VERSION "June 2, 2025"

NS_ :

BS_:

BU_: VEH CH Receiver Receiver ChassisBus VehicleBus PartyBus

BO_ 12 UI_status: 8 VehicleBus
 SG_ UI_audioActive : 1|1@1+ (1,0) [0|1] ""  Receiver
 SG_ UI_autopilotTrial : 12|2@1+ (1,0) [0|3] ""  Receiver
 SG_ UI_bluetoothActive : 2|1@1+ (1,0) [0|1] ""  Receiver
 SG_ UI_cameraActive : 41|1@1+ (1,0) [0|1] ""  Receiver
 SG_ UI_cellActive : 3|1@1+ (1,0) [0|1] ""  Receiver
 SG_ UI_cellConnected : 10|1@1+ (1,0) [0|1] ""  Receiver
 SG_ UI_cellNetworkTechnology : 19|4@1+ (1,0) [0|15] ""  Receiver
 SG_ UI_cellReceiverPower : 24|8@1+ (1,-128) [-128|127] "dB"  Receiver
 SG_ UI_cellSignalBars : 42|3@1+ (1,0) [0|7] ""  Receiver
 SG_ UI_cpuTemperature : 56|8@1- (1,40) [-20|100] "C"  Receiver
 SG_ UI_developmentCar : 40|1@1+ (1,0) [0|1] ""  Receiver
 SG_ UI_displayOn : 5|1@1+ (1,0) [0|1] ""  Receiver
 SG_ UI_displayReady : 4|1@1+ (1,0) [0|1] ""  Receiver
 SG_ UI_factoryReset : 14|2@1+ (1,0) [0|3] ""  Receiver
 SG_ UI_falseTouchCounter : 32|8@1+ (1,0) [0|255] "1"  Receiver
 SG_ UI_gpsActive : 16|1@1+ (1,0) [0|1] ""  Receiver
 SG_ UI_pcbTemperature : 48|8@1- (1,40) [-20|100] "C"  Receiver
 SG_ UI_radioActive : 18|1@1+ (1,0) [0|1] ""  Receiver
 SG_ UI_readyForDrive : 9|1@1+ (1,0) [0|1] ""  Receiver
 SG_ UI_screenshotActive : 17|1@1+ (1,0) [0|1] ""  Receiver
 SG_ UI_systemActive : 8|1@1+ (1,0) [0|1] ""  Receiver
 SG_ UI_touchActive : 0|1@1+ (1,0) [0|1] ""  Receiver
 SG_ UI_vpnActive : 11|1@1+ (1,0) [0|1] ""  Receiver
 SG_ UI_wifiActive : 6|1@1+ (1,0) [0|1] ""  Receiver
 SG_ UI_wifiConnected : 7|1@1+ (1,0) [0|1] ""  Receiver

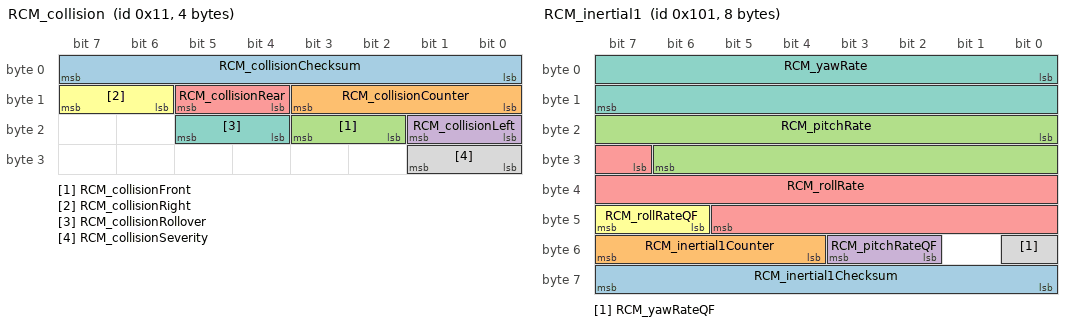
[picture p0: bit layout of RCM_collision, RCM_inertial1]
BO_ 17 RCM_collision: 4 VEH
 SG_ RCM_collisionChecksum : 0|8@1+ (1,0) [0|0] "" Vector__XXX
 SG_ RCM_collisionCounter : 8|4@1+ (1,0) [0|0] "" Vector__XXX
 SG_ RCM_collisionFront : 18|2@1+ (1,0) [0|0] "" Vector__XXX
 SG_ RCM_collisionLeft : 16|2@1+ (1,0) [0|0] "" Vector__XXX
 SG_ RCM_collisionRear : 12|2@1+ (1,0) [0|0] "" Vector__XXX
 SG_ RCM_collisionRight : 14|2@1+ (1,0) [0|0] "" Vector__XXX
 SG_ RCM_collisionRollover : 20|2@1+ (1,0) [0|0] "" Vector__XXX
 SG_ RCM_collisionSeverity : 24|2@1+ (1,0) [0|0] "" Vector__XXX

BO_ 22 DI_bmsRequest: 1 VEH
 SG_ DI_bmsOpenContactorsRequest : 4|1@1+ (1,0) [0|1] ""  Receiver
 SG_ DI_bmsRequestInterfaceVersion : 0|4@1+ (1,0) [0|15] ""  Receiver

BO_ 60 GTW_info: 8 VEH
 SG_ GTW_infoIndex M : 0|8@1+ (1,0) [0|0] "" Vector__XXX
 SG_ GTW_applicationGitHash m17 : 10|54@1+ (4,0) [0|0] "" Vector__XXX
 SG_ GTW_buildType m10 : 8|3@1+ (1,0) [0|0] "" Vector__XXX
 SG_ GTW_hardwareId m10 : 32|16@1+ (1,0) [0|0] "" Vector__XXX
 SG_ GTW_bootGitHash m18 : 10|54@1+ (4,0) [0|0] "" Vector__XXX
 SG_ GTW_bootCrc m20 : 32|32@1+ (1,0) [0|0] "" Vector__XXX
 SG_ GTW_platformType m13 : 8|8@1+ (1,0) [0|0] "" Vector__XXX
 SG_ GTW_appCrc m13 : 32|32@1+ (1,0) [0|0] "" Vector__XXX

BO_ 62 GTW_alertMatrix: 8 VEH
 SG_ GTW_matrixIndex M : 0|4@1+ (1,0) [0|0] "" Vector__XXX
 SG_ GTW_w000_GTW_ALERT_DO_NOT_USE m0 : 4|1@1+ (1,0) [0|0] "" Vector__XXX
 SG_ GTW_w001_canVEHTxQueue m0 : 5|1@1+ (1,0) [0|0] "" Vector__XXX
 SG_ GTW_w002_taskError m0 : 6|1@1+ (1,0) [0|0] "" Vector__XXX
 SG_ GTW_w003_logWriteRecord m0 : 7|1@1+ (1,0) [0|0] "" Vector__XXX
 SG_ GTW_w004_mallocHook m0 : 8|1@1+ (1,0) [0|0] "" Vector__XXX
 SG_ GTW_w005_stackOverflowHook m0 : 9|1@1+ (1,0) [0|0] "" Vector__XXX
 SG_ GTW_w006_ifTxOutputFull m0 : 10|1@1+ (1,0) [0|0] "" Vector__XXX
 SG_ GTW_w007_ifRxBufError m0 : 11|1@1+ (1,0) [0|0] "" Vector__XXX
 SG_ GTW_w008_ifPbufAllocError m0 : 12|1@1+ (1,0) [0|0] "" Vector__XXX
 SG_ GTW_w009_lateTask m0 : 13|1@1+ (1,0) [0|0] "" Vector__XXX
 SG_ GTW_w010_wdTaskCount m0 : 14|1@1+ (1,0) [0|0] "" Vector__XXX
 SG_ GTW_w011_cancoreWatchdog m0 : 15|1@1+ (1,0) [0|0] "" Vector__XXX
 SG_ GTW_w012_maincoreWatchdog m0 : 16|1@1+ (1,0) [0|0] "" Vector__XXX
 SG_ GTW_w014_APSversionMismatch m0 : 17|1@1+ (1,0) [0|0] "" Vector__XXX
 SG_ GTW_w015_DISversionMismatch m0 : 18|1@1+ (1,0) [0|0] "" Vector__XXX
 SG_ GTW_w016_BLEEPversionMismatch m0 : 19|1@1+ (1,0) [0|0] "" Vector__XXX
 SG_ GTW_w017_BMSversionMismatch m0 : 20|1@1+ (1,0) [0|0] "" Vector__XXX
 SG_ GTW_w018_CMPversionMismatch m0 : 21|1@1+ (1,0) [0|0] "" Vector__XXX
 SG_ GTW_w019_CPversionMismatch m0 : 22|1@1+ (1,0) [0|0] "" Vector__XXX
 SG_ GTW_w020_DIversionMismatch m0 : 23|1@1+ (1,0) [0|0] "" Vector__XXX
 SG_ GTW_w021_EPAS3PversionMismatch m0 : 24|1@1+ (1,0) [0|0] "" Vector__XXX
 SG_ GTW_w022_EPBLversionMismatch m0 : 25|1@1+ (1,0) [0|0] "" Vector__XXX
 SG_ GTW_w023_EPBRversionMismatch m0 : 26|1@1+ (1,0) [0|0] "" Vector__XXX
 SG_ GTW_w024_ESPversionMismatch m0 : 27|1@1+ (1,0) [0|0] "" Vector__XXX
 SG_ GTW_w025_ESPCALversionMismatch m0 : 28|1@1+ (1,0) [0|0] "" Vector__XXX
 SG_ GTW_w026_GTWversionMismatch m0 : 29|1@1+ (1,0) [0|0] "" Vector__XXX
 SG_ GTW_w027_HVPversionMismatch m0 : 30|1@1+ (1,0) [0|0] "" Vector__XXX
 SG_ GTW_w028_IBSTversionMismatch m0 : 31|1@1+ (1,0) [0|0] "" Vector__XXX
 SG_ GTW_w029_IBSTCALversionMismatch m0 : 32|1@1+ (1,0) [0|0] "" Vector__XXX
 SG_ GTW_w030_OCS1PversionMismatch m0 : 33|1@1+ (1,0) [0|0] "" Vector__XXX
 SG_ GTW_w031_PARKversionMismatch m0 : 34|1@1+ (1,0) [0|0] "" Vector__XXX
 SG_ GTW_w032_PCSversionMismatch m0 : 35|1@1+ (1,0) [0|0] "" Vector__XXX
 SG_ GTW_w033_PCSCPU2versionMismatch m0 : 36|1@1+ (1,0) [0|0] "" Vector__XXX
 SG_ GTW_w034_PMversionMismatch m0 : 37|1@1+ (1,0) [0|0] "" Vector__XXX
 SG_ GTW_w035_PMSversionMismatch m0 : 38|1@1+ (1,0) [0|0] "" Vector__XXX
 SG_ GTW_w036_PTCversionMismatch m0 : 39|1@1+ (1,0) [0|0] "" Vector__XXX
 SG_ GTW_w037_RADCversionMismatch m0 : 40|1@1+ (1,0) [0|0] "" Vector__XXX
 SG_ GTW_w038_RCMversionMismatch m0 : 41|1@1+ (1,0) [0|0] "" Vector__XXX
 SG_ GTW_w039_RCMCALversionMismatch m0 : 42|1@1+ (1,0) [0|0] "" Vector__XXX
 SG_ GTW_w040_SCCMversionMismatch m0 : 43|1@1+ (1,0) [0|0] "" Vector__XXX
 SG_ GTW_w041_VCSECversionMismatch m0 : 44|1@1+ (1,0) [0|0] "" Vector__XXX
 SG_ GTW_w042_TASversionMismatch m0 : 45|1@1+ (1,0) [0|0] "" Vector__XXX
 SG_ GTW_w043_THSversionMismatch m0 : 46|1@1+ (1,0) [0|0] "" Vector__XXX
 SG_ GTW_w044_TPMSversionMismatch m0 : 47|1@1+ (1,0) [0|0] "" Vector__XXX
 SG_ GTW_w045_VCFRONTversionMismatch m0 : 48|1@1+ (1,0) [0|0] "" Vector__XXX
 SG_ GTW_w046_VCLEFTversionMismatch m0 : 49|1@1+ (1,0) [0|0] "" Vector__XXX
 SG_ GTW_w047_VCRIGHTversionMismatch m0 : 50|1@1+ (1,0) [0|0] "" Vector__XXX
 SG_ GTW_w048_EPAS3SversionMismatch m0 : 51|1@1+ (1,0) [0|0] "" Vector__XXX
 SG_ GTW_w049_corruptedManifest m0 : 52|1@1+ (1,0) [0|0] "" Vector__XXX
 SG_ GTW_w050_sdCardInitFailure m0 : 53|1@1+ (1,0) [0|0] "" Vector__XXX
 SG_ GTW_w051_sdCardFileSystemFailure m0 : 54|1@1+ (1,0) [0|0] "" Vector__XXX
 SG_ GTW_w052_ifTxSpans m0 : 55|1@1+ (1,0) [0|0] "" Vector__XXX
 SG_ GTW_w053_busSleepFailure m0 : 56|1@1+ (1,0) [0|0] "" Vector__XXX
 SG_ GTW_w054_OPCversionMismatch m0 : 57|1@1+ (1,0) [0|0] "" Vector__XXX
 SG_ GTW_w055_OPCSversionMismatch m0 : 58|1@1+ (1,0) [0|0] "" Vector__XXX
 SG_ GTW_w057_i2cFailure m0 : 59|1@1+ (1,0) [0|0] "" Vector__XXX
 SG_ GTW_w058_rtcAlarmFailure m0 : 60|1@1+ (1,0) [0|0] "" Vector__XXX
 SG_ GTW_w059_inFactoryMode m0 : 61|1@1+ (1,0) [0|0] "" Vector__XXX
 SG_ GTW_w060_unFused m0 : 62|1@1+ (1,0) [0|0] "" Vector__XXX
 SG_ GTW_w061_bmpSleepFailure m0 : 63|1@1+ (1,0) [0|0] "" Vector__XXX
 SG_ GTW_w062_bmpWatchdog m1 : 4|1@1+ (1,0) [0|0] "" Vector__XXX
 SG_ GTW_w063_VEH_canFault m1 : 5|1@1+ (1,0) [0|0] "" Vector__XXX
 SG_ GTW_w064_CH_canFault m1 : 6|1@1+ (1,0) [0|0] "" Vector__XXX
 SG_ GTW_w065_PARTY_canFault m1 : 7|1@1+ (1,0) [0|0] "" Vector__XXX
 SG_ GTW_w066_exception m1 : 8|1@1+ (1,0) [0|0] "" Vector__XXX
 SG_ GTW_w067_tcpDebug m1 : 9|1@1+ (1,0) [0|0] "" Vector__XXX
 SG_ GTW_w068_prodKeyMissing m1 : 10|1@1+ (1,0) [0|0] "" Vector__XXX
 SG_ GTW_w069_diskioErr m1 : 11|1@1+ (1,0) [0|0] "" Vector__XXX
 SG_ GTW_w070_hrlDump m1 : 12|1@1+ (1,0) [0|0] "" Vector__XXX
 SG_ GTW_w071_hrlTrigger m1 : 13|1@1+ (1,0) [0|0] "" Vector__XXX
 SG_ GTW_w072_updateFailure m1 : 14|1@1+ (1,0) [0|0] "" Vector__XXX
 SG_ GTW_w073_steeringWheelReset m1 : 15|1@1+ (1,0) [0|0] "" Vector__XXX
 SG_ GTW_w074_epas3pMIA m1 : 16|1@1+ (1,0) [0|0] "" Vector__XXX
 SG_ GTW_w075_epas3sMIA m1 : 17|1@1+ (1,0) [0|0] "" Vector__XXX
 SG_ GTW_w076_VEHInterfaceReset m1 : 18|1@1+ (1,0) [0|0] "" Vector__XXX
 SG_ GTW_w077_bmpPmicError m1 : 19|1@1+ (1,0) [0|0] "" Vector__XXX
 SG_ GTW_w078_VEHbusOverloaded m1 : 20|1@1+ (1,0) [0|0] "" Vector__XXX
 SG_ GTW_w079_PARTYbusOverloaded m1 : 21|1@1+ (1,0) [0|0] "" Vector__XXX
 SG_ GTW_w080_CHbusOverloaded m1 : 22|1@1+ (1,0) [0|0] "" Vector__XXX
 SG_ GTW_w081_udsMessageRejected m1 : 23|1@1+ (1,0) [0|0] "" Vector__XXX
 SG_ GTW_w082_sdCardBSCorrupted m1 : 24|1@1+ (1,0) [0|0] "" Vector__XXX
 SG_ GTW_w083_udsMsgDroppedByTcpStack m1 : 25|1@1+ (1,0) [0|0] "" Vector__XXX
 SG_ GTW_w084_canFrameDropped m1 : 26|1@1+ (1,0) [0|0] "" Vector__XXX
 SG_ GTW_w085_iBoosterStuck m1 : 27|1@1+ (1,0) [0|0] "" Vector__XXX
 SG_ GTW_w086_ocu m1 : 28|1@1+ (1,0) [0|0] "" Vector__XXX
 SG_ GTW_w087_ocuInProgress m1 : 29|1@1+ (1,0) [0|0] "" Vector__XXX
 SG_ GTW_w088_sdCardInvReqParallel m1 : 30|1@1+ (1,0) [0|0] "" Vector__XXX
 SG_ GTW_w089_sdCardWatchdog m1 : 31|1@1+ (1,0) [0|0] "" Vector__XXX
 SG_ GTW_w090_ocuFailed m1 : 32|1@1+ (1,0) [0|0] "" Vector__XXX
 SG_ GTW_w091_lowStack m1 : 33|1@1+ (1,0) [0|0] "" Vector__XXX
 SG_ GTW_w092_sdCardInvReqZero m1 : 34|1@1+ (1,0) [0|0] "" Vector__XXX
 SG_ GTW_w093_sdCardInvReqOverflowBase m1 : 35|1@1+ (1,0) [0|0] "" Vector__XXX
 SG_ GTW_w094_sdCardInvReqOverflowCount m1 : 36|1@1+ (1,0) [0|0] "" Vector__XXX
 SG_ GTW_w095_sdCardFull m1 : 37|1@1+ (1,0) [0|0] "" Vector__XXX
 SG_ GTW_w096_sdCardFatCorrupted m1 : 38|1@1+ (1,0) [0|0] "" Vector__XXX
 SG_ GTW_w097_HCMLversionMismatch m1 : 39|1@1+ (1,0) [0|0] "" Vector__XXX
 SG_ GTW_w098_HCMRversionMismatch m1 : 40|1@1+ (1,0) [0|0] "" Vector__XXX
 SG_ GTW_w099_SWCversionMismatch m1 : 41|1@1+ (1,0) [0|0] "" Vector__XXX
 SG_ GTW_w100_CBCversionMismatch m1 : 42|1@1+ (1,0) [0|0] "" Vector__XXX
 SG_ GTW_w101_switchWatchdog m1 : 43|1@1+ (1,0) [0|0] "" Vector__XXX
 SG_ GTW_w103_sdCardFormatted m1 : 44|1@1+ (1,0) [0|0] "" Vector__XXX
 SG_ GTW_w104_sdCardDriverArgCorrupted m1 : 45|1@1+ (1,0) [0|0] "" Vector__XXX
 SG_ GTW_w105_eBuckConfigured m1 : 46|1@1+ (1,0) [0|0] "" Vector__XXX
 SG_ GTW_w106_failedToStartUpdater m1 : 47|1@1+ (1,0) [0|0] "" Vector__XXX

BO_ 79 UI_locationStatus: 8 CH
 SG_ UI_gpsAccuracy : 57|7@1+ (0.2,0) [0|0] "m" Vector__XXX
 SG_ UI_gpslatitude : 0|28@1- (1e-06,0) [0|0] "deg" Vector__XXX
 SG_ UI_gpslongitude : 28|29@1- (1e-06,0) [0|0] "deg" Vector__XXX

BO_ 130 UI_tripPlanning: 8 VEH
 SG_ UI_energyAtDestination : 48|16@1- (0.01,0) [-327.67|327.67] "kWh" Vector__XXX
 SG_ UI_hindsightEnergy : 32|16@1- (0.01,0) [-327.67|327.67] "kWh" Vector__XXX
 SG_ UI_navToSupercharger : 1|1@1+ (1,0) [0|1] "" Vector__XXX
 SG_ UI_predictedEnergy : 16|16@1- (0.01,0) [-327.67|327.67] "kWh" Vector__XXX
 SG_ UI_requestActiveBatteryHeating : 2|1@1+ (1,0) [0|1] "" Vector__XXX
 SG_ UI_tripPlanningActive : 0|1@1+ (1,0) [0|1] "" Vector__XXX

BO_ 139 UI_tripPlanning2: 6 VEH
 SG_ UI_maxSpeedToReachDestination : 0|16@1+ (0.01,0) [0|655.34] "m/s" Vector__XXX
 SG_ UI_remainingWeightedRMSSpeed : 16|16@1+ (0.01,0) [0|655.34] "m/s" Vector__XXX
 SG_ UI_timeToDestination : 32|16@1+ (1,0) [0|65534] "s" Vector__XXX

BO_ 257 RCM_inertial1: 8 CH
 SG_ RCM_inertial1Checksum : 56|8@1+ (1,0) [0|0] "" Vector__XXX
 SG_ RCM_inertial1Counter : 52|4@1+ (1,0) [0|0] "" Vector__XXX
 SG_ RCM_pitchRate : 16|15@1- (0.00025,0) [0|0] "rad/s" Vector__XXX
 SG_ RCM_pitchRateQF : 50|2@1+ (1,0) [0|0] "" Vector__XXX
 SG_ RCM_rollRate : 31|15@1- (0.00025,0) [0|0] "rad/s" Vector__XXX
 SG_ RCM_rollRateQF : 46|2@1+ (1,0) [0|0] "" Vector__XXX
 SG_ RCM_yawRate : 0|16@1- (0.0001,0) [0|0] "rad/s" Vector__XXX
 SG_ RCM_yawRateQF : 48|1@1+ (1,0) [0|0] "" Vector__XXX

BO_ 258 VCLEFT_doorStatus: 8 VEH
 SG_ VCLEFT_frontHandlePWM : 16|7@1+ (1,0) [0|0] "%" Vector__XXX
 SG_ VCLEFT_frontHandlePulled : 10|1@1+ (1,0) [0|0] "" Vector__XXX
 SG_ VCLEFT_frontHandlePulledPersist : 62|1@1+ (1,0) [0|0] "" Vector__XXX
 SG_ VCLEFT_frontIntSwitchPressed : 31|1@1+ (1,0) [0|0] "" Vector__XXX
 SG_ VCLEFT_frontLatchStatus : 0|4@1+ (1,0) [0|0] "" Vector__XXX
 SG_ VCLEFT_frontLatchSwitch : 8|1@1+ (1,0) [0|0] "" Vector__XXX
 SG_ VCLEFT_frontRelActuatorSwitch : 12|1@1+ (1,0) [0|0] "" Vector__XXX
 SG_ VCLEFT_mirrorDipped : 61|1@1+ (1,0) [0|0] "" Vector__XXX
 SG_ VCLEFT_mirrorFoldState : 52|3@1+ (1,0) [0|0] "" Vector__XXX
 SG_ VCLEFT_mirrorHeatState : 58|3@1+ (1,0) [0|0] "" Vector__XXX
 SG_ VCLEFT_mirrorRecallState : 55|3@1+ (1,0) [0|0] "" Vector__XXX
 SG_ VCLEFT_mirrorState : 49|3@1+ (1,0) [0|0] "" Vector__XXX
 SG_ VCLEFT_mirrorTiltXPosition : 33|8@1+ (0.02,0) [0|0] "V" Vector__XXX
 SG_ VCLEFT_mirrorTiltYPosition : 41|8@1+ (0.02,0) [0|0] "V" Vector__XXX
 SG_ VCLEFT_rearHandlePWM : 24|7@1+ (1,0) [0|0] "%" Vector__XXX
 SG_ VCLEFT_rearHandlePulled : 11|1@1+ (1,0) [0|0] "" Vector__XXX
 SG_ VCLEFT_rearIntSwitchPressed : 32|1@1+ (1,0) [0|0] "" Vector__XXX
 SG_ VCLEFT_rearLatchStatus : 4|4@1+ (1,0) [0|0] "" Vector__XXX
 SG_ VCLEFT_rearLatchSwitch : 9|1@1+ (1,0) [0|0] "" Vector__XXX
 SG_ VCLEFT_rearRelActuatorSwitch : 13|1@1+ (1,0) [0|0] "" Vector__XXX

BO_ 259 VCRIGHT_doorStatus: 8 VEH
 SG_ VCRIGHT_frontHandlePWM : 14|7@1+ (1,0) [0|0] "%" Vector__XXX
 SG_ VCRIGHT_frontHandlePulled : 10|1@1+ (1,0) [0|0] "" Vector__XXX
 SG_ VCRIGHT_frontHandlePulledPersist : 30|1@1+ (1,0) [0|0] "" Vector__XXX
 SG_ VCRIGHT_frontIntSwitchPressed : 31|1@1+ (1,0) [0|0] "" Vector__XXX
 SG_ VCRIGHT_frontLatchStatus : 0|4@1+ (1,0) [0|0] "" Vector__XXX
 SG_ VCRIGHT_frontLatchSwitch : 8|1@1+ (1,0) [0|0] "" Vector__XXX
 SG_ VCRIGHT_frontRelActuatorSwitch : 12|1@1+ (1,0) [0|0] "" Vector__XXX
 SG_ VCRIGHT_mirrorDipped : 63|1@1+ (1,0) [0|0] "" Vector__XXX
 SG_ VCRIGHT_mirrorFoldState : 52|3@1+ (1,0) [0|0] "" Vector__XXX
 SG_ VCRIGHT_mirrorRecallState : 60|3@1+ (1,0) [0|0] "" Vector__XXX
 SG_ VCRIGHT_mirrorState : 49|3@1+ (1,0) [0|0] "" Vector__XXX
 SG_ VCRIGHT_mirrorTiltXPosition : 33|8@1+ (0.02,0) [0|0] "V" Vector__XXX
 SG_ VCRIGHT_mirrorTiltYPosition : 41|8@1+ (0.02,0) [0|0] "V" Vector__XXX
 SG_ VCRIGHT_rearHandlePWM : 21|7@1+ (1,0) [0|0] "%" Vector__XXX
 SG_ VCRIGHT_rearHandlePulled : 11|1@1+ (1,0) [0|0] "" Vector__XXX
 SG_ VCRIGHT_rearIntSwitchPressed : 32|1@1+ (1,0) [0|0] "" Vector__XXX
 SG_ VCRIGHT_rearLatchStatus : 4|4@1+ (1,0) [0|0] "" Vector__XXX
 SG_ VCRIGHT_rearLatchSwitch : 9|1@1+ (1,0) [0|0] "" Vector__XXX
 SG_ VCRIGHT_rearRelActuatorSwitch : 13|1@1+ (1,0) [0|0] "" Vector__XXX
 SG_ VCRIGHT_reservedForBackCompat : 28|2@1+ (1,0) [0|0] "" Vector__XXX
 SG_ VCRIGHT_trunkLatchStatus : 56|4@1+ (1,0) [0|0] "" Vector__XXX

BO_ 264 DI_torque: 8 VEH
 SG_ DI_axleSpeed : 40|16@1- (0.1,0) [0|0] "RPM" Vector__XXX
 SG_ DI_torqueActual : 27|13@1- (2,0) [0|0] "Nm" Vector__XXX
 SG_ DI_torqueChecksum : 0|8@1+ (1,0) [0|0] "" Vector__XXX
 SG_ DI_torqueCommand : 12|13@1- (2,0) [0|0] "Nm" Vector__XXX
 SG_ DI_torqueCounter : 8|4@1+ (1,0) [0|0] "" Vector__XXX
 SG_ DI_slavePedalPos : 56|8@1+ (0.4,0) [0|100] "%" Vector__XXX

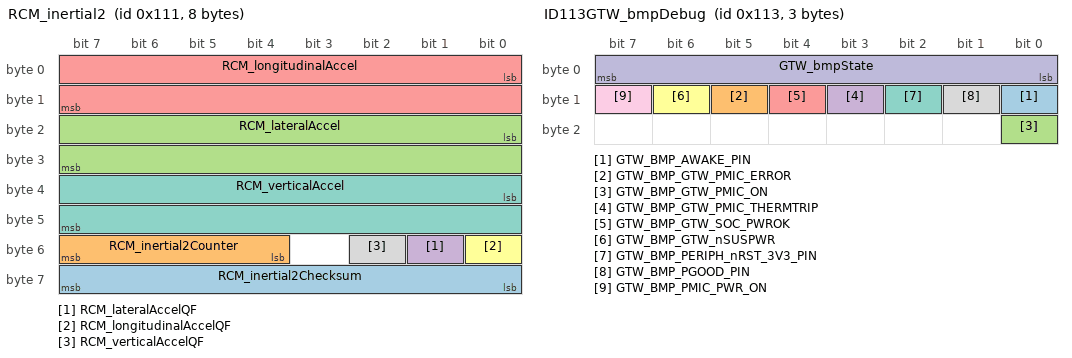
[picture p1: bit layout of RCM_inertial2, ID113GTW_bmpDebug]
BO_ 273 RCM_inertial2: 8 CH
 SG_ RCM_inertial2Checksum : 56|8@1+ (1,0) [0|255] "" Vector__XXX
 SG_ RCM_inertial2Counter : 52|4@1+ (1,0) [0|15] "" Vector__XXX
 SG_ RCM_lateralAccel : 16|16@1- (0.00125,0) [-40.9575|40.9575] "m/s^2" Vector__XXX
 SG_ RCM_lateralAccelQF : 49|1@1+ (1,0) [0|1] "" Vector__XXX
 SG_ RCM_longitudinalAccel : 0|16@1- (0.00125,0) [-40.9575|40.9575] "m/s^2" Vector__XXX
 SG_ RCM_longitudinalAccelQF : 48|1@1+ (1,0) [0|1] "" Vector__XXX
 SG_ RCM_verticalAccel : 32|16@1- (0.00125,0) [-40.9575|40.9575] "m/s^2" Vector__XXX
 SG_ RCM_verticalAccelQF : 50|1@1+ (1,0) [0|1] "" Vector__XXX

BO_ 274 GTW_adc1: 8 VEH
 SG_ GTW_1V1_VEH : 24|12@0+ (1,0) [0|0] "mV" Vector__XXX
 SG_ GTW_1V5_VEH : 32|12@0+ (1,0) [0|0] "mV" Vector__XXX
 SG_ GTW_3V3_VEH : 0|12@0+ (1.03,0) [0|0] "mV" Vector__XXX
 SG_ GTW_3V3_SW : 8|12@0+ (1.5,0) [0|0] "mV" Vector__XXX
 SG_ GTW_5V0_SW : 48|12@0+ (2,0) [0|0] "mV" Vector__XXX

BO_ 275 ID113GTW_bmpDebug: 3 VehicleBus
 SG_ GTW_BMP_AWAKE_PIN : 8|1@1+ (1,0) [0|1] ""  Receiver
 SG_ GTW_BMP_GTW_PMIC_ERROR : 13|1@1+ (1,0) [0|1] ""  Receiver
 SG_ GTW_BMP_GTW_PMIC_ON : 16|1@1+ (1,0) [0|1] ""  Receiver
 SG_ GTW_BMP_GTW_PMIC_THERMTRIP : 11|1@1+ (1,0) [0|1] ""  Receiver
 SG_ GTW_BMP_GTW_SOC_PWROK : 12|1@1+ (1,0) [0|1] ""  Receiver
 SG_ GTW_BMP_GTW_nSUSPWR : 14|1@1+ (1,0) [0|1] ""  Receiver
 SG_ GTW_BMP_PERIPH_nRST_3V3_PIN : 10|1@1+ (1,0) [0|1] ""  Receiver
 SG_ GTW_BMP_PGOOD_PIN : 9|1@1+ (1,0) [0|1] ""  Receiver
 SG_ GTW_BMP_PMIC_PWR_ON : 15|1@1+ (1,0) [0|1] ""  Receiver
 SG_ GTW_bmpState : 7|8@0+ (1,0) [0|255] ""  Receiver

BO_ 276 GTW_adc3: 8 VEH
 SG_ GTW_1V2_CSI : 24|12@0+ (1,0) [0|0] "mV" Vector__XXX
 SG_ GTW_1V8_VID : 8|12@0+ (1,0) [0|0] "mV" Vector__XXX
 SG_ GTW_1V8_VIO : 0|12@0+ (2,0) [0|0] "mV" Vector__XXX
 SG_ GTW_3V3_BMP : 32|12@0+ (2,0) [0|0] "mV" Vector__XXX
 SG_ GTW_GSM_BRD_REV : 48|12@0+ (1,0) [0|0] "mV" Vector__XXX

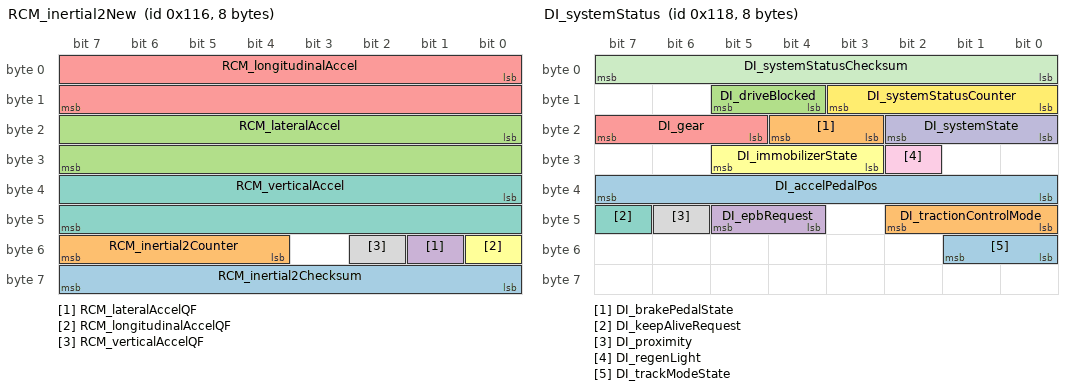
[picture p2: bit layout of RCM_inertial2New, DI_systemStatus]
BO_ 278 RCM_inertial2New: 8 CH
 SG_ RCM_inertial2Checksum : 56|8@1+ (1,0) [0|255] ""  Receiver
 SG_ RCM_inertial2Counter : 52|4@1+ (1,0) [0|15] ""  Receiver
 SG_ RCM_lateralAccel : 16|16@1- (0.00125,0) [-40.9575|40.9575] "m/s^2"  Receiver
 SG_ RCM_lateralAccelQF : 49|1@1+ (1,0) [0|1] ""  Receiver
 SG_ RCM_longitudinalAccel : 0|16@1- (0.00125,0) [-40.9575|40.9575] "m/s^2"  Receiver
 SG_ RCM_longitudinalAccelQF : 48|1@1+ (1,0) [0|1] ""  Receiver
 SG_ RCM_verticalAccel : 32|16@1- (0.00125,0) [-40.9575|40.9575] "m/s^2"  Receiver
 SG_ RCM_verticalAccelQF : 50|1@1+ (1,0) [0|1] ""  Receiver

BO_ 280 DI_systemStatus: 8 VEH
 SG_ DI_accelPedalPos : 32|8@1+ (0.4,0) [0|0] "%" Vector__XXX
 SG_ DI_brakePedalState : 19|2@1+ (1,0) [0|0] "" Vector__XXX
 SG_ DI_driveBlocked : 12|2@1+ (1,0) [0|2] "" Vector__XXX
 SG_ DI_epbRequest : 44|2@1+ (1,0) [0|0] "" Vector__XXX
 SG_ DI_gear : 21|3@1+ (1,0) [0|0] "" Vector__XXX
 SG_ DI_immobilizerState : 27|3@1+ (1,0) [0|0] "" Vector__XXX
 SG_ DI_keepAliveRequest : 47|1@1+ (1,0) [0|0] "" Vector__XXX
 SG_ DI_proximity : 46|1@1+ (1,0) [0|0] "" Vector__XXX
 SG_ DI_regenLight : 26|1@1+ (1,0) [0|0] "" Vector__XXX
 SG_ DI_systemState : 16|3@1+ (1,0) [0|0] "" Vector__XXX
 SG_ DI_systemStatusChecksum : 0|8@1+ (1,0) [0|0] "" Vector__XXX
 SG_ DI_systemStatusCounter : 8|4@1+ (1,0) [0|0] "" Vector__XXX
 SG_ DI_trackModeState : 48|2@1+ (1,0) [0|0] "" Vector__XXX
 SG_ DI_tractionControlMode : 40|3@1+ (1,0) [0|0] "" Vector__XXX

BO_ 281 GTW_busLoadInfo: 3 VEH
 SG_ GTW_CHbusLoadPercent : 16|7@1+ (1,0) [0|0] "percent" Vector__XXX
 SG_ GTW_PARTYbusLoadPercent : 8|7@1+ (1,0) [0|0] "percent" Vector__XXX
 SG_ GTW_VEHbusLoadPercent : 0|7@1+ (1,0) [0|0] "percent" Vector__XXX

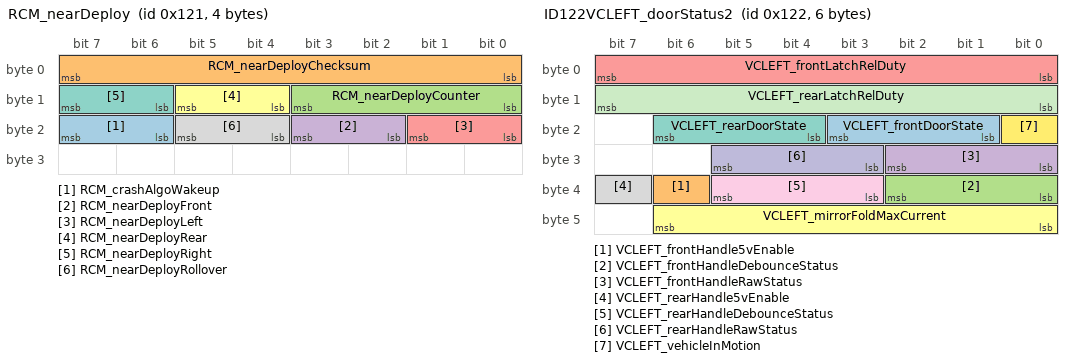
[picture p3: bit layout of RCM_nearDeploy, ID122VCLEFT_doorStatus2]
BO_ 289 RCM_nearDeploy: 4 VEH
 SG_ RCM_crashAlgoWakeup : 22|2@1+ (1,0) [0|0] "" Vector__XXX
 SG_ RCM_nearDeployChecksum : 0|8@1+ (1,0) [0|0] "" Vector__XXX
 SG_ RCM_nearDeployCounter : 8|4@1+ (1,0) [0|0] "" Vector__XXX
 SG_ RCM_nearDeployFront : 18|2@1+ (1,0) [0|0] "" Vector__XXX
 SG_ RCM_nearDeployLeft : 16|2@1+ (1,0) [0|0] "" Vector__XXX
 SG_ RCM_nearDeployRear : 12|2@1+ (1,0) [0|0] "" Vector__XXX
 SG_ RCM_nearDeployRight : 14|2@1+ (1,0) [0|0] "" Vector__XXX
 SG_ RCM_nearDeployRollover : 20|2@1+ (1,0) [0|0] "" Vector__XXX

BO_ 290 ID122VCLEFT_doorStatus2: 6 VehicleBus
 SG_ VCLEFT_frontDoorState : 17|3@1+ (1,0) [0|4] ""  Receiver
 SG_ VCLEFT_frontHandle5vEnable : 38|1@1+ (1,0) [0|1] ""  Receiver
 SG_ VCLEFT_frontHandleDebounceStatus : 32|3@1+ (1,0) [0|5] ""  Receiver
 SG_ VCLEFT_frontHandleRawStatus : 24|3@1+ (1,0) [0|5] ""  Receiver
 SG_ VCLEFT_frontLatchRelDuty : 0|8@1+ (1,0) [0|255] "%"  Receiver
 SG_ VCLEFT_mirrorFoldMaxCurrent : 40|7@1- (0.046,0) [-2.944|2.898] "A"  Receiver
 SG_ VCLEFT_rearDoorState : 20|3@1+ (1,0) [0|4] ""  Receiver
 SG_ VCLEFT_rearHandle5vEnable : 39|1@1+ (1,0) [0|1] ""  Receiver
 SG_ VCLEFT_rearHandleDebounceStatus : 35|3@1+ (1,0) [0|5] ""  Receiver
 SG_ VCLEFT_rearHandleRawStatus : 27|3@1+ (1,0) [0|5] ""  Receiver
 SG_ VCLEFT_rearLatchRelDuty : 8|8@1+ (1,0) [0|255] "%"  Receiver
 SG_ VCLEFT_vehicleInMotion : 16|1@1+ (1,0) [0|1] ""  Receiver

BO_ 291 UI_alertMatrix1: 8 VEH
 SG_ UI_a001_DriverDoorOpen : 0|1@1+ (1,0) [0|0] "" Vector__XXX
 SG_ UI_a002_DoorOpen : 1|1@1+ (1,0) [0|0] "" Vector__XXX
 SG_ UI_a003_TrunkOpen : 2|1@1+ (1,0) [0|0] "" Vector__XXX
 SG_ UI_a004_FrunkOpen : 3|1@1+ (1,0) [0|0] "" Vector__XXX
 SG_ UI_a005_HeadlightsOnDoorOpen : 4|1@1+ (1,0) [0|0] "" Vector__XXX
 SG_ UI_a006_RemoteServiceAlert : 5|1@1+ (1,0) [0|0] "" Vector__XXX
 SG_ UI_a007_SoftPackConfigMismatch : 6|1@1+ (1,0) [0|0] "" Vector__XXX
 SG_ UI_a008_TouchScreenError : 7|1@1+ (1,0) [0|0] "" Vector__XXX
 SG_ UI_a009_SquashfsError : 8|1@1+ (1,0) [0|0] "" Vector__XXX
 SG_ UI_a010_MapsMissing : 9|1@1+ (1,0) [0|0] "" Vector__XXX
 SG_ UI_a011_IncorrectMap : 10|1@1+ (1,0) [0|0] "" Vector__XXX
 SG_ UI_a012_NotOnPrivateProperty : 11|1@1+ (1,0) [0|0] "" Vector__XXX
 SG_ UI_a013_TPMSHardWarning : 12|1@1+ (1,0) [0|0] "" Vector__XXX
 SG_ UI_a014_TPMSSoftWarning : 13|1@1+ (1,0) [0|0] "" Vector__XXX
 SG_ UI_a015_TPMSOverPressureWarning : 14|1@1+ (1,0) [0|0] "" Vector__XXX
 SG_ UI_a016_TPMSTemperatureWarning : 15|1@1+ (1,0) [0|0] "" Vector__XXX
 SG_ UI_a017_TPMSSystemFault : 16|1@1+ (1,0) [0|0] "" Vector__XXX
 SG_ UI_a018_SlipStartOn : 17|1@1+ (1,0) [0|0] "" Vector__XXX
 SG_ UI_a019_ParkBrakeFault : 18|1@1+ (1,0) [0|0] "" Vector__XXX
 SG_ UI_a020_SteeringReduced : 19|1@1+ (1,0) [0|0] "" Vector__XXX
 SG_ UI_a021_RearSeatbeltUnbuckled : 20|1@1+ (1,0) [0|0] "" Vector__XXX
 SG_ UI_a022_ApeFusesEtc : 21|1@1+ (1,0) [0|0] "" Vector__XXX
 SG_ UI_a023_CellInternetCheckFailed : 22|1@1+ (1,0) [0|0] "" Vector__XXX
 SG_ UI_a024_WifiInternetCheckFailed : 23|1@1+ (1,0) [0|0] "" Vector__XXX
 SG_ UI_a025_WifiOnlineCheckFailed : 24|1@1+ (1,0) [0|0] "" Vector__XXX
 SG_ UI_a026_ModemResetLoopDetected : 25|1@1+ (1,0) [0|0] "" Vector__XXX
 SG_ UI_a027_AutoSteerMIA : 26|1@1+ (1,0) [0|0] "" Vector__XXX
 SG_ UI_a028_FrontTrunkPopupClosed : 27|1@1+ (1,0) [0|0] "" Vector__XXX
 SG_ UI_a029_ModemMIA : 28|1@1+ (1,0) [0|0] "" Vector__XXX
 SG_ UI_a030_ModemVMCrash : 29|1@1+ (1,0) [0|0] "" Vector__XXX
 SG_ UI_a031_BrakeFluidLow : 30|1@1+ (1,0) [0|0] "" Vector__XXX
 SG_ UI_a032_CellModemRecoveryResets : 31|1@1+ (1,0) [0|0] "" Vector__XXX
 SG_ UI_a033_ApTrialExpired : 32|1@1+ (1,0) [0|0] "" Vector__XXX
 SG_ UI_a034_WakeupProblem : 33|1@1+ (1,0) [0|0] "" Vector__XXX
 SG_ UI_a035_AudioWatchdogKernelError : 34|1@1+ (1,0) [0|0] "" Vector__XXX
 SG_ UI_a036_AudioWatchdogHfpError : 35|1@1+ (1,0) [0|0] "" Vector__XXX
 SG_ UI_a037_AudioWatchdogXrunStormError : 36|1@1+ (1,0) [0|0] "" Vector__XXX
 SG_ UI_a038_AudioWatchdogA2bI2cLockupError : 37|1@1+ (1,0) [0|0] "" Vector__XXX
 SG_ UI_a039_AudioA2bNeedRediscovery : 38|1@1+ (1,0) [0|0] "" Vector__XXX
 SG_ UI_a040_HomelinkTransmit : 39|1@1+ (1,0) [0|0] "" Vector__XXX
 SG_ UI_a041_AudioDmesgXrun : 40|1@1+ (1,0) [0|0] "" Vector__XXX
 SG_ UI_a042_AudioDmesgRtThrottling : 41|1@1+ (1,0) [0|0] "" Vector__XXX
 SG_ UI_a043_InvalidMapDataOverride : 42|1@1+ (1,0) [0|0] "" Vector__XXX
 SG_ UI_a044_AudioDmesgDspException : 43|1@1+ (1,0) [0|0] "" Vector__XXX
 SG_ UI_a045_ECallNeedsService : 44|1@1+ (1,0) [0|1] ""  Receiver
 SG_ UI_a046_BackupCameraStreamError : 45|1@1+ (1,0) [0|1] ""  Receiver
 SG_ UI_a047_CellRoamingDisallowed : 46|1@1+ (1,0) [0|1] ""  Receiver
 SG_ UI_a048_AudioPremiumAmpCheckFail : 47|1@1+ (1,0) [0|1] ""  Receiver
 SG_ UI_a049_BrakeShiftRequired : 48|1@1+ (1,0) [0|1] ""  Receiver
 SG_ UI_a050_BackupCameraIPUTimeout : 49|1@1+ (1,0) [0|1] ""  Receiver
 SG_ UI_a051_BackupCameraFrameTimeout : 50|1@1+ (1,0) [0|1] ""  Receiver
 SG_ UI_a052_KernelPanicReported : 51|1@1+ (1,0) [0|1] ""  Receiver
 SG_ UI_a053_QtCarExitError : 52|1@1+ (1,0) [0|1] ""  Receiver
 SG_ UI_a054_AudioBoostPowerBad : 53|1@1+ (1,0) [0|1] ""  Receiver
 SG_ UI_a055_ManualECallDisabled : 54|1@1+ (1,0) [0|1] ""  Receiver
 SG_ UI_a056_ManualECallButtonDisconn : 55|1@1+ (1,0) [0|1] ""  Receiver
 SG_ UI_a057_CellAntennaDisconnected : 56|1@1+ (1,0) [0|1] ""  Receiver
 SG_ UI_a058_GPSAntennaDisconnected : 57|1@1+ (1,0) [0|1] ""  Receiver
 SG_ UI_a059_ECallSpeakerDisconnected : 58|1@1+ (1,0) [0|1] ""  Receiver
 SG_ UI_a060_ECallMicDisconnected : 59|1@1+ (1,0) [0|1] ""  Receiver
 SG_ UI_a061_SIMTestFailed : 60|1@1+ (1,0) [0|1] ""  Receiver
 SG_ UI_a062_ENSTestFailed : 61|1@1+ (1,0) [0|1] ""  Receiver
 SG_ UI_a063_CellularTestFailed : 62|1@1+ (1,0) [0|1] ""  Receiver
 SG_ UI_a064_ModemFirmwareTestFailed : 63|1@1+ (1,0) [0|1] ""  Receiver

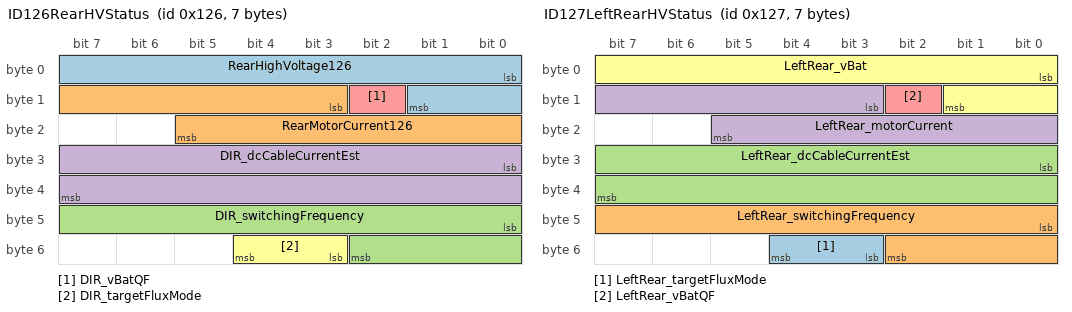
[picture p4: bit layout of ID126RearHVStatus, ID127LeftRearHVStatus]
BO_ 294 ID126RearHVStatus: 7 VehicleBus
 SG_ RearHighVoltage126 : 0|10@1+ (0.5,0) [0|500] "V"  Receiver
 SG_ RearMotorCurrent126 : 11|11@1+ (1,0) [0|2047] "A"  Receiver
 SG_ DIR_switchingFrequency : 40|11@1+ (0.01,0) [0|20] "kHz"  Receiver
 SG_ DIR_dcCableCurrentEst : 24|16@1- (0.1,0) [-3276.8|3276.7] "A"  Receiver
 SG_ DIR_vBatQF : 10|1@1+ (1,0) [0|1] ""  Receiver
 SG_ DIR_targetFluxMode : 51|2@1+ (1,0) [0|0] ""  Receiver

BO_ 295 ID127LeftRearHVStatus: 7 VehicleBus
 SG_ LeftRear_targetFluxMode : 51|2@1+ (1,0) [0|0] ""  Receiver
 SG_ LeftRear_switchingFrequency : 40|11@1+ (0.01,0) [0|0] "kHz"  Receiver
 SG_ LeftRear_dcCableCurrentEst : 24|16@1- (0.1,0) [0|0] "A"  Receiver
 SG_ LeftRear_motorCurrent : 11|11@1+ (1,0) [0|0] "A"  Receiver
 SG_ LeftRear_vBatQF : 10|1@1+ (1,0) [0|0] ""  Receiver
 SG_ LeftRear_vBat : 0|10@1+ (0.5,0) [0|0] "V"  Receiver

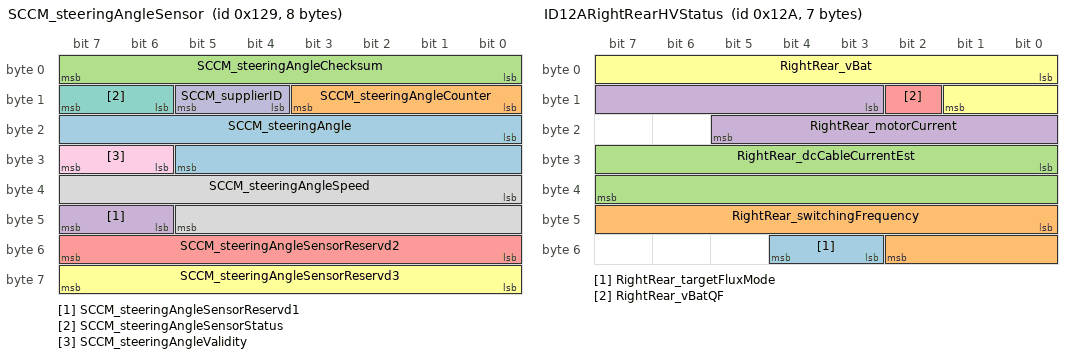
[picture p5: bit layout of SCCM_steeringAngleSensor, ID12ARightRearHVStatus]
BO_ 297 SCCM_steeringAngleSensor: 8 VEH
 SG_ SCCM_steeringAngle : 16|14@1+ (0.1,-819.2) [0|0] "deg" Vector__XXX
 SG_ SCCM_steeringAngleCounter : 8|4@1+ (1,0) [0|0] "" Vector__XXX
 SG_ SCCM_steeringAngleChecksum : 0|8@1+ (1,0) [0|0] "" Vector__XXX
 SG_ SCCM_steeringAngleSensorReservd1 : 46|2@1+ (1,0) [0|0] "" Vector__XXX
 SG_ SCCM_steeringAngleSensorReservd2 : 48|8@1+ (1,0) [0|0] "" Vector__XXX
 SG_ SCCM_steeringAngleSensorReservd3 : 56|8@1+ (1,0) [0|0] "" Vector__XXX
 SG_ SCCM_steeringAngleSensorStatus : 14|2@1+ (1,0) [0|0] "" Vector__XXX
 SG_ SCCM_steeringAngleSpeed : 32|14@1+ (0.5,-4096) [0|0] "deg/s" Vector__XXX
 SG_ SCCM_steeringAngleValidity : 30|2@1+ (1,0) [0|0] "" Vector__XXX
 SG_ SCCM_supplierID : 12|2@1+ (1,0) [0|0] "" Vector__XXX

BO_ 298 ID12ARightRearHVStatus: 7 VehicleBus
 SG_ RightRear_targetFluxMode : 51|2@1+ (1,0) [0|0] ""  Receiver
 SG_ RightRear_switchingFrequency : 40|11@1+ (0.01,0) [0|0] "kHz"  Receiver
 SG_ RightRear_dcCableCurrentEst : 24|16@1- (0.1,0) [0|0] "A"  Receiver
 SG_ RightRear_motorCurrent : 11|11@1+ (1,0) [0|0] "A"  Receiver
 SG_ RightRear_vBatQF : 10|1@1+ (1,0) [0|0] ""  Receiver
 SG_ RightRear_vBat : 0|10@1+ (0.5,0) [0|0] "V"  Receiver

BO_ 306 BMS_hvBusStatus: 8 VEH
 SG_ BMS_chgTimeToFull : 48|12@1+ (0.0166667,0) [0|68.25] "Hours" Vector__XXX
 SG_ BMS_currentUnfiltered : 32|16@1- (0.05,-500) [-2138.3|1138.3] "A" Vector__XXX
 SG_ BMS_packCurrent : 16|16@1- (0.1,0) [-3276.7|3276.7] "A" Vector__XXX
 SG_ BMS_packVoltage : 0|16@1+ (0.01,0) [0|0] "V" Vector__XXX

BO_ 307 UI_presentPhoneKeysOSInfo: 1 VEH
 SG_ UI_presentPhoneKey1RunsiOS : 0|1@1+ (1,0) [0|0] "" Vector__XXX
 SG_ UI_presentPhoneKey2RunsiOS : 1|1@1+ (1,0) [0|0] "" Vector__XXX
 SG_ UI_presentPhoneKey3RunsiOS : 2|1@1+ (1,0) [0|0] "" Vector__XXX

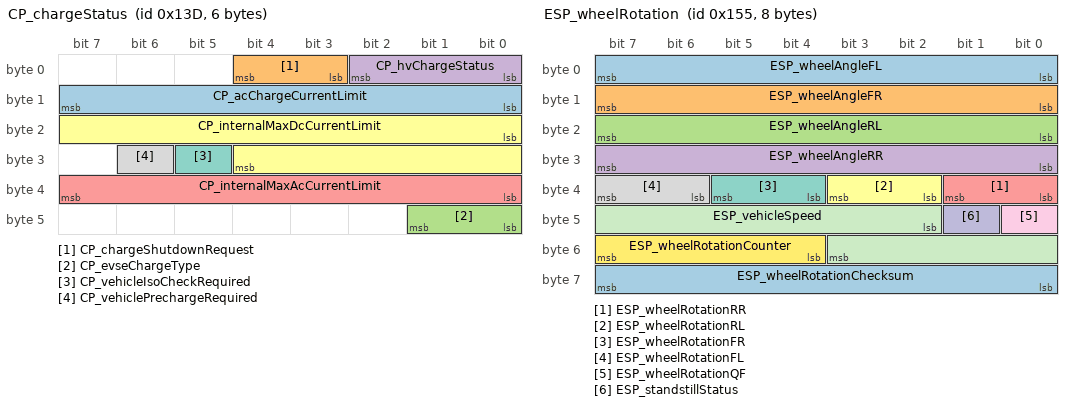
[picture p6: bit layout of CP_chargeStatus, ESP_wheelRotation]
BO_ 317 CP_chargeStatus: 6 VEH
 SG_ CP_acChargeCurrentLimit : 8|8@1+ (0.5,0) [0|127.5] "A"  Receiver
 SG_ CP_chargeShutdownRequest : 3|2@1+ (1,0) [0|2] ""  Receiver
 SG_ CP_evseChargeType : 40|2@1+ (1,0) [0|2] ""  Receiver
 SG_ CP_hvChargeStatus : 0|3@1+ (1,0) [0|6] ""  Receiver
 SG_ CP_internalMaxAcCurrentLimit : 32|8@1+ (0.5,0) [0|127.5] "A"  Receiver
 SG_ CP_internalMaxDcCurrentLimit : 16|13@1+ (0.146502,0) [0|1200] "A"  Receiver
 SG_ CP_vehicleIsoCheckRequired : 29|1@1+ (1,0) [0|1] ""  Receiver
 SG_ CP_vehiclePrechargeRequired : 30|1@1+ (1,0) [0|1] ""  Receiver

BO_ 322 VCLEFT_liftgateStatus: 8 VEH
 SG_ VCLEFT_liftgateStatusIndex M : 0|2@1+ (1,0) [0|2] "" Vector__XXX
 SG_ VCLEFT_liftgateLatchRequest m0 : 61|3@1+ (1,0) [0|4] "" Vector__XXX
 SG_ VCLEFT_liftgateMvmntNotAllowedCo m0 : 14|3@1+ (1,0) [0|5] "" Vector__XXX
 SG_ VCLEFT_liftgatePhysicalChimeRequ m0 : 21|3@1+ (1,0) [0|4] "" Vector__XXX
 SG_ VCLEFT_liftgatePosition m1 : 21|7@1- (1,46) [-5|95] "deg" Vector__XXX
 SG_ VCLEFT_liftgatePositionCalibrate m0 : 17|1@1+ (1,0) [0|1] "" Vector__XXX
 SG_ VCLEFT_liftgateRequestSource m0 : 7|3@1+ (1,0) [0|7] "" Vector__XXX
 SG_ VCLEFT_liftgateSpeed m1 : 28|10@1- (0.1,0) [-30|30] "deg/s" Vector__XXX
 SG_ VCLEFT_liftgateState m0 : 3|4@1+ (1,0) [0|12] "" Vector__XXX
 SG_ VCLEFT_liftgateStoppingCondition m0 : 10|4@1+ (1,0) [0|11] "" Vector__XXX
 SG_ VCLEFT_liftgateStrutCurrent m1 : 11|10@1- (0.1,0) [-30|30] "A" Vector__XXX
 SG_ VCLEFT_liftgateStrutDutyCycle m1 : 3|8@1- (1,0) [-100|100] "%" Vector__XXX
 SG_ VCLEFT_liftgateUIChimeRequest m0 : 18|3@1+ (1,0) [0|4] "" Vector__XXX

BO_ 325 ESP_status: 8 CH
 SG_ ESP_absBrakeEvent2 : 22|2@1+ (1,0) [0|0] "" Vector__XXX
 SG_ ESP_absFaultLamp : 17|1@1+ (1,0) [0|0] "" Vector__XXX
 SG_ ESP_brakeApply : 31|1@1+ (1,0) [0|0] "" Vector__XXX
 SG_ ESP_brakeDiscWipingActive : 28|1@1+ (1,0) [0|0] "" Vector__XXX
 SG_ ESP_brakeLamp : 21|1@1+ (1,0) [0|0] "" Vector__XXX
 SG_ ESP_brakeTorqueTarget : 51|13@1+ (2,0) [0|0] "Nm" Vector__XXX
 SG_ ESP_btcTargetState : 38|2@1+ (1,0) [0|0] "" Vector__XXX
 SG_ ESP_cdpStatus : 34|2@1+ (1,0) [0|0] "" Vector__XXX
 SG_ ESP_driverBrakeApply : 29|2@1+ (1,0) [0|0] "" Vector__XXX
 SG_ ESP_ebdFaultLamp : 16|1@1+ (1,0) [0|0] "" Vector__XXX
 SG_ ESP_ebrStandstillSkid : 48|1@1+ (1,0) [0|0] "" Vector__XXX
 SG_ ESP_ebrStatus : 49|2@1+ (1,0) [0|0] "" Vector__XXX
 SG_ ESP_espFaultLamp : 18|1@1+ (1,0) [0|0] "" Vector__XXX
 SG_ ESP_espLampFlash : 20|1@1+ (1,0) [0|0] "" Vector__XXX
 SG_ ESP_espModeActive : 12|2@1+ (1,0) [0|0] "" Vector__XXX
 SG_ ESP_hydraulicBoostEnabled : 19|1@1+ (1,0) [0|0] "" Vector__XXX
 SG_ ESP_lateralAccelQF : 25|1@1+ (1,0) [0|0] "" Vector__XXX
 SG_ ESP_longitudinalAccelQF : 24|1@1+ (1,0) [0|0] "" Vector__XXX
 SG_ ESP_ptcTargetState : 36|2@1+ (1,0) [0|0] "" Vector__XXX
 SG_ ESP_stabilityControlSts2 : 14|2@1+ (1,0) [0|0] "" Vector__XXX
 SG_ ESP_statusChecksum : 0|8@1+ (1,0) [0|0] "" Vector__XXX
 SG_ ESP_statusCounter : 8|4@1+ (1,0) [0|0] "" Vector__XXX
 SG_ ESP_steeringAngleQF : 27|1@1+ (1,0) [0|0] "" Vector__XXX
 SG_ ESP_yawRateQF : 26|1@1+ (1,0) [0|0] "" Vector__XXX

BO_ 340 ID154RearTorqueOld: 8 VehicleBus
 SG_ RAWTorqueRear154 : 40|12@1- (0.25,0) [-512|511.75] "NM"   X

BO_ 341 ESP_wheelRotation: 8 CH
 SG_ ESP_wheelAngleFL : 0|8@1+ (1.40625,0) [0|358.594] "deg" Vector__XXX
 SG_ ESP_wheelAngleFR : 8|8@1+ (1.40625,0) [0|358.594] "deg" Vector__XXX
 SG_ ESP_wheelAngleRL : 16|8@1+ (1.40625,0) [0|358.594] "deg" Vector__XXX
 SG_ ESP_wheelAngleRR : 24|8@1+ (1.40625,0) [0|358.594] "deg" Vector__XXX
 SG_ ESP_wheelRotationRR : 32|2@1+ (1,0) [0|3] ""  Receiver
 SG_ ESP_wheelRotationRL : 34|2@1+ (1,0) [0|3] ""  Receiver
 SG_ ESP_wheelRotationFR : 36|2@1+ (1,0) [0|3] ""  Receiver
 SG_ ESP_wheelRotationFL : 38|2@1+ (1,0) [0|3] ""  Receiver
 SG_ ESP_wheelRotationQF : 40|1@1+ (1,0) [0|1] ""  Receiver
 SG_ ESP_standstillStatus : 41|1@1+ (1,0) [0|1] ""  Receiver
 SG_ ESP_vehicleSpeed : 42|10@1+ (0.5,0) [0|511] "kph"  Receiver
 SG_ ESP_wheelRotationCounter : 52|4@1+ (1,0) [0|15] ""  Receiver
 SG_ ESP_wheelRotationChecksum : 56|8@1+ (1,0) [0|255] ""  Receiver

BO_ 371 UI_presentPhoneKey3Info: 8 VEH
 SG_ UI_presentPhoneKey3SHA1 : 10|54@1+ (1024,0) [0|0] "" Vector__XXX

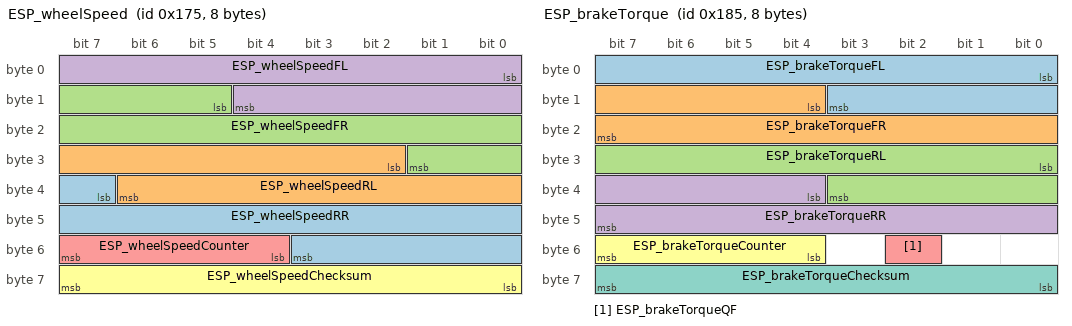
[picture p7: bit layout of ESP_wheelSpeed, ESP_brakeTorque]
BO_ 373 ESP_wheelSpeed: 8 CH
 SG_ ESP_wheelSpeedRR : 39|13@1+ (0.04,0) [0|327.64] "RPM" Vector__XXX
 SG_ ESP_wheelSpeedRL : 26|13@1+ (0.04,0) [0|327.64] "RPM" Vector__XXX
 SG_ ESP_wheelSpeedFR : 13|13@1+ (0.04,0) [0|327.64] "RPM" Vector__XXX
 SG_ ESP_wheelSpeedFL : 0|13@1+ (0.04,0) [0|327.64] "RPM" Vector__XXX
 SG_ ESP_wheelSpeedCounter : 52|4@1+ (1,0) [0|15] ""  Receiver
 SG_ ESP_wheelSpeedChecksum : 56|8@1+ (1,0) [0|255] ""  Receiver

BO_ 389 ESP_brakeTorque: 8 CH
 SG_ ESP_brakeTorqueFL : 0|12@1+ (2,0) [0|8190] "Nm"  Receiver
 SG_ ESP_brakeTorqueFR : 12|12@1+ (2,0) [0|8190] "Nm"  Receiver
 SG_ ESP_brakeTorqueRL : 24|12@1+ (2,0) [0|8190] "Nm"  Receiver
 SG_ ESP_brakeTorqueRR : 36|12@1+ (2,0) [0|8190] "Nm"  Receiver
 SG_ ESP_brakeTorqueQF : 50|1@1+ (1,0) [0|1] ""  Receiver
 SG_ ESP_brakeTorqueCounter : 52|4@1+ (1,0) [0|15] ""  Receiver
 SG_ ESP_brakeTorqueChecksum : 56|8@1+ (1,0) [0|255] ""  Receiver

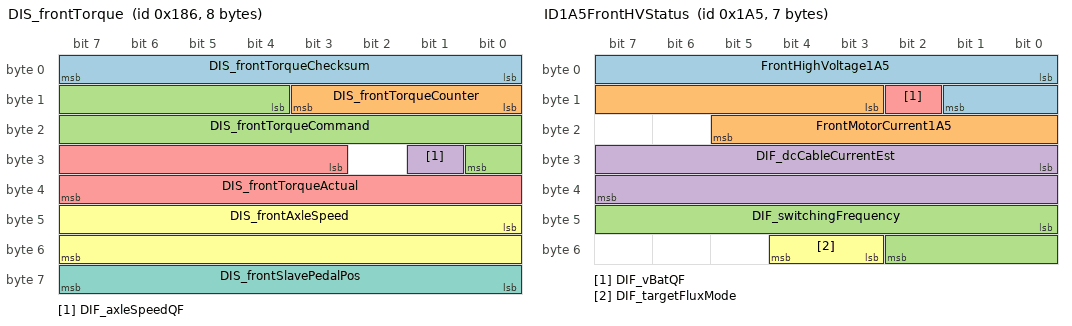
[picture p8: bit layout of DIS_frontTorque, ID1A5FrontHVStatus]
BO_ 390 DIS_frontTorque: 8 VEH
 SG_ DIS_frontTorqueChecksum : 0|8@1+ (1,0) [0|0] "" Vector__XXX
 SG_ DIS_frontTorqueCounter : 8|4@1+ (1,0) [0|0] "" Vector__XXX
 SG_ DIS_frontTorqueCommand : 12|13@1- (2,0) [0|0] "Nm" Vector__XXX
 SG_ DIF_axleSpeedQF : 25|1@1+ (1,0) [0|1] ""  Receiver
 SG_ DIS_frontTorqueActual : 27|13@1- (2,0) [0|0] "Nm" Vector__XXX
 SG_ DIS_frontAxleSpeed : 40|16@1- (0.1,0) [0|0] "RPM" Vector__XXX
 SG_ DIS_frontSlavePedalPos : 56|8@1+ (0.4,0) [0|100] "%" Vector__XXX

BO_ 392 DIS_capability2: 2 VEH
 SG_ DIS_heatPowerMax : 8|8@1+ (0.08,0) [0|0] "kW" Vector__XXX
 SG_ DIS_heatPowerOptimal : 0|8@1+ (0.08,0) [0|0] "kW" Vector__XXX

BO_ 421 ID1A5FrontHVStatus: 7 VehicleBus
 SG_ FrontHighVoltage1A5 : 0|10@1+ (0.5,0) [0|500] "V"  Receiver
 SG_ FrontMotorCurrent1A5 : 11|11@1+ (1,0) [0|2047] "A"  Receiver
 SG_ DIF_switchingFrequency : 40|11@1+ (0.01,0) [0|20] "kHz"  Receiver
 SG_ DIF_dcCableCurrentEst : 24|16@1- (0.1,0) [-3276.8|3276.7] "A"  Receiver
 SG_ DIF_vBatQF : 10|1@1+ (1,0) [0|0] ""  Receiver
 SG_ DIF_targetFluxMode : 51|2@1+ (1,0) [0|0] ""  Receiver

BO_ 435 UI_presentPhoneKey2Info: 8 VEH
 SG_ UI_presentPhoneKey2SHA1 : 10|54@1+ (1024,0) [0|0] "" Vector__XXX

BO_ 469 ID1D5FrontTorque: 8 VehicleBus
 SG_ FrontTorqueRequest1D5 : 8|13@1- (0.222,0) [-909.312|909.09] "NM"  Receiver
 SG_ FrontTorque1D5 : 21|13@1- (0.222,0) [-909.312|909.09] "NM"  Receiver

BO_ 470 DI_limits: 5 VEH
 SG_ DI_limitBaseSpeed : 15|1@1+ (1,0) [0|1] ""  Receiver
 SG_ DI_limitClutch : 28|1@1+ (1,0) [0|1] ""  Receiver
 SG_ DI_limitDcCapTemp : 17|1@1+ (1,0) [0|1] ""  Receiver
 SG_ DI_limitDeltaFluidTemp : 5|1@1+ (1,0) [0|1] ""  Receiver
 SG_ DI_limitDiff : 22|1@1+ (1,0) [0|1] ""  Receiver
 SG_ DI_limitDischargePower : 6|1@1+ (1,0) [0|1] ""  Receiver
 SG_ DI_limitDriveTorque : 10|1@1+ (1,0) [0|1] ""  Receiver
 SG_ DI_limitGracefulPowerOff : 23|1@1+ (1,0) [0|1] ""  Receiver
 SG_ DI_limitIBat : 16|1@1+ (1,0) [0|1] ""  Receiver
 SG_ DI_limitIGBTJunctTemp : 24|1@1+ (1,0) [0|1] ""  Receiver
 SG_ DI_limitInverterTemp : 1|1@1+ (1,0) [0|1] ""  Receiver
 SG_ DI_limitLimpMode : 4|1@1+ (1,0) [0|1] ""  Receiver
 SG_ DI_limitMotorCurrent : 8|1@1+ (1,0) [0|1] ""  Receiver
 SG_ DI_limitMotorSpeed : 20|1@1+ (1,0) [0|1] ""  Receiver
 SG_ DI_limitMotorVoltage : 9|1@1+ (1,0) [0|1] ""  Receiver
 SG_ DI_limitObstacleDetection : 29|1@1+ (1,0) [0|1] ""  Receiver
 SG_ DI_limitOilPumpFluidTemp : 26|1@1+ (1,0) [0|1] ""  Receiver
 SG_ DI_limitPCBTemp : 0|1@1+ (1,0) [0|1] ""  Receiver
 SG_ DI_limitPoleTemp : 3|1@1+ (1,0) [0|1] ""  Receiver
 SG_ DI_limitRegenPower : 7|1@1+ (1,0) [0|1] ""  Receiver
 SG_ DI_limitRegenTorque : 11|1@1+ (1,0) [0|1] ""  Receiver
 SG_ DI_limitRotorTemp : 36|1@1+ (1,0) [0|1] ""  Receiver
 SG_ DI_limitShift : 14|1@1+ (1,0) [0|1] ""  Receiver
 SG_ DI_limitShockTorque : 25|1@1+ (1,0) [0|1] ""  Receiver
 SG_ DI_limitStatorFrequency : 27|1@1+ (1,0) [0|1] ""  Receiver
 SG_ DI_limitStatorTemp : 2|1@1+ (1,0) [0|1] ""  Receiver
 SG_ DI_limitTCDrive : 12|1@1+ (1,0) [0|1] ""  Receiver
 SG_ DI_limitTCRegen : 13|1@1+ (1,0) [0|1] ""  Receiver
 SG_ DI_limitVBatHigh : 19|1@1+ (1,0) [0|1] ""  Receiver
 SG_ DI_limitVBatLow : 18|1@1+ (1,0) [0|1] ""  Receiver
 SG_ DI_limitVehicleSpeed : 21|1@1+ (1,0) [0|1] ""  Receiver
 SG_ DI_limitdcLinkCapTemp : 33|1@1+ (1,0) [0|1] ""  Receiver
 SG_ DI_limithvDcCableTemp : 37|1@1+ (1,0) [0|1] ""  Receiver
 SG_ DI_limitnegDcBusbarTemp : 34|1@1+ (1,0) [0|1] ""  Receiver
 SG_ DI_limitphaseOutBusBarWeldTemp : 31|1@1+ (1,0) [0|1] ""  Receiver
 SG_ DI_limitphaseOutBusbarTemp : 30|1@1+ (1,0) [0|1] ""  Receiver
 SG_ DI_limitphaseOutLugTemp : 32|1@1+ (1,0) [0|1] ""  Receiver
 SG_ DI_limitposDcBusbarTemp : 35|1@1+ (1,0) [0|1] ""  Receiver

BO_ 472 DIS_torque: 8 VEH
 SG_ DIS_torqueFlags : 0|8@1+ (1,0) [0|0] "" Vector__XXX
 SG_ DIS_torqueCommand : 8|15@1- (0.1,0) [0|0] "Nm" Vector__XXX
 SG_ DIS_torqueActual : 24|13@1- (2,0) [0|0] "Nm" Vector__XXX
 SG_ DIS_axleSpeed : 40|16@1- (0.1,0) [0|0] "RPM" Vector__XXX
 SG_ DIS_torqueChecksum : 56|8@1+ (1,0) [0|0] "" Vector__XXX
 SG_ DIS_torqueCounter : 53|3@1+ (1,0) [0|0] "" Vector__XXX

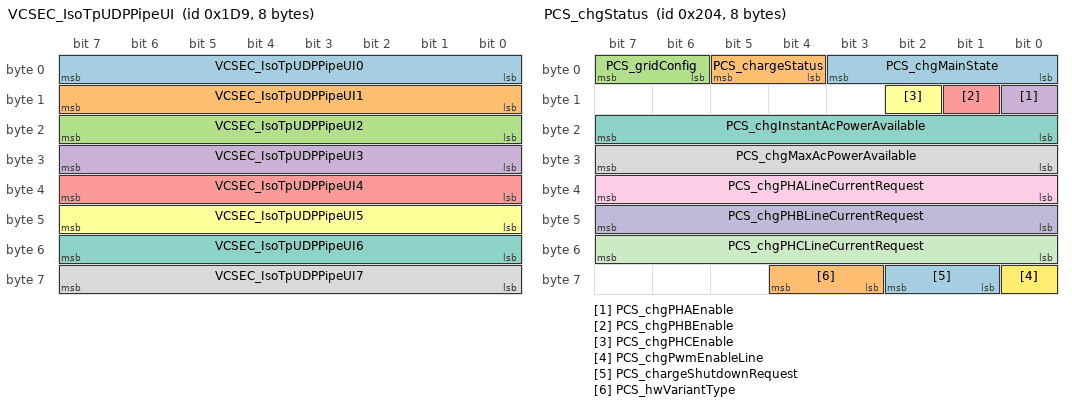
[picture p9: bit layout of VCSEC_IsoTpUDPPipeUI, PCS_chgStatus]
BO_ 473 VCSEC_IsoTpUDPPipeUI: 8 VEH
 SG_ VCSEC_IsoTpUDPPipeUI0 : 0|8@1+ (1,0) [0|0] "" Vector__XXX
 SG_ VCSEC_IsoTpUDPPipeUI1 : 8|8@1+ (1,0) [0|0] "" Vector__XXX
 SG_ VCSEC_IsoTpUDPPipeUI2 : 16|8@1+ (1,0) [0|0] "" Vector__XXX
 SG_ VCSEC_IsoTpUDPPipeUI3 : 24|8@1+ (1,0) [0|0] "" Vector__XXX
 SG_ VCSEC_IsoTpUDPPipeUI4 : 32|8@1+ (1,0) [0|0] "" Vector__XXX
 SG_ VCSEC_IsoTpUDPPipeUI5 : 40|8@1+ (1,0) [0|0] "" Vector__XXX
 SG_ VCSEC_IsoTpUDPPipeUI6 : 48|8@1+ (1,0) [0|0] "" Vector__XXX
 SG_ VCSEC_IsoTpUDPPipeUI7 : 56|8@1+ (1,0) [0|0] "" Vector__XXX

BO_ 499 UI_presentPhoneKey1Info: 8 VEH
 SG_ UI_presentPhoneKey1SHA1 : 10|54@1+ (1024,0) [0|0] "" Vector__XXX

BO_ 505 VCSEC_requests: 1 VEH
 SG_ VCSEC_chargePortRequest : 0|2@1+ (1,0) [0|0] "" Vector__XXX
 SG_ VCSEC_driveAttemptedWithoutAuth : 2|1@1+ (1,0) [0|0] "" Vector__XXX

BO_ 513 VCFRONT_logging10Hz2: 8 VEH
 SG_ VCFRONT_logging10Hz2 M : 0|3@1+ (1,0) [0|7] "" Vector__XXX
 SG_ VCFRONT_activeLouverOpenPos m1 : 16|7@1+ (1,0) [0|100] "%" Vector__XXX
 SG_ VCFRONT_activeLouverOpenPosTarg m1 : 8|7@1+ (1,0) [0|100] "%" Vector__XXX
 SG_ VCFRONT_cclExvFlow m3 : 44|10@1+ (0.1,0) [0|100] "%" Vector__XXX
 SG_ VCFRONT_cclExvFlowTarget m5 : 44|10@1+ (0.1,0) [0|100] "%" Vector__XXX
 SG_ VCFRONT_cclExvState m6 : 20|3@1+ (1,0) [0|7] "" Vector__XXX
 SG_ VCFRONT_ccrExvFlow m3 : 54|10@1+ (0.1,0) [0|100] "%" Vector__XXX
 SG_ VCFRONT_ccrExvFlowTarget m5 : 54|10@1+ (0.1,0) [0|100] "%" Vector__XXX
 SG_ VCFRONT_ccrExvState m6 : 24|4@1+ (1,0) [0|7] "" Vector__XXX
 SG_ VCFRONT_chillerExvFlow m3 : 3|10@1+ (0.1,0) [0|100] "%" Vector__XXX
 SG_ VCFRONT_chillerExvFlowTarget m5 : 3|10@1+ (0.1,0) [0|100] "%" Vector__XXX
 SG_ VCFRONT_chillerExvState m6 : 3|4@1+ (1,0) [0|7] "" Vector__XXX
 SG_ VCFRONT_compDemandChiller m2 : 39|7@1+ (1,0) [0|100] "%" Vector__XXX
 SG_ VCFRONT_compDemandEvap m2 : 26|7@1+ (1,0) [0|100] "%" Vector__XXX
 SG_ VCFRONT_compressorState m2 : 24|2@1+ (1,0) [0|3] "" Vector__XXX
 SG_ VCFRONT_coolantValveMode m2 : 61|2@1+ (1,0) [0|3] "" Vector__XXX
 SG_ VCFRONT_evapExvFlow m3 : 13|10@1+ (0.1,0) [0|100] "%" Vector__XXX
 SG_ VCFRONT_evapExvFlowTarget m5 : 13|10@1+ (0.1,0) [0|100] "%" Vector__XXX
 SG_ VCFRONT_evapExvState m6 : 8|4@1+ (1,0) [0|7] "" Vector__XXX
 SG_ VCFRONT_exvFlowTarget m0 : 54|10@1+ (0.1,0) [0|100] "%" Vector__XXX
 SG_ VCFRONT_exvState m2 : 33|4@1+ (1,0) [0|7] "" Vector__XXX
 SG_ VCFRONT_fanDemand m2 : 16|7@1+ (1,0) [0|100] "%" Vector__XXX
 SG_ VCFRONT_hpBatteryLoadType m4 : 16|2@1+ (1,0) [0|2] "" Vector__XXX
 SG_ VCFRONT_hpBlendType m4 : 11|2@1+ (1,0) [0|2] "" Vector__XXX
 SG_ VCFRONT_hpCabinLoadType m4 : 14|2@1+ (1,0) [0|3] "" Vector__XXX
 SG_ VCFRONT_hpDominantLoad m4 : 8|3@1+ (1,0) [0|6] "" Vector__XXX
 SG_ VCFRONT_hpHighSideHX m4 : 3|2@1+ (1,0) [0|3] "" Vector__XXX
 SG_ VCFRONT_hpLowSideHX m4 : 5|2@1+ (1,0) [0|3] "" Vector__XXX
 SG_ VCFRONT_hpQuietModeEnabled m4 : 13|1@1+ (1,0) [0|1] "" Vector__XXX
 SG_ VCFRONT_hpReqCoolantMode m4 : 18|3@1+ (1,0) [0|4] "" Vector__XXX
 SG_ VCFRONT_lccExvFlow m3 : 34|10@1+ (0.1,0) [0|100] "%" Vector__XXX
 SG_ VCFRONT_lccExvFlowTarget m5 : 34|10@1+ (0.1,0) [0|100] "%" Vector__XXX
 SG_ VCFRONT_lccExvState m6 : 16|4@1+ (1,0) [0|8] "" Vector__XXX
 SG_ VCFRONT_pressureRefrigDischargeV m2 : 53|8@1+ (0.125,0) [0|31.75] "bar" Vector__XXX
 SG_ VCFRONT_pressureRefrigLiquid m1 : 40|8@1+ (0.125,0) [0|31.75] "bar" Vector__XXX
 SG_ VCFRONT_pressureRefrigSuctionVit m2 : 46|7@1+ (0.125,0) [0|11.5] "bar" Vector__XXX
 SG_ VCFRONT_pumpBatteryRPMActual m0 : 3|10@1+ (10,0) [0|10000] "rpm" Vector__XXX
 SG_ VCFRONT_pumpPowertrainRPMActual m0 : 13|10@1+ (10,0) [0|10000] "rpm" Vector__XXX
 SG_ VCFRONT_radiatorFanRPMActual m0 : 24|10@1+ (10,0) [0|10000] "rpm" Vector__XXX
 SG_ VCFRONT_recircExvFlow m3 : 24|10@1+ (0.1,0) [0|100] "%" Vector__XXX
 SG_ VCFRONT_recircExvFlowTarget m5 : 24|10@1+ (0.1,0) [0|100] "%" Vector__XXX
 SG_ VCFRONT_solenoidEvapState m2 : 37|2@1+ (1,0) [0|3] "" Vector__XXX
 SG_ VCFRONT_tempRefrigDischarge m2 : 3|11@1+ (0.125,-40) [-40|150] "C" Vector__XXX
 SG_ VCFRONT_tempRefrigLiquid m1 : 24|11@1+ (0.125,-40) [-40|150] "C" Vector__XXX
 SG_ VCFRONT_tempSuperheatActFiltered m1 : 48|8@1- (0.25,26.5) [-5|58] "C" Vector__XXX
 SG_ VCFRONT_tempSuperheatActual m0 : 34|10@1+ (0.1,-20) [-20|80] "C" Vector__XXX
 SG_ VCFRONT_tempSuperheatTarget m0 : 44|10@1+ (0.1,0) [0|60] "C" Vector__XXX

BO_ 516 PCS_chgStatus: 8 VEH
 SG_ PCS_chgMainState : 0|4@1+ (1,0) [0|0] "" Vector__XXX
 SG_ PCS_chargeStatus : 4|2@1+ (1,0) [0|0] "" Vector__XXX
 SG_ PCS_gridConfig : 6|2@1+ (1,0) [0|0] "" Vector__XXX
 SG_ PCS_chgPHAEnable : 8|1@1+ (1,0) [0|0] "" Vector__XXX
 SG_ PCS_chgPHBEnable : 9|1@1+ (1,0) [0|0] "" Vector__XXX
 SG_ PCS_chgPHCEnable : 10|1@1+ (1,0) [0|0] "" Vector__XXX
 SG_ PCS_chgInstantAcPowerAvailable : 16|8@1+ (0.1,0) [0|0] "kW" Vector__XXX
 SG_ PCS_chgMaxAcPowerAvailable : 24|8@1+ (0.1,0) [0|0] "kW" Vector__XXX
 SG_ PCS_chgPHALineCurrentRequest : 32|8@1+ (0.1,0) [0|0] "A" Vector__XXX
 SG_ PCS_chgPHBLineCurrentRequest : 40|8@1+ (0.1,0) [0|0] "A" Vector__XXX
 SG_ PCS_chgPHCLineCurrentRequest : 48|8@1+ (0.1,0) [0|0] "A" Vector__XXX
 SG_ PCS_chgPwmEnableLine : 56|1@1+ (1,0) [0|0] "" Vector__XXX
 SG_ PCS_chargeShutdownRequest : 57|2@1+ (1,0) [0|2] ""   X
 SG_ PCS_hwVariantType : 59|2@1+ (1,0) [0|3] ""   X

BO_ 522 HVP_contactorState: 6 VEH
 SG_ HVP_dcLinkAllowedToEnergize : 38|1@1+ (1,0) [0|0] "" Vector__XXX
 SG_ HVP_fcContNegativeState : 12|3@1+ (1,0) [0|0] "" Vector__XXX
 SG_ HVP_fcContPositiveState : 16|3@1+ (1,0) [0|0] "" Vector__XXX
 SG_ HVP_fcContactorSetState : 19|4@1+ (1,0) [0|0] "" Vector__XXX
 SG_ HVP_fcCtrsClosingAllowed : 29|1@1+ (1,0) [0|0] "" Vector__XXX
 SG_ HVP_fcCtrsOpenNowRequested : 27|1@1+ (1,0) [0|0] "" Vector__XXX
 SG_ HVP_fcCtrsOpenRequested : 28|1@1+ (1,0) [0|0] "" Vector__XXX
 SG_ HVP_fcCtrsRequestStatus : 24|2@1+ (1,0) [0|0] "" Vector__XXX
 SG_ HVP_fcCtrsResetRequestRequired : 26|1@1+ (1,0) [0|0] "" Vector__XXX
 SG_ HVP_fcLinkAllowedToEnergizeAc : 30|1@1+ (1,0) [0|0] "" Vector__XXX
 SG_ HVP_fcLinkAllowedToEnergizeDc : 31|1@1+ (1,0) [0|0] "" Vector__XXX
 SG_ HVP_hvilStatus : 40|4@1+ (1,0) [0|0] "" Vector__XXX
 SG_ HVP_packContNegativeState : 0|3@1+ (1,0) [0|0] "" Vector__XXX
 SG_ HVP_packContPositiveState : 3|3@1+ (1,0) [0|0] "" Vector__XXX
 SG_ HVP_packContactorSetState : 8|4@1+ (1,0) [0|0] "" Vector__XXX
 SG_ HVP_packCtrsClosingAllowed : 37|1@1+ (1,0) [0|0] "" Vector__XXX
 SG_ HVP_packCtrsOpenNowRequested : 35|1@1+ (1,0) [0|0] "" Vector__XXX
 SG_ HVP_packCtrsOpenRequested : 36|1@1+ (1,0) [0|0] "" Vector__XXX
 SG_ HVP_packCtrsRequestStatus : 32|2@1+ (1,0) [0|0] "" Vector__XXX
 SG_ HVP_packCtrsResetRequestRequired : 34|1@1+ (1,0) [0|0] "" Vector__XXX
 SG_ HVP_pyroTestInProgress : 39|1@1+ (1,0) [0|0] "" Vector__XXX

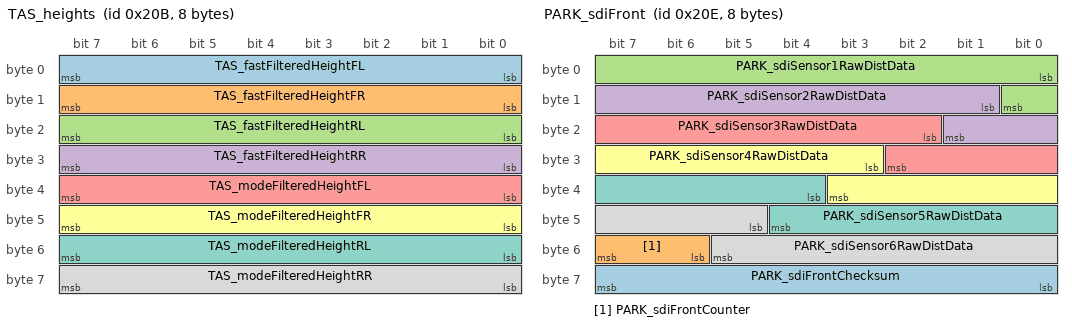
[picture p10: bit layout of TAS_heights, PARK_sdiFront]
BO_ 523 TAS_heights: 8 VEH
 SG_ TAS_fastFilteredHeightFL : 0|8@1+ (1,-128) [0|0] "mm" Vector__XXX
 SG_ TAS_fastFilteredHeightFR : 8|8@1+ (1,-128) [0|0] "mm" Vector__XXX
 SG_ TAS_fastFilteredHeightRL : 16|8@1+ (1,-128) [0|0] "mm" Vector__XXX
 SG_ TAS_fastFilteredHeightRR : 24|8@1+ (1,-128) [0|0] "mm" Vector__XXX
 SG_ TAS_modeFilteredHeightFL : 32|8@1+ (1,-128) [0|0] "mm" Vector__XXX
 SG_ TAS_modeFilteredHeightFR : 40|8@1+ (1,-128) [0|0] "mm" Vector__XXX
 SG_ TAS_modeFilteredHeightRL : 48|8@1+ (1,-128) [0|0] "mm" Vector__XXX
 SG_ TAS_modeFilteredHeightRR : 56|8@1+ (1,-128) [0|0] "mm" Vector__XXX

BO_ 524 VCRIGHT_hvacRequest: 7 VEH
 SG_ VCRIGHT_conditioningRequest : 12|1@1+ (1,0) [0|1] "" Vector__XXX
 SG_ VCRIGHT_evapPerformanceLow : 43|1@1+ (1,0) [0|1] "" Vector__XXX
 SG_ VCRIGHT_hvacBlowerSpeedRPMReq : 32|10@1+ (5,0) [0|5115] "RPM" Vector__XXX
 SG_ VCRIGHT_hvacEvapEnabled : 11|1@1+ (1,0) [0|1] "" Vector__XXX
 SG_ VCRIGHT_hvacHeatingEnabledLeft : 52|1@1+ (1,0) [0|1] "" Vector__XXX
 SG_ VCRIGHT_hvacHeatingEnabledRight : 53|1@1+ (1,0) [0|1] "" Vector__XXX
 SG_ VCRIGHT_hvacPerfTestRunning : 42|1@1+ (1,0) [0|1] "" Vector__XXX
 SG_ VCRIGHT_hvacPerfTestState : 54|2@1+ (1,0) [0|2] "" Vector__XXX
 SG_ VCRIGHT_hvacUnavailable : 56|1@1+ (1,0) [0|1] ""  Receiver
 SG_ VCRIGHT_tempAmbientRaw : 44|8@1+ (0.5,-40) [-40|80] "C" Vector__XXX
 SG_ VCRIGHT_tempEvaporator : 13|11@1+ (0.1,-40) [-40|105] "C" Vector__XXX
 SG_ VCRIGHT_tempEvaporatorTarget : 24|8@1+ (0.2,0) [0|50] "C" Vector__XXX
 SG_ VCRIGHT_wattsDemandEvap : 0|11@1+ (5,0) [0|10000] "W" Vector__XXX

BO_ 525 TAS_states: 8 VEH
 SG_ TAS_compressorRun : 30|1@1+ (1,0) [0|0] "" Vector__XXX
 SG_ TAS_currentLevel : 42|3@1+ (1,0) [0|0] "" Vector__XXX
 SG_ TAS_filterMode : 27|3@1+ (1,0) [0|0] "" Vector__XXX
 SG_ TAS_highAllowed : 36|1@1+ (1,0) [0|0] "" Vector__XXX
 SG_ TAS_jackMode : 38|1@1+ (1,0) [0|0] "" Vector__XXX
 SG_ TAS_leanDetected : 32|1@1+ (1,0) [0|0] "" Vector__XXX
 SG_ TAS_levelingState : 0|4@1+ (1,0) [0|0] "" Vector__XXX
 SG_ TAS_levelingType : 4|4@1+ (1,0) [0|0] "" Vector__XXX
 SG_ TAS_limpHomeMode : 48|3@1+ (1,0) [0|0] "" Vector__XXX
 SG_ TAS_lowAllowed : 34|1@1+ (1,0) [0|0] "" Vector__XXX
 SG_ TAS_pressureGallery : 8|8@1+ (0.1,0) [0|0] "bar" Vector__XXX
 SG_ TAS_pressureReservoir : 16|8@1+ (0.1,0) [0|0] "bar" Vector__XXX
 SG_ TAS_redWarningLamp : 40|1@1+ (1,0) [0|0] "" Vector__XXX
 SG_ TAS_runMode : 24|3@1+ (1,0) [0|0] "" Vector__XXX
 SG_ TAS_spinnerUI : 41|1@1+ (1,0) [0|0] "" Vector__XXX
 SG_ TAS_standardAllowed : 35|1@1+ (1,0) [0|0] "" Vector__XXX
 SG_ TAS_statesChecksum : 56|8@1+ (1,0) [0|0] "" Vector__XXX
 SG_ TAS_statesCounter : 52|4@1+ (1,0) [0|0] "" Vector__XXX
 SG_ TAS_targetLevel : 45|3@1+ (1,0) [0|0] "" Vector__XXX
 SG_ TAS_twistDetected : 31|1@1+ (1,0) [0|0] "" Vector__XXX
 SG_ TAS_veryHighAllowed : 37|1@1+ (1,0) [0|0] "" Vector__XXX
 SG_ TAS_veryLowAllowed : 33|1@1+ (1,0) [0|0] "" Vector__XXX
 SG_ TAS_yellowWarningLamp : 39|1@1+ (1,0) [0|0] "" Vector__XXX

BO_ 526 PARK_sdiFront: 8 CH
 SG_ PARK_sdiFrontChecksum : 56|8@1+ (1,0) [0|0] "" Vector__XXX
 SG_ PARK_sdiFrontCounter : 54|2@1+ (1,0) [0|0] "" Vector__XXX
 SG_ PARK_sdiSensor1RawDistData : 0|9@1+ (1,0) [0|0] "cm" Vector__XXX
 SG_ PARK_sdiSensor2RawDistData : 9|9@1+ (1,0) [0|0] "cm" Vector__XXX
 SG_ PARK_sdiSensor3RawDistData : 18|9@1+ (1,0) [0|0] "cm" Vector__XXX
 SG_ PARK_sdiSensor4RawDistData : 27|9@1+ (1,0) [0|0] "cm" Vector__XXX
 SG_ PARK_sdiSensor5RawDistData : 36|9@1+ (1,0) [0|0] "cm" Vector__XXX
 SG_ PARK_sdiSensor6RawDistData : 45|9@1+ (1,0) [0|0] "cm" Vector__XXX

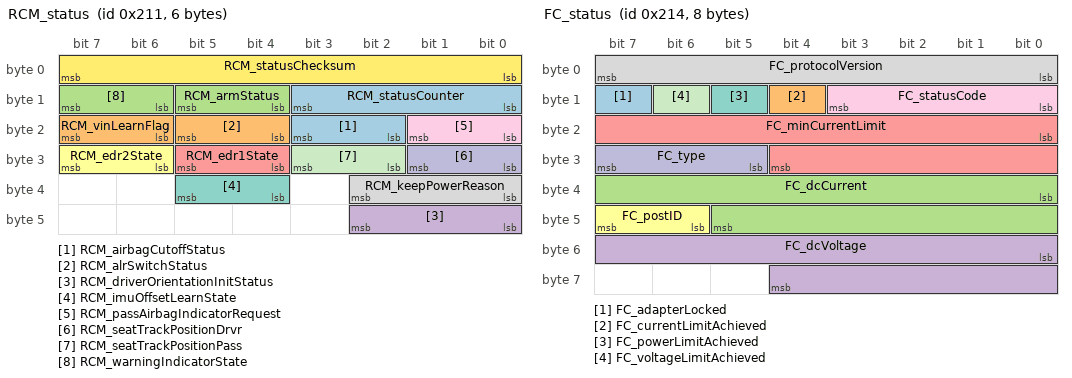
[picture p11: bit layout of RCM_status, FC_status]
BO_ 529 RCM_status: 6 VEH
 SG_ RCM_airbagCutoffStatus : 18|2@1+ (1,0) [0|0] "" Vector__XXX
 SG_ RCM_alrSwitchStatus : 20|2@1+ (1,0) [0|0] "" Vector__XXX
 SG_ RCM_armStatus : 12|2@1+ (1,0) [0|0] "" Vector__XXX
 SG_ RCM_driverOrientationInitStatus : 40|3@1+ (1,0) [0|0] "" Vector__XXX
 SG_ RCM_edr1State : 28|2@1+ (1,0) [0|0] "" Vector__XXX
 SG_ RCM_edr2State : 30|2@1+ (1,0) [0|0] "" Vector__XXX
 SG_ RCM_imuOffsetLearnState : 36|2@1+ (1,0) [0|0] "" Vector__XXX
 SG_ RCM_keepPowerReason : 32|3@1+ (1,0) [0|0] "" Vector__XXX
 SG_ RCM_passAirbagIndicatorRequest : 16|2@1+ (1,0) [0|0] "" Vector__XXX
 SG_ RCM_seatTrackPositionDrvr : 24|2@1+ (1,0) [0|0] "" Vector__XXX
 SG_ RCM_seatTrackPositionPass : 26|2@1+ (1,0) [0|0] "" Vector__XXX
 SG_ RCM_statusChecksum : 0|8@1+ (1,0) [0|0] "" Vector__XXX
 SG_ RCM_statusCounter : 8|4@1+ (1,0) [0|0] "" Vector__XXX
 SG_ RCM_vinLearnFlag : 22|2@1+ (1,0) [0|0] "" Vector__XXX
 SG_ RCM_warningIndicatorState : 14|2@1+ (1,0) [0|0] "" Vector__XXX

BO_ 530 BMS_status: 8 VEH
 SG_ BMS_activeHeatingWorthwhile : 5|1@1+ (1,0) [0|0] "" Vector__XXX
 SG_ BMS_chargeRequest : 29|1@1+ (1,0) [0|0] "" Vector__XXX
 SG_ BMS_chargeRetryCount : 49|4@1+ (1,0) [0|0] "" Vector__XXX
 SG_ BMS_chgPowerAvailable : 38|11@1+ (0.125,0) [0|0] "kW" Vector__XXX
 SG_ BMS_contactorState : 8|3@1+ (1,0) [0|0] "" Vector__XXX
 SG_ BMS_cpMiaOnHvs : 6|1@1+ (1,0) [0|0] "" Vector__XXX
 SG_ BMS_diLimpRequest : 35|1@1+ (1,0) [0|0] "" Vector__XXX
 SG_ BMS_ecuLogUploadRequest : 54|2@1+ (1,0) [0|0] "" Vector__XXX
 SG_ BMS_hvState : 16|3@1+ (1,0) [0|0] "" Vector__XXX
 SG_ BMS_hvacPowerRequest : 0|1@1+ (1,0) [0|0] "" Vector__XXX
 SG_ BMS_isolationResistance : 19|10@1+ (10,0) [0|0] "kOhm" Vector__XXX
 SG_ BMS_keepWarmRequest : 30|1@1+ (1,0) [0|0] "" Vector__XXX
 SG_ BMS_minPackTemperature : 56|8@1+ (0.5,-40) [0|0] "DegC" Vector__XXX
 SG_ BMS_notEnoughPowerForDrive : 1|1@1+ (1,0) [0|0] "" Vector__XXX
 SG_ BMS_notEnoughPowerForSupport : 2|1@1+ (1,0) [0|0] "" Vector__XXX
 SG_ BMS_okToShipByAir : 36|1@1+ (1,0) [0|0] "" Vector__XXX
 SG_ BMS_okToShipByLand : 37|1@1+ (1,0) [0|0] "" Vector__XXX
 SG_ BMS_pcsPwmEnabled : 53|1@1+ (1,0) [0|0] "" Vector__XXX
 SG_ BMS_preconditionAllowed : 3|1@1+ (1,0) [0|0] "" Vector__XXX
 SG_ BMS_state : 11|4@1+ (1,0) [0|0] "" Vector__XXX
 SG_ BMS_uiChargeStatus : 32|3@1+ (1,0) [0|0] "" Vector__XXX
 SG_ BMS_updateAllowed : 4|1@1+ (1,0) [0|0] "" Vector__XXX

BO_ 531 UI_cruiseControl: 3 VEH
 SG_ UI_cruiseControlChecksum : 16|8@1+ (1,0) [0|0] "" Vector__XXX
 SG_ UI_cruiseControlCounter : 11|4@1+ (1,0) [0|0] "" Vector__XXX
 SG_ UI_cruiseSpeedCommand : 8|3@1+ (1,0) [0|0] "" Vector__XXX
 SG_ UI_speedLimitTick : 0|8@1+ (1,0) [0|0] "speed" Vector__XXX

BO_ 532 FC_status: 8 VEH
 SG_ FC_adapterLocked : 15|1@1+ (1,0) [0|0] "" Vector__XXX
 SG_ FC_currentLimitAchieved : 12|1@1+ (1,0) [0|0] "" Vector__XXX
 SG_ FC_dcCurrent : 32|14@1- (0.0732422,0) [0|0] "A" Vector__XXX
 SG_ FC_dcVoltage : 48|13@1+ (0.0732422,0) [0|0] "V" Vector__XXX
 SG_ FC_minCurrentLimit : 16|13@1+ (0.1,0) [0|0] "A" Vector__XXX
 SG_ FC_postID : 46|2@1+ (2,0) [0|0] "" Vector__XXX
 SG_ FC_powerLimitAchieved : 13|1@1+ (1,0) [0|0] "" Vector__XXX
 SG_ FC_protocolVersion : 0|8@1+ (1,0) [0|0] "" Vector__XXX
 SG_ FC_statusCode : 8|4@1+ (1,0) [0|0] "" Vector__XXX
 SG_ FC_type : 29|3@1+ (1,0) [0|0] "" Vector__XXX
 SG_ FC_voltageLimitAchieved : 14|1@1+ (1,0) [0|0] "" Vector__XXX

BO_ 533 FC_status2: 1 VEH
 SG_ FC_externalIsolationResistance : 0|8@1+ (40,0) [0|0] "kOhm" Vector__XXX

BO_ 535 FC_status3: 8 VEH
 SG_ FC_status3DataSelect M : 0|7@1+ (1,0) [0|0] "" Vector__XXX
 SG_ FC_status3DummySig : 7|1@1+ (1,0) [0|0] "" Vector__XXX
 SG_ FC_class m0 : 8|8@1+ (1,0) [0|0] "" Vector__XXX
 SG_ FC_brand m0 : 16|4@1+ (1,0) [0|0] "" Vector__XXX
 SG_ FC_coolingType m0 : 20|4@1+ (1,0) [0|0] "" Vector__XXX
 SG_ FC_uiStopType m0 : 24|4@1+ (1,0) [0|0] "" Vector__XXX
 SG_ FC_generation m0 : 32|8@1+ (1,0) [0|255] ""  Receiver
 SG_ FC_billingEnergy m1 : 8|16@1+ (0.015259,0) [0|1000] "kWh"   X

BO_ 536 UI_driverAssistRoadSign: 8 VEH
 SG_ UI_roadSign M : 0|8@1+ (1,0) [0|0] "" Vector__XXX
 SG_ UI_roadSignChecksum : 56|8@1+ (1,0) [0|0] "" Vector__XXX
 SG_ UI_roadSignCounter : 52|4@1+ (1,0) [0|0] "" Vector__XXX
 SG_ UI_splineID : 48|4@1+ (1,0) [0|0] "" Vector__XXX
 SG_ UI_splineLocConfidence : 40|7@1+ (1,0) [0|0] "1" Vector__XXX
 SG_ UI_dummyData m0 : 8|1@1+ (1,0) [0|0] "" Vector__XXX
 SG_ UI_stopSignStopLineDist m1 : 8|10@1+ (0.25,-8) [0|0] "m" Vector__XXX
 SG_ UI_stopSignStopLineConf m1 : 18|7@1+ (1,0) [0|0] "1" Vector__XXX
 SG_ UI_trafficLightStopLineDist m2 : 8|10@1+ (0.25,-8) [0|0] "m" Vector__XXX
 SG_ UI_trafficLightStopLineConf m2 : 18|7@1+ (1,0) [0|0] "1" Vector__XXX
 SG_ UI_baseMapSpeedLimitMPS m3 : 8|8@1+ (0.25,0) [0|0] "m/s" Vector__XXX
 SG_ UI_bottomQrtlFleetSpeedMPS m3 : 16|8@1+ (0.25,0) [0|0] "m/s" Vector__XXX
 SG_ UI_topQrtlFleetSpeedMPS m3 : 24|8@1+ (0.25,0) [0|0] "m/s" Vector__XXX
 SG_ UI_meanFleetSplineSpeedMPS m4 : 8|8@1+ (0.25,0) [0|0] "m/s" Vector__XXX
 SG_ UI_medianFleetSpeedMPS m4 : 16|8@1+ (0.25,0) [0|0] "m/s" Vector__XXX
 SG_ UI_meanFleetSplineAccelMPS2 m4 : 24|8@1+ (0.05,-6.35) [0|0] "m/s^2" Vector__XXX
 SG_ UI_rampType m4 : 32|3@1+ (1,0) [0|0] "" Vector__XXX
 SG_ UI_currSplineIdFull m5 : 8|32@1+ (1,0) [0|0] "1" Vector__XXX

BO_ 537 VCSEC_TPMSData: 5 CH
 SG_ VCSEC_TPMSDataIndex M : 0|2@1+ (1,0) [0|3] ""  Receiver
 SG_ VCSEC_TPMSBatVoltage0 m0 : 24|8@1+ (0.01,1.5) [1.5|4.04] "V" Vector__XXX
 SG_ VCSEC_TPMSBatVoltage1 m1 : 24|8@1+ (0.01,1.5) [1.5|4.04] "V" Vector__XXX
 SG_ VCSEC_TPMSBatVoltage2 m2 : 24|8@1+ (0.01,1.5) [1.5|4.04] "V" Vector__XXX
 SG_ VCSEC_TPMSBatVoltage3 m3 : 24|8@1+ (0.01,1.5) [1.5|4.04] "V" Vector__XXX
 SG_ VCSEC_TPMSLocation0 m0 : 32|3@1+ (1,0) [0|4] "" Vector__XXX
 SG_ VCSEC_TPMSLocation1 m1 : 32|3@1+ (1,0) [0|4] "" Vector__XXX
 SG_ VCSEC_TPMSLocation2 m2 : 32|3@1+ (1,0) [0|4] "" Vector__XXX
 SG_ VCSEC_TPMSLocation3 m3 : 32|3@1+ (1,0) [0|4] "" Vector__XXX
 SG_ VCSEC_TPMSPressure0 m0 : 8|8@1+ (0.025,0) [0|6.35] "bar" Vector__XXX
 SG_ VCSEC_TPMSPressure1 m1 : 8|8@1+ (0.025,0) [0|6.35] "bar" Vector__XXX
 SG_ VCSEC_TPMSPressure2 m2 : 8|8@1+ (0.025,0) [0|6.35] "bar" Vector__XXX
 SG_ VCSEC_TPMSPressure3 m3 : 8|8@1+ (0.025,0) [0|6.35] "bar" Vector__XXX
 SG_ VCSEC_TPMSTemperature0 m0 : 16|8@1+ (1,-40) [-40|214] "C" Vector__XXX
 SG_ VCSEC_TPMSTemperature1 m1 : 16|8@1+ (1,-40) [-40|214] "C" Vector__XXX
 SG_ VCSEC_TPMSTemperature2 m2 : 16|8@1+ (1,-40) [-40|214] "C" Vector__XXX
 SG_ VCSEC_TPMSTemperature3 m3 : 16|8@1+ (1,-40) [-40|214] "C" Vector__XXX

BO_ 541 CP_evseStatus: 8 VEH
 SG_ CP_acChargeRetriesExceeded : 41|1@1+ (1,0) [0|0] "" Vector__XXX
 SG_ CP_acChargeState : 60|2@1+ (1,0) [0|0] "" Vector__XXX
 SG_ CP_acNumRetries : 42|2@1+ (1,0) [0|0] "" Vector__XXX
 SG_ CP_cableCurrentLimit : 24|7@1+ (1,0) [0|0] "A" Vector__XXX
 SG_ CP_cableType : 16|3@1+ (1,0) [0|0] "" Vector__XXX
 SG_ CP_digitalCommsAttempts : 32|2@1+ (1,0) [0|0] "" Vector__XXX
 SG_ CP_digitalCommsEstablished : 37|1@1+ (1,0) [0|0] "" Vector__XXX
 SG_ CP_evseAccept : 0|1@1+ (1,0) [0|0] "" Vector__XXX
 SG_ CP_evseChargeType : 38|2@1+ (1,0) [0|0] "" Vector__XXX
 SG_ CP_evseRequest : 1|1@1+ (1,0) [0|0] "" Vector__XXX
 SG_ CP_gbState : 48|5@1+ (1,0) [0|0] "" Vector__XXX
 SG_ CP_gbdcChargeAttempts : 58|2@1+ (1,0) [0|0] "" Vector__XXX
 SG_ CP_gbdcFailureReason : 56|2@1+ (1,0) [0|0] "" Vector__XXX
 SG_ CP_gbdcStopChargeReason : 53|3@1+ (1,0) [0|0] "" Vector__XXX
 SG_ CP_lineVoltageRequested : 2|1@1+ (1,0) [0|0] "" Vector__XXX
 SG_ CP_pilot : 5|3@1+ (1,0) [0|0] "" Vector__XXX
 SG_ CP_pilotCurrent : 8|8@1+ (0.5,0) [0|0] "A" Vector__XXX
 SG_ CP_proximity : 3|2@1+ (1,0) [0|0] "" Vector__XXX
 SG_ CP_stopChargeRequest : 40|1@1+ (1,0) [0|0] "" Vector__XXX
 SG_ CP_teslaSwcanState : 34|3@1+ (1,0) [0|0] "" Vector__XXX
 SG_ CP_vehiclePrechargeRequired : 44|1@1+ (1,0) [0|0] "" Vector__XXX

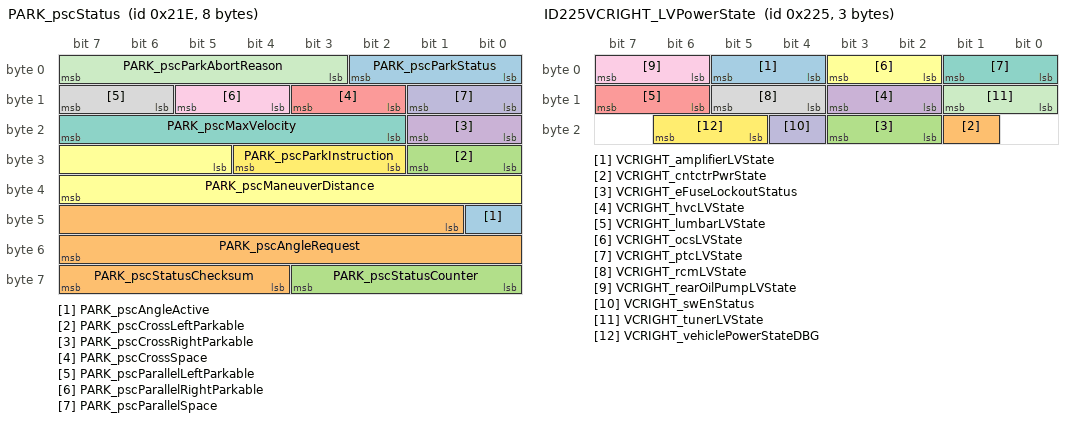
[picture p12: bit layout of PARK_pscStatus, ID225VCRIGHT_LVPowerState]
BO_ 542 PARK_pscStatus: 8 VEH
 SG_ PARK_pscAngleActive : 40|1@1+ (1,0) [0|0] "" Vector__XXX
 SG_ PARK_pscAngleRequest : 41|15@1+ (0.1,-1638.4) [0|0] "deg" Vector__XXX
 SG_ PARK_pscCrossLeftParkable : 24|2@1+ (1,0) [0|0] "" Vector__XXX
 SG_ PARK_pscCrossRightParkable : 16|2@1+ (1,0) [0|0] "" Vector__XXX
 SG_ PARK_pscCrossSpace : 10|2@1+ (1,0) [0|0] "" Vector__XXX
 SG_ PARK_pscManeuverDistance : 29|11@1+ (1,0) [0|0] "cm" Vector__XXX
 SG_ PARK_pscMaxVelocity : 18|6@1+ (0.1,0) [0|0] "kph" Vector__XXX
 SG_ PARK_pscParallelLeftParkable : 14|2@1+ (1,0) [0|0] "" Vector__XXX
 SG_ PARK_pscParallelRightParkable : 12|2@1+ (1,0) [0|0] "" Vector__XXX
 SG_ PARK_pscParallelSpace : 8|2@1+ (1,0) [0|0] "" Vector__XXX
 SG_ PARK_pscParkAbortReason : 3|5@1+ (1,0) [0|0] "" Vector__XXX
 SG_ PARK_pscParkInstruction : 26|3@1+ (1,0) [0|0] "" Vector__XXX
 SG_ PARK_pscParkStatus : 0|3@1+ (1,0) [0|0] "" Vector__XXX
 SG_ PARK_pscStatusChecksum : 60|4@1+ (1,0) [0|0] "" Vector__XXX
 SG_ PARK_pscStatusCounter : 56|4@1+ (1,0) [0|0] "" Vector__XXX

BO_ 545 VCFRONT_LVPowerState: 8 VEH
 SG_ VCFRONT_LVPowerStateChecksum : 56|8@1+ (1,0) [0|0] "" Vector__XXX
 SG_ VCFRONT_LVPowerStateCounter : 52|4@1+ (1,0) [0|0] "" Vector__XXX
 SG_ VCFRONT_LVPowerStateIndex M : 0|5@1+ (1,0) [0|0] "" Vector__XXX
 SG_ VCFRONT_vehiclePowerState : 5|2@1+ (1,0) [0|0] "" Vector__XXX
 SG_ VCFRONT_parkLVState m0 : 8|2@1+ (1,0) [0|0] "" Vector__XXX
 SG_ VCFRONT_espLVState m0 : 10|2@1+ (1,0) [0|0] "" Vector__XXX
 SG_ VCFRONT_radcLVState m0 : 12|2@1+ (1,0) [0|0] "" Vector__XXX
 SG_ VCFRONT_hvacCompLVState m0 : 14|2@1+ (1,0) [0|0] "" Vector__XXX
 SG_ VCFRONT_ptcLVRequest m0 : 16|2@1+ (1,0) [0|0] "" Vector__XXX
 SG_ VCFRONT_sccmLVRequest m0 : 18|2@1+ (1,0) [0|0] "" Vector__XXX
 SG_ VCFRONT_tpmsLVRequest m0 : 20|2@1+ (1,0) [0|0] "" Vector__XXX
 SG_ VCFRONT_rcmLVRequest m0 : 22|2@1+ (1,0) [0|0] "" Vector__XXX
 SG_ VCFRONT_iBoosterLVState m0 : 24|2@1+ (1,0) [0|0] "" Vector__XXX
 SG_ VCFRONT_tunerLVRequest m0 : 26|2@1+ (1,0) [0|0] "" Vector__XXX
 SG_ VCFRONT_amplifierLVRequest m0 : 28|2@1+ (1,0) [0|0] "" Vector__XXX
 SG_ VCFRONT_das1HighCurrentLVState m0 : 30|2@1+ (1,0) [0|0] "" Vector__XXX
 SG_ VCFRONT_das2HighCurrentLVState m0 : 32|2@1+ (1,0) [0|0] "" Vector__XXX
 SG_ VCFRONT_diLVRequest m0 : 34|2@1+ (1,0) [0|0] "" Vector__XXX
 SG_ VCFRONT_disLVState m0 : 36|2@1+ (1,0) [0|0] "" Vector__XXX
 SG_ VCFRONT_oilPumpFrontLVState m0 : 38|2@1+ (1,0) [0|0] "" Vector__XXX
 SG_ VCFRONT_oilPumpRearLVRequest m0 : 40|2@1+ (1,0) [0|0] "" Vector__XXX
 SG_ VCFRONT_ocsLVRequest m0 : 42|2@1+ (1,0) [0|0] "" Vector__XXX
 SG_ VCFRONT_vcleftHiCurrentLVState m0 : 44|2@1+ (1,0) [0|0] "" Vector__XXX
 SG_ VCFRONT_vcrightHiCurrentLVState m0 : 46|2@1+ (1,0) [0|0] "" Vector__XXX
 SG_ VCFRONT_uiHiCurrentLVState m0 : 48|2@1+ (1,0) [0|0] "" Vector__XXX
 SG_ VCFRONT_uiAudioLVState m0 : 50|2@1+ (1,0) [0|0] "" Vector__XXX
 SG_ VCFRONT_cpLVRequest m1 : 8|2@1+ (1,0) [0|0] "" Vector__XXX
 SG_ VCFRONT_epasLVState m1 : 10|2@1+ (1,0) [0|0] "" Vector__XXX
 SG_ VCFRONT_hvcLVRequest m1 : 12|2@1+ (1,0) [0|0] "" Vector__XXX
 SG_ VCFRONT_tasLVState m1 : 14|2@1+ (1,0) [0|0] "" Vector__XXX
 SG_ VCFRONT_pcsLVState m1 : 16|2@1+ (1,0) [0|0] "" Vector__XXX

BO_ 548 PCS_dcdcStatus: 8 VEH
 SG_ PCS_dcdc12VSupportRtyCnt : 44|4@1+ (1,0) [0|0] "" Vector__XXX
 SG_ PCS_dcdc12VSupportStatus : 2|2@1+ (1,0) [0|0] "" Vector__XXX
 SG_ PCS_dcdcDischargeRtyCnt : 48|4@1+ (1,0) [0|0] "" Vector__XXX
 SG_ PCS_dcdcFaulted : 15|1@1+ (1,0) [0|0] "" Vector__XXX
 SG_ PCS_dcdcHvBusDischargeStatus : 4|2@1+ (1,0) [0|0] "" Vector__XXX
 SG_ PCS_dcdcInitialPrechargeSubState : 59|5@1+ (1,0) [0|0] "" Vector__XXX
 SG_ DCDCoutputCurrent224 : 16|12@1+ (0.1,0) [0|409.5] "A"  Receiver
 SG_ PCS_dcdcMainState : 6|4@1+ (1,0) [0|0] "" Vector__XXX
 SG_ PCS_dcdcMaxOutputCurrentAllowed : 29|12@1+ (0.1,0) [0|0] "A" Vector__XXX
 SG_ PCS_dcdcOutputIsLimited : 28|1@1+ (1,0) [0|0] "" Vector__XXX
 SG_ PCS_dcdcPrechargeRestartCnt : 56|3@1+ (1,0) [0|0] "" Vector__XXX
 SG_ PCS_dcdcPrechargeRtyCnt : 41|3@1+ (1,0) [0|0] "" Vector__XXX
 SG_ PCS_dcdcPrechargeStatus : 0|2@1+ (1,0) [0|0] "" Vector__XXX
 SG_ PCS_dcdcPwmEnableLine : 52|1@1+ (1,0) [0|0] "" Vector__XXX
 SG_ PCS_dcdcSubState : 10|5@1+ (1,0) [0|0] "" Vector__XXX
 SG_ PCS_dcdcSupportingFixedLvTarget : 53|1@1+ (1,0) [0|0] "" Vector__XXX
 SG_ PCS_ecuLogUploadRequest : 54|2@1+ (1,0) [0|0] "" Vector__XXX

BO_ 549 ID225VCRIGHT_LVPowerState: 3 VehicleBus
 SG_ VCRIGHT_amplifierLVState : 4|2@1+ (1,0) [0|3] ""  Receiver
 SG_ VCRIGHT_cntctrPwrState : 17|1@1+ (1,0) [0|1] ""  Receiver
 SG_ VCRIGHT_eFuseLockoutStatus : 18|2@1+ (1,0) [0|2] ""  Receiver
 SG_ VCRIGHT_hvcLVState : 10|2@1+ (1,0) [0|3] ""  Receiver
 SG_ VCRIGHT_lumbarLVState : 14|2@1+ (1,0) [0|3] ""  Receiver
 SG_ VCRIGHT_ocsLVState : 2|2@1+ (1,0) [0|3] ""  Receiver
 SG_ VCRIGHT_ptcLVState : 0|2@1+ (1,0) [0|3] ""  Receiver
 SG_ VCRIGHT_rcmLVState : 12|2@1+ (1,0) [0|3] ""  Receiver
 SG_ VCRIGHT_rearOilPumpLVState : 6|2@1+ (1,0) [0|3] ""  Receiver
 SG_ VCRIGHT_swEnStatus : 20|1@1+ (1,0) [0|1] ""  Receiver
 SG_ VCRIGHT_tunerLVState : 8|2@1+ (1,0) [0|3] ""  Receiver
 SG_ VCRIGHT_vehiclePowerStateDBG : 21|2@1+ (1,0) [0|3] ""  Receiver

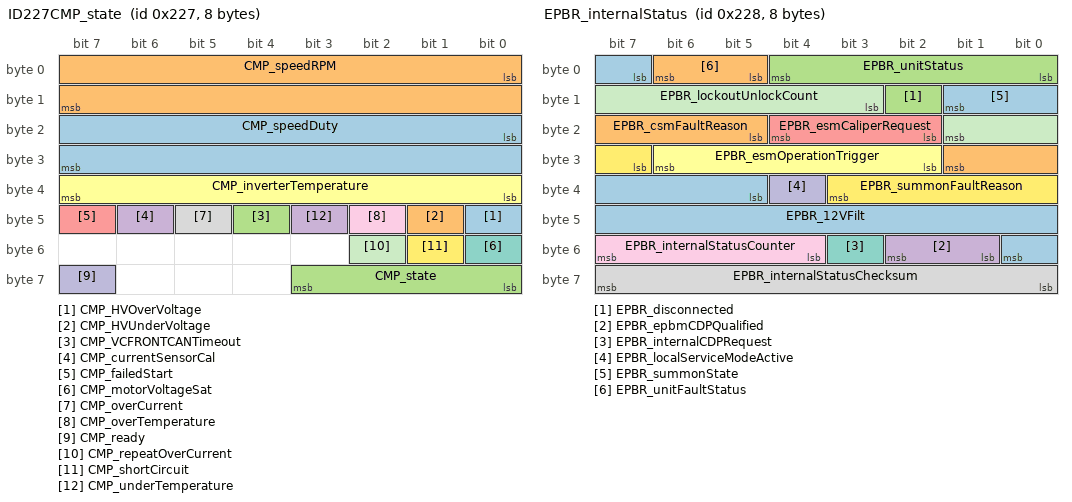
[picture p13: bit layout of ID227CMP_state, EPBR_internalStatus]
BO_ 551 ID227CMP_state: 8 VehicleBus
 SG_ CMP_HVOverVoltage : 40|1@1+ (1,0) [0|1] ""  Receiver
 SG_ CMP_HVUnderVoltage : 41|1@1+ (1,0) [0|1] ""  Receiver
 SG_ CMP_VCFRONTCANTimeout : 44|1@1+ (1,0) [0|1] ""  Receiver
 SG_ CMP_currentSensorCal : 46|1@1+ (1,0) [0|1] ""  Receiver
 SG_ CMP_failedStart : 47|1@1+ (1,0) [0|1] ""  Receiver
 SG_ CMP_inverterTemperature : 32|8@1+ (1,-40) [-40|200] "C"  Receiver
 SG_ CMP_motorVoltageSat : 48|1@1+ (1,0) [0|1] ""  Receiver
 SG_ CMP_overCurrent : 45|1@1+ (1,0) [0|1] ""  Receiver
 SG_ CMP_overTemperature : 42|1@1+ (1,0) [0|1] ""  Receiver
 SG_ CMP_ready : 63|1@1+ (1,0) [0|1] ""  Receiver
 SG_ CMP_repeatOverCurrent : 50|1@1+ (1,0) [0|1] ""  Receiver
 SG_ CMP_shortCircuit : 49|1@1+ (1,0) [0|1] ""  Receiver
 SG_ CMP_speedDuty : 16|16@1+ (0.1,0) [0|100] "%"  Receiver
 SG_ CMP_speedRPM : 0|16@1+ (1,0) [0|65534] "RPM"  Receiver
 SG_ CMP_state : 56|4@1+ (1,0) [0|15] ""  Receiver
 SG_ CMP_underTemperature : 43|1@1+ (1,0) [0|1] ""  Receiver

BO_ 552 EPBR_internalStatus: 8 VEH
 SG_ EPBR_12VFilt : 37|12@1+ (0.00544368,0) [0|0] "V" Vector__XXX
 SG_ EPBR_csmFaultReason : 21|5@1+ (1,0) [0|0] "" Vector__XXX
 SG_ EPBR_disconnected : 10|1@1+ (1,0) [0|0] "" Vector__XXX
 SG_ EPBR_epbmCDPQualified : 49|2@1+ (1,0) [0|0] "" Vector__XXX
 SG_ EPBR_esmCaliperRequest : 18|3@1+ (1,0) [0|0] "" Vector__XXX
 SG_ EPBR_esmOperationTrigger : 26|5@1+ (1,0) [0|0] "" Vector__XXX
 SG_ EPBR_internalCDPRequest : 51|1@1+ (1,0) [0|0] "" Vector__XXX
 SG_ EPBR_internalStatusChecksum : 56|8@1+ (1,0) [0|0] "" Vector__XXX
 SG_ EPBR_internalStatusCounter : 52|4@1+ (1,0) [0|0] "" Vector__XXX
 SG_ EPBR_localServiceModeActive : 36|1@1+ (1,0) [0|0] "" Vector__XXX
 SG_ EPBR_lockoutUnlockCount : 11|7@1+ (1,0) [0|0] "" Vector__XXX
 SG_ EPBR_summonFaultReason : 31|5@1+ (1,0) [0|0] "" Vector__XXX
 SG_ EPBR_summonState : 7|3@1+ (1,0) [0|0] "" Vector__XXX
 SG_ EPBR_unitFaultStatus : 5|2@1+ (1,0) [0|0] "" Vector__XXX
 SG_ EPBR_unitStatus : 0|5@1+ (1,0) [0|0] "" Vector__XXX

BO_ 553 SCCM_rightStalk: 3 VEH
 SG_ SCCM_rightStalkChecksum : 0|8@1+ (1,0) [0|0] "" Vector__XXX
 SG_ SCCM_rightStalkCounter : 8|4@1+ (1,0) [0|0] "" Vector__XXX
 SG_ SCCM_gearStalkStatus : 12|3@1+ (1,0) [0|7] "" Vector__XXX
 SG_ SCCM_parkButtonStatus : 16|2@1+ (1,0) [0|3] "" Vector__XXX

BO_ 554 ID22AHVP_pcsControl: 4 VehicleBus
 SG_ HVP_dcLinkVoltageFiltered : 20|11@1- (1,0) [-550|550] "V"  Receiver
 SG_ HVP_dcLinkVoltageRequest : 0|16@1- (0.1,0) [-550|550] "V"  Receiver
 SG_ HVP_pcsChargeHwEnabled : 18|1@1+ (1,0) [0|1] ""  Receiver
 SG_ HVP_pcsControlRequest : 16|2@1+ (1,0) [0|3] ""  Receiver
 SG_ HVP_pcsDcdcHwEnabled : 19|1@1+ (1,0) [0|1] ""  Receiver

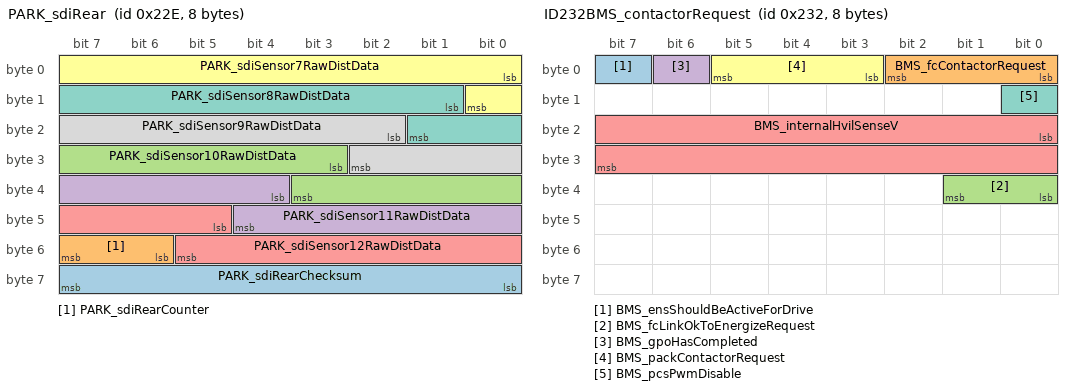
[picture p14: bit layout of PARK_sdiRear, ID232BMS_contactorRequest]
BO_ 558 PARK_sdiRear: 8 CH
 SG_ PARK_sdiRearChecksum : 56|8@1+ (1,0) [0|0] "" Vector__XXX
 SG_ PARK_sdiRearCounter : 54|2@1+ (1,0) [0|0] "" Vector__XXX
 SG_ PARK_sdiSensor10RawDistData : 27|9@1+ (1,0) [0|0] "cm" Vector__XXX
 SG_ PARK_sdiSensor11RawDistData : 36|9@1+ (1,0) [0|0] "cm" Vector__XXX
 SG_ PARK_sdiSensor12RawDistData : 45|9@1+ (1,0) [0|0] "cm" Vector__XXX
 SG_ PARK_sdiSensor7RawDistData : 0|9@1+ (1,0) [0|0] "cm" Vector__XXX
 SG_ PARK_sdiSensor8RawDistData : 9|9@1+ (1,0) [0|0] "cm" Vector__XXX
 SG_ PARK_sdiSensor9RawDistData : 18|9@1+ (1,0) [0|0] "cm" Vector__XXX

BO_ 562 ID232BMS_contactorRequest: 8 VehicleBus
 SG_ BMS_ensShouldBeActiveForDrive : 7|1@1+ (1,0) [0|1] ""  Receiver
 SG_ BMS_fcContactorRequest : 0|3@1+ (1,0) [0|5] ""  Receiver
 SG_ BMS_fcLinkOkToEnergizeRequest : 32|2@1+ (1,0) [0|2] ""  Receiver
 SG_ BMS_gpoHasCompleted : 6|1@1+ (1,0) [0|1] ""  Receiver
 SG_ BMS_internalHvilSenseV : 16|16@1+ (0.001,0) [0|65.534] "V"  Receiver
 SG_ BMS_packContactorRequest : 3|3@1+ (1,0) [0|5] ""  Receiver
 SG_ BMS_pcsPwmDisable : 8|1@1+ (1,0) [0|1] ""  Receiver

BO_ 568 UI_driverAssistMapData: 8 CH
 SG_ UI_acceptBottsDots : 48|1@1+ (1,0) [0|0] "" Vector__XXX
 SG_ UI_autosteerRestricted : 49|1@1+ (1,0) [0|0] "" Vector__XXX
 SG_ UI_controlledAccess : 37|1@1+ (1,0) [0|0] "" Vector__XXX
 SG_ UI_countryCode : 16|10@1+ (1,0) [0|0] "" Vector__XXX
 SG_ UI_gpsRoadMatch : 28|1@1+ (1,0) [0|0] "" Vector__XXX
 SG_ UI_inSuperchargerGeofence : 6|1@1+ (1,0) [0|0] "" Vector__XXX
 SG_ UI_mapDataChecksum : 56|8@1+ (1,0) [0|0] "" Vector__XXX
 SG_ UI_mapDataCounter : 52|4@1+ (1,0) [0|0] "" Vector__XXX
 SG_ UI_mapSpeedLimit : 8|5@1+ (1,0) [0|0] "" Vector__XXX
 SG_ UI_mapSpeedLimitDependency : 0|3@1+ (1,0) [0|0] "" Vector__XXX
 SG_ UI_mapSpeedLimitType : 13|3@1+ (1,0) [0|0] "" Vector__XXX
 SG_ UI_mapSpeedUnits : 7|1@1+ (1,0) [0|0] "" Vector__XXX
 SG_ UI_navRouteActive : 29|1@1+ (1,0) [0|0] "" Vector__XXX
 SG_ UI_nextBranchDist : 32|5@1+ (10,0) [0|0] "m" Vector__XXX
 SG_ UI_nextBranchLeftOffRamp : 38|1@1+ (1,0) [0|0] "" Vector__XXX
 SG_ UI_nextBranchRightOffRamp : 39|1@1+ (1,0) [0|0] "" Vector__XXX
 SG_ UI_parallelAutoparkEnabled : 30|1@1+ (1,0) [0|0] "" Vector__XXX
 SG_ UI_perpendicularAutoparkEnabled : 31|1@1+ (1,0) [0|0] "" Vector__XXX
 SG_ UI_pmmEnabled : 50|1@1+ (1,0) [0|0] "" Vector__XXX
 SG_ UI_rejectAutosteer : 46|1@1+ (1,0) [0|0] "" Vector__XXX
 SG_ UI_rejectHPP : 42|1@1+ (1,0) [0|0] "" Vector__XXX
 SG_ UI_rejectHandsOn : 47|1@1+ (1,0) [0|0] "" Vector__XXX
 SG_ UI_rejectLeftFreeSpace : 44|1@1+ (1,0) [0|0] "" Vector__XXX
 SG_ UI_rejectLeftLane : 40|1@1+ (1,0) [0|0] "" Vector__XXX
 SG_ UI_rejectNav : 43|1@1+ (1,0) [0|0] "" Vector__XXX
 SG_ UI_rejectRightFreeSpace : 45|1@1+ (1,0) [0|0] "" Vector__XXX
 SG_ UI_rejectRightLane : 41|1@1+ (1,0) [0|0] "" Vector__XXX
 SG_ UI_roadClass : 3|3@1+ (1,0) [0|0] "" Vector__XXX
 SG_ UI_scaEnabled : 51|1@1+ (1,0) [0|0] "" Vector__XXX
 SG_ UI_streetCount : 26|2@1+ (1,0) [0|0] "" Vector__XXX

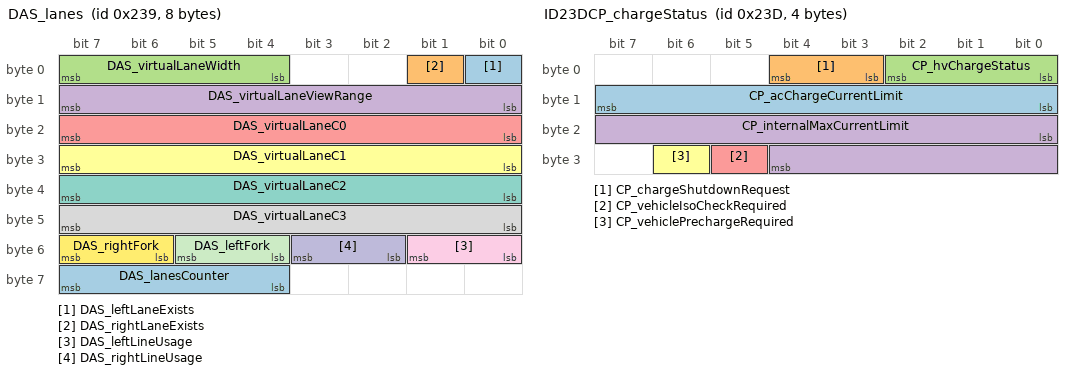
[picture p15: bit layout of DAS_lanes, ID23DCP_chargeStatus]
BO_ 569 DAS_lanes: 8 CH
 SG_ DAS_leftLaneExists : 0|1@1+ (1,0) [0|0] "" Vector__XXX
 SG_ DAS_rightLaneExists : 1|1@1+ (1,0) [0|0] "" Vector__XXX
 SG_ DAS_virtualLaneWidth : 4|4@1+ (0.3125,2) [0|0] "m" Vector__XXX
 SG_ DAS_virtualLaneViewRange : 8|8@1+ (1,0) [0|0] "m" Vector__XXX
 SG_ DAS_virtualLaneC0 : 16|8@1+ (3.5,-350) [0|0] "cm" Vector__XXX
 SG_ DAS_virtualLaneC1 : 24|8@1+ (0.092,-11.46) [0|0] "deg" Vector__XXX
 SG_ DAS_virtualLaneC2 : 32|8@1+ (2e-05,-0.0025) [0|0] "m-1" Vector__XXX
 SG_ DAS_virtualLaneC3 : 40|8@1+ (2.4e-07,-3e-05) [0|0] "m-2" Vector__XXX
 SG_ DAS_leftLineUsage : 48|2@1+ (1,0) [0|0] "" Vector__XXX
 SG_ DAS_rightLineUsage : 50|2@1+ (1,0) [0|0] "" Vector__XXX
 SG_ DAS_leftFork : 52|2@1+ (1,0) [0|0] "" Vector__XXX
 SG_ DAS_rightFork : 54|2@1+ (1,0) [0|0] "" Vector__XXX
 SG_ DAS_lanesCounter : 60|4@1+ (1,0) [0|0] "" Vector__XXX

BO_ 573 ID23DCP_chargeStatus: 4 VehicleBus
 SG_ CP_acChargeCurrentLimit : 8|8@1+ (0.5,0) [0|127.5] "A"  Receiver
 SG_ CP_chargeShutdownRequest : 3|2@1+ (1,0) [0|2] ""  Receiver
 SG_ CP_hvChargeStatus : 0|3@1+ (1,0) [0|6] ""  Receiver
 SG_ CP_internalMaxCurrentLimit : 16|13@1+ (0.146502,0) [0|1200] "A"  Receiver
 SG_ CP_vehicleIsoCheckRequired : 29|1@1+ (1,0) [0|1] ""  Receiver
 SG_ CP_vehiclePrechargeRequired : 30|1@1+ (1,0) [0|1] ""  Receiver

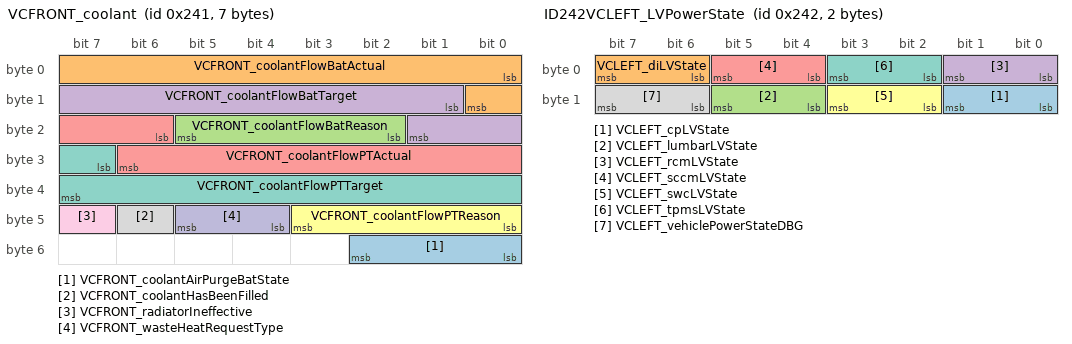
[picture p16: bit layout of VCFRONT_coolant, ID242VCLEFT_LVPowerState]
BO_ 577 VCFRONT_coolant: 7 VEH
 SG_ VCFRONT_coolantAirPurgeBatState : 48|3@1+ (1,0) [0|0] "" Vector__XXX
 SG_ VCFRONT_coolantFlowBatActual : 0|9@1+ (0.1,0) [0|0] "LPM" Vector__XXX
 SG_ VCFRONT_coolantFlowBatReason : 18|4@1+ (1,0) [0|0] "" Vector__XXX
 SG_ VCFRONT_coolantFlowBatTarget : 9|9@1+ (0.1,0) [0|0] "LPM" Vector__XXX
 SG_ VCFRONT_coolantFlowPTActual : 22|9@1+ (0.1,0) [0|0] "LPM" Vector__XXX
 SG_ VCFRONT_coolantFlowPTReason : 40|4@1+ (1,0) [0|0] "" Vector__XXX
 SG_ VCFRONT_coolantFlowPTTarget : 31|9@1+ (0.1,0) [0|0] "LPM" Vector__XXX
 SG_ VCFRONT_coolantHasBeenFilled : 46|1@1+ (1,0) [0|0] "" Vector__XXX
 SG_ VCFRONT_radiatorIneffective : 47|1@1+ (1,0) [0|0] "" Vector__XXX
 SG_ VCFRONT_wasteHeatRequestType : 44|2@1+ (1,0) [0|0] "" Vector__XXX

BO_ 578 ID242VCLEFT_LVPowerState: 2 VehicleBus
 SG_ VCLEFT_cpLVState : 8|2@1+ (1,0) [0|3] ""  Receiver
 SG_ VCLEFT_diLVState : 6|2@1+ (1,0) [0|3] ""  Receiver
 SG_ VCLEFT_lumbarLVState : 12|2@1+ (1,0) [0|3] ""  Receiver
 SG_ VCLEFT_rcmLVState : 0|2@1+ (1,0) [0|3] ""  Receiver
 SG_ VCLEFT_sccmLVState : 4|2@1+ (1,0) [0|3] ""  Receiver
 SG_ VCLEFT_swcLVState : 10|2@1+ (1,0) [0|3] ""  Receiver
 SG_ VCLEFT_tpmsLVState : 2|2@1+ (1,0) [0|3] ""  Receiver
 SG_ VCLEFT_vehiclePowerStateDBG : 14|2@1+ (1,0) [0|3] ""  Receiver

BO_ 579 ID243VCRIGHT_hvacStatus: 8 VehicleBus
 SG_ VCRIGHT_hvacStatusIndex M : 0|2@1+ (1,0) [0|3] ""  Receiver
 SG_ VCRIGHT_hvacACRunning m0 : 50|1@1+ (1,0) [0|1] ""  Receiver
 SG_ VCRIGHT_hvacAirDistributionMode m0 : 41|3@1+ (1,0) [0|7] ""  Receiver
 SG_ VCRIGHT_hvacBlowerSegment m0 : 44|4@1+ (1,0) [0|11] ""  Receiver
 SG_ VCRIGHT_hvacCabinTempEst m0 : 30|11@1+ (0.1,-40) [-40|164] "C"  Receiver
 SG_ VCRIGHT_hvacDuctTargetLeft m1 : 48|8@1+ (0.5,-40) [-40|80] "C"  Receiver
 SG_ VCRIGHT_hvacDuctTargetRight m1 : 56|8@1+ (0.5,-40) [-40|80] "C"  Receiver
 SG_ VCRIGHT_hvacEvapInletTempEstimat m2 : 19|10@1+ (0.13,-40) [-40|90] "C"  Receiver
 SG_ VCRIGHT_hvacMassflowRefrigSystem m1 : 2|8@1+ (1,0) [0|250] "g/s"  Receiver
 SG_ VCRIGHT_hvacModelInitStatus m0 : 60|3@1+ (1,0) [0|5] ""  Receiver
 SG_ VCRIGHT_hvacOverheatProtActive m0 : 63|1@1+ (1,0) [0|1] ""  Receiver
 SG_ VCRIGHT_hvacPowerState m0 : 51|3@1+ (1,0) [0|4] ""  Receiver
 SG_ VCRIGHT_hvacQdotLeft m0 : 2|14@1+ (1,-8191) [-8191|8191] "W"  Receiver
 SG_ VCRIGHT_hvacQdotRight m0 : 16|14@1+ (1,-8191) [-8191|8191] "W"  Receiver
 SG_ VCRIGHT_hvacRecirc m0 : 48|2@1+ (1,0) [0|2] ""  Receiver
 SG_ VCRIGHT_hvacRecircDoorPercent m1 : 10|6@1+ (1.6,0) [0|100] "%"  Receiver
 SG_ VCRIGHT_hvacSecondRowState m0 : 56|3@1+ (1,0) [0|4] ""  Receiver
 SG_ VCRIGHT_hvacSystemNominal m0 : 59|1@1+ (1,0) [0|1] ""  Receiver
 SG_ VCRIGHT_hvacVentStatus m0 : 54|2@1+ (1,0) [0|2] ""  Receiver
 SG_ VCRIGHT_tempDuctLeft m1 : 16|8@1+ (0.5,-22) [-22|105] "C"  Receiver
 SG_ VCRIGHT_tempDuctLeftLower m1 : 24|8@1+ (0.5,-22) [-22|105] "C"  Receiver
 SG_ VCRIGHT_tempDuctLeftUpper m2 : 2|8@1+ (0.5,-22) [-22|105] "C"  Receiver
 SG_ VCRIGHT_tempDuctRight m1 : 32|8@1+ (0.5,-22) [-22|105] "C"  Receiver
 SG_ VCRIGHT_tempDuctRightLower m1 : 40|8@1+ (0.5,-22) [-22|105] "C"  Receiver
 SG_ VCRIGHT_tempDuctRightUpper m2 : 10|8@1+ (0.5,-22) [-22|105] "C"  Receiver

BO_ 580 FC_limits: 8 VEH
 SG_ FC_currentLimit : 16|13@1+ (0.0732422,0) [0|0] "A" Vector__XXX
 SG_ FC_maxVoltageLimit : 32|13@1+ (0.0732422,0) [0|0] "V" Vector__XXX
 SG_ FC_minVoltageLimit : 48|13@1+ (0.0732422,0) [0|0] "V" Vector__XXX
 SG_ FC_powerLimit : 0|13@1+ (0.0622559,0) [0|0] "kW" Vector__XXX

BO_ 583 DAS_autopilotDebug: 8 VEH
 SG_ DAS_autopilotAbortReason : 32|8@1+ (1,0) [0|255] "" Vector__XXX
 SG_ DAS_behaviorReport : 16|6@1+ (1,0) [0|43] "" Vector__XXX
 SG_ DAS_cameraContext : 30|2@1+ (1,0) [0|0] "" Vector__XXX
 SG_ DAS_constructionZone : 23|1@1+ (1,0) [0|0] "" Vector__XXX
 SG_ DAS_controlDistance : 24|6@1+ (2,0) [0|0] "m" Vector__XXX
 SG_ DAS_controlTarget : 12|1@1+ (1,0) [0|0] "" Vector__XXX
 SG_ DAS_controllerHealth : 21|2@1+ (1,0) [0|0] "" Vector__XXX
 SG_ DAS_controllerRef : 9|3@1+ (1,0) [0|0] "" Vector__XXX
 SG_ DAS_forkState : 45|5@1+ (1,0) [0|0] "" Vector__XXX
 SG_ DAS_laneChangeState : 50|6@1+ (1,0) [0|0] "" Vector__XXX
 SG_ DAS_lastWatchdogCode : 56|7@1+ (1,0) [0|0] "" Vector__XXX
 SG_ DAS_mapAvailability : 8|1@1+ (1,0) [0|0] "" Vector__XXX
 SG_ DAS_missionPlan : 0|2@1+ (1,0) [0|0] "" Vector__XXX
 SG_ DAS_roadEstimator : 0|2@1+ (1,0) [0|0] "" Vector__XXX
 SG_ DAS_arbiterBehavior : 2|3@1+ (1,0) [0|4] "" Vector__XXX
 SG_ DAS_rqstedBehaviorStatus : 40|5@1+ (1,0) [0|0] "" Vector__XXX

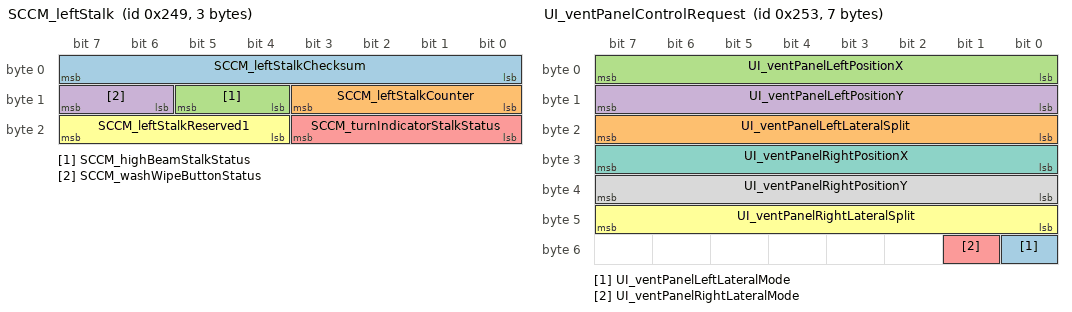
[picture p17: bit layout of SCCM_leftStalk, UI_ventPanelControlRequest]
BO_ 585 SCCM_leftStalk: 3 VEH
 SG_ SCCM_leftStalkChecksum : 0|8@1+ (1,0) [0|0] "" Vector__XXX
 SG_ SCCM_leftStalkCounter : 8|4@1+ (1,0) [0|0] "" Vector__XXX
 SG_ SCCM_highBeamStalkStatus : 12|2@1+ (1,0) [0|0] "" Vector__XXX
 SG_ SCCM_washWipeButtonStatus : 14|2@1+ (1,0) [0|0] "" Vector__XXX
 SG_ SCCM_turnIndicatorStalkStatus : 16|4@1+ (1,0) [0|0] "" Vector__XXX
 SG_ SCCM_leftStalkReserved1 : 20|4@1+ (1,0) [0|0] "" Vector__XXX

BO_ 586 DAS_visualDebug: 8 CH
 SG_ DAS_accSmartSpeedActive : 48|1@1+ (1,0) [0|0] "" Vector__XXX
 SG_ DAS_accSmartSpeedState : 49|3@1+ (1,0) [0|0] "" Vector__XXX
 SG_ DAS_autosteerBottsDotsUsage : 12|2@1+ (1,0) [0|0] "" Vector__XXX
 SG_ DAS_autosteerHPPUsage : 6|2@1+ (1,0) [0|0] "" Vector__XXX
 SG_ DAS_autosteerHealthAnomalyLevel : 18|3@1+ (1,0) [0|0] "" Vector__XXX
 SG_ DAS_autosteerHealthState : 21|3@1+ (1,0) [0|0] "" Vector__XXX
 SG_ DAS_autosteerModelUsage : 10|2@1+ (1,0) [0|0] "" Vector__XXX
 SG_ DAS_autosteerNavigationUsage : 8|2@1+ (1,0) [0|0] "" Vector__XXX
 SG_ DAS_autosteerVehiclesUsage : 4|2@1+ (1,0) [0|0] "" Vector__XXX
 SG_ DAS_behaviorType : 56|2@1+ (1,0) [0|0] "" Vector__XXX
 SG_ DAS_devAppInterfaceEnabled : 38|1@1+ (1,0) [0|0] "" Vector__XXX
 SG_ DAS_lastAutosteerAbortReason : 32|6@1+ (1,0) [0|0] "" Vector__XXX
 SG_ DAS_lastLinePreferenceReason : 24|4@1+ (1,0) [0|0] "" Vector__XXX
 SG_ DAS_navAvailable : 39|1@1+ (1,0) [0|0] "" Vector__XXX
 SG_ DAS_navDistance : 40|8@1+ (100,0) [0|0] "km" Vector__XXX
 SG_ DAS_offsetSide : 14|2@1+ (1,0) [0|0] "" Vector__XXX
 SG_ DAS_plannerState : 28|4@1+ (1,0) [0|0] "" Vector__XXX
 SG_ DAS_roadSurfaceType : 16|2@1+ (1,0) [0|0] "" Vector__XXX
 SG_ DAS_ulcInProgress : 52|1@1+ (1,0) [0|0] "" Vector__XXX
 SG_ DAS_ulcType : 58|1@1+ (1,0) [0|0] "" Vector__XXX
 SG_ DAS_rearLeftVehDetectedCurrent : 61|1@1+ (1,0) [0|1] ""  Receiver
 SG_ DAS_rearLeftVehDetectedTrip : 63|1@1+ (1,0) [0|1] ""  Receiver
 SG_ DAS_rearRightVehDetectedTrip : 62|1@1+ (1,0) [0|1] ""  Receiver
 SG_ DAS_rearVehDetectedThisCycle : 60|1@1+ (1,0) [0|1] ""  Receiver

BO_ 590 PARK_pscVehSlot: 8 CH
 SG_ PARK_pscVehSlotType M : 0|2@1+ (1,0) [0|0] "" Vector__XXX
 SG_ PARK_pscLeftParallelVehX m0 : 5|11@1+ (2,-2048) [0|0] "cm" Vector__XXX
 SG_ PARK_pscLeftParallelVehY m0 : 16|11@1+ (2,-2048) [0|0] "cm" Vector__XXX
 SG_ PARK_pscLeftParallelPsi m0 : 32|13@1+ (0.000976563,0) [0|0] "radians" Vector__XXX
 SG_ PARK_pscLeftParallelSizeX m0 : 48|8@1+ (4,0) [0|0] "cm" Vector__XXX
 SG_ PARK_pscLeftParallelSizeY m0 : 56|8@1+ (4,0) [0|0] "cm" Vector__XXX
 SG_ PARK_pscLeftCrossVehX m1 : 5|11@1+ (2,-2048) [0|0] "cm" Vector__XXX
 SG_ PARK_pscLeftCrossVehY m1 : 16|11@1+ (2,-2048) [0|0] "cm" Vector__XXX
 SG_ PARK_pscLeftCrossPsi m1 : 32|13@1+ (0.000976563,0) [0|0] "radians" Vector__XXX
 SG_ PARK_pscLeftCrossSizeX m1 : 48|8@1+ (4,0) [0|0] "cm" Vector__XXX
 SG_ PARK_pscLeftCrossSizeY m1 : 56|8@1+ (4,0) [0|0] "cm" Vector__XXX
 SG_ PARK_pscRightParallelVehX m2 : 5|11@1+ (2,-2048) [0|0] "cm" Vector__XXX
 SG_ PARK_pscRightParallelVehY m2 : 16|11@1+ (2,-2048) [0|0] "cm" Vector__XXX
 SG_ PARK_pscRightParallelPsi m2 : 32|13@1+ (0.000976563,0) [0|0] "radians" Vector__XXX
 SG_ PARK_pscRightParallelSizeX m2 : 48|8@1+ (4,0) [0|0] "cm" Vector__XXX
 SG_ PARK_pscRightParallelSizeY m2 : 56|8@1+ (4,0) [0|0] "cm" Vector__XXX
 SG_ PARK_pscRightCrossVehX m3 : 5|11@1+ (2,-2048) [0|0] "cm" Vector__XXX
 SG_ PARK_pscRightCrossVehY m3 : 16|11@1+ (2,-2048) [0|0] "cm" Vector__XXX
 SG_ PARK_pscRightCrossPsi m3 : 32|13@1+ (0.000976563,0) [0|0] "radians" Vector__XXX
 SG_ PARK_pscRightCrossSizeX m3 : 48|8@1+ (4,0) [0|0] "cm" Vector__XXX
 SG_ PARK_pscRightCrossSizeY m3 : 56|8@1+ (4,0) [0|0] "cm" Vector__XXX

BO_ 594 BMS_powerAvailable: 8 VEH
 SG_ BMS_hvacPowerBudget : 50|10@1+ (0.02,0) [0|0] "kW" Vector__XXX
 SG_ BMS_maxDischargePower : 16|16@1+ (0.01,0) [0|0] "kW" Vector__XXX
 SG_ BMS_maxRegenPower : 0|16@1+ (0.01,0) [0|0] "kW" Vector__XXX
 SG_ BMS_maxStationaryHeatPower : 32|10@1+ (0.01,0) [0|0] "kW" Vector__XXX
 SG_ BMS_powerLimitsState : 48|1@1+ (1,0) [0|0] "" Vector__XXX
 SG_ BMS_inverterTQF : 56|2@1+ (1,0) [0|3] "" Vector__XXX

BO_ 595 UI_ventPanelControlRequest: 7 VEH
 SG_ UI_ventPanelLeftLateralMode : 48|1@1+ (1,0) [0|0] "" Vector__XXX
 SG_ UI_ventPanelLeftLateralSplit : 16|8@1+ (0.5,0) [0|0] "%" Vector__XXX
 SG_ UI_ventPanelLeftPositionX : 0|8@1+ (0.5,0) [0|0] "%" Vector__XXX
 SG_ UI_ventPanelLeftPositionY : 8|8@1+ (0.5,0) [0|0] "%" Vector__XXX
 SG_ UI_ventPanelRightLateralMode : 49|1@1+ (1,0) [0|0] "" Vector__XXX
 SG_ UI_ventPanelRightLateralSplit : 40|8@1+ (0.5,0) [0|0] "%" Vector__XXX
 SG_ UI_ventPanelRightPositionX : 24|8@1+ (0.5,0) [0|0] "%" Vector__XXX
 SG_ UI_ventPanelRightPositionY : 32|8@1+ (0.5,0) [0|0] "%" Vector__XXX

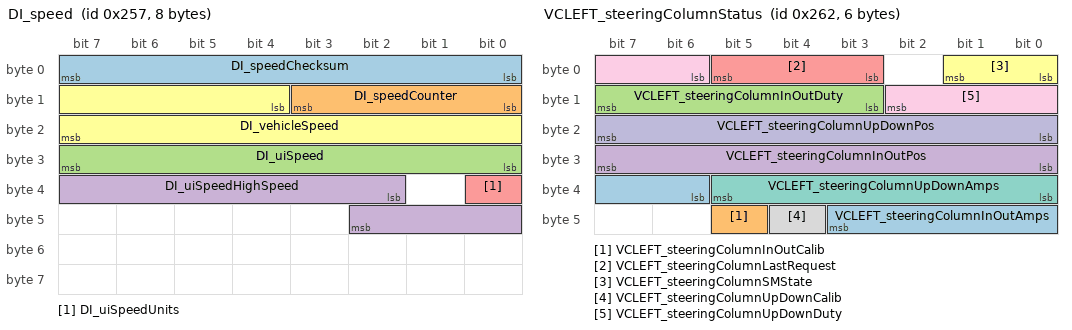
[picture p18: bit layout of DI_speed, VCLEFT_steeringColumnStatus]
BO_ 599 DI_speed: 8 VEH
 SG_ DI_speedChecksum : 0|8@1+ (1,0) [0|255] "" Vector__XXX
 SG_ DI_speedCounter : 8|4@1+ (1,0) [0|15] "" Vector__XXX
 SG_ DI_uiSpeed : 24|8@1+ (1,0) [0|510] "" Vector__XXX
 SG_ DI_uiSpeedHighSpeed : 34|9@1+ (1,0) [0|510] ""  Receiver
 SG_ DI_uiSpeedUnits : 32|1@1+ (1,0) [0|0] "" Vector__XXX
 SG_ DI_vehicleSpeed : 12|12@1+ (0.08,-40) [0|0] "kph" Vector__XXX

BO_ 600 APB_status: 8 CH
 SG_ APB_statusChecksum : 56|8@1+ (1,0) [0|0] "" Vector__XXX
 SG_ APB_statusCounter : 52|4@1+ (1,0) [0|0] "" Vector__XXX
 SG_ APB_watchdogState : 0|3@1+ (1,0) [0|0] "" Vector__XXX

BO_ 601 APP_status: 8 CH
 SG_ APP_statusChecksum : 56|8@1+ (1,0) [0|0] "" Vector__XXX
 SG_ APP_statusCounter : 52|4@1+ (1,0) [0|0] "" Vector__XXX
 SG_ APP_watchdogState : 0|3@1+ (1,0) [0|0] "" Vector__XXX

BO_ 602 TPMS_bluetoothData: 8 CH
 SG_ TPMS_btPressureFL : 0|8@1+ (0.025,0) [0|6.375] "bar" Vector__XXX
 SG_ TPMS_btPressureFR : 8|8@1+ (0.025,0) [0|6.375] "bar" Vector__XXX
 SG_ TPMS_btPressureRL : 16|8@1+ (0.025,0) [0|6.375] "bar" Vector__XXX
 SG_ TPMS_btPressureRR : 24|8@1+ (0.025,0) [0|6.375] "bar" Vector__XXX
 SG_ TPMSFLunknown : 32|8@1+ (1,0) [0|0] "" Vector__XXX
 SG_ TPMSFRunknown : 40|8@1+ (1,0) [0|0] "" Vector__XXX
 SG_ TPMSRLunknown : 48|8@1+ (1,0) [0|0] "" Vector__XXX
 SG_ TPMSRRunknown : 56|8@1+ (1,0) [0|0] "" Vector__XXX

BO_ 603 APP_environment: 1 CH
 SG_ APP_environmentRainy : 0|1@1+ (1,0) [0|1] "" Vector__XXX
 SG_ APP_environmentSnowy : 1|1@1+ (1,0) [0|1] "" Vector__XXX

BO_ 605 CP_status: 8 VEH
 SG_ CP_UHF_controlState : 38|4@1+ (1,0) [0|10] ""  Receiver
 SG_ CP_UHF_handleFound : 42|1@1+ (1,0) [0|1] ""  Receiver
 SG_ CP_apsVoltage : 24|8@1+ (0.0715686,0) [0|18.249] "V" Vector__XXX
 SG_ CP_chargeCablePresent : 3|1@1+ (1,0) [0|1] "" Vector__XXX
 SG_ CP_chargeCableSecured : 4|1@1+ (1,0) [0|1] ""  Receiver
 SG_ CP_chargeCableState : 14|2@1+ (1,0) [0|2] ""  Receiver
 SG_ CP_chargeDoorOpen : 10|1@1+ (1,0) [0|1] ""  Receiver
 SG_ CP_chargeDoorOpenUI : 51|1@1+ (1,0) [0|1] ""  Receiver
 SG_ CP_coldWeatherMode : 60|1@1+ (1,0) [0|1] ""  Receiver
 SG_ CP_coverClosed : 63|1@1+ (1,0) [0|1] ""  Receiver
 SG_ CP_doorButtonPressed : 32|1@1+ (1,0) [0|1] ""  Receiver
 SG_ CP_doorControlState : 11|3@1+ (1,0) [0|6] ""  Receiver
 SG_ CP_doorOpenRequested : 43|1@1+ (1,0) [0|1] ""  Receiver
 SG_ CP_faultLineSensed : 44|1@1+ (1,0) [0|1] ""  Receiver
 SG_ CP_hvInletExposed : 61|1@1+ (1,0) [0|1] ""  Receiver
 SG_ CP_inductiveDoorState : 45|3@1+ (1,0) [0|7] ""  Receiver
 SG_ CP_inductiveSensorState : 48|3@1+ (1,0) [0|7] ""  Receiver
 SG_ CP_insertEnableLine : 2|1@1+ (1,0) [0|1] ""  Receiver
 SG_ CP_latch2ControlState : 19|3@1+ (1,0) [0|5] ""  Receiver
 SG_ CP_latch2State : 8|2@1+ (1,0) [0|3] ""  Receiver
 SG_ CP_latchControlState : 16|3@1+ (1,0) [0|5] ""  Receiver
 SG_ CP_latchEngaged : 62|1@1+ (1,0) [0|1] ""  Receiver
 SG_ CP_latchState : 5|2@1+ (1,0) [0|3] ""  Receiver
 SG_ CP_ledColor : 33|4@1+ (1,0) [0|10] ""  Receiver
 SG_ CP_numAlertsSet : 53|7@1+ (1,0) [0|127] ""  Receiver
 SG_ CP_permanentPowerRequest : 7|1@1+ (1,0) [0|1] ""  Receiver
 SG_ CP_swcanRelayClosed : 37|1@1+ (1,0) [0|1] ""  Receiver
 SG_ CP_type : 0|2@1+ (1,0) [0|3] ""  Receiver
 SG_ CP_vehicleUnlockRequest : 52|1@1+ (1,0) [0|1] ""  Receiver

BO_ 606 PARK_pscEnvSlot: 8 CH
 SG_ PARK_pscEnvSlotType M : 0|2@1+ (1,0) [0|0] "" Vector__XXX
 SG_ PARK_pscLeftParallelObj1X m0 : 3|11@1+ (2,-2048) [0|0] "cm" Vector__XXX
 SG_ PARK_pscLeftParallelObj1Y m0 : 14|11@1+ (2,-2048) [0|0] "cm" Vector__XXX
 SG_ PARK_pscLeftParallelObj1Alpha m0 : 25|7@1+ (2,-128) [0|0] "deg" Vector__XXX
 SG_ PARK_pscLeftParallelObj2Y m0 : 35|11@1+ (2,-2048) [0|0] "cm" Vector__XXX
 SG_ PARK_pscLeftParallelObj2X m0 : 46|11@1+ (2,-2048) [0|0] "cm" Vector__XXX
 SG_ PARK_pscLeftParallelObj2Alpha m0 : 57|7@1+ (2,-128) [0|0] "deg" Vector__XXX
 SG_ PARK_pscLeftCrossObj1X m1 : 3|11@1+ (2,-2048) [0|0] "cm" Vector__XXX
 SG_ PARK_pscLeftCrossObj1Y m1 : 14|11@1+ (2,-2048) [0|0] "cm" Vector__XXX
 SG_ PARK_pscLeftCrossObj1Alpha m1 : 25|7@1+ (2,-128) [0|0] "deg" Vector__XXX
 SG_ PARK_pscLeftCrossObj2Y m1 : 35|11@1+ (2,-2048) [0|0] "cm" Vector__XXX
 SG_ PARK_pscLeftCrossObj2X m1 : 46|11@1+ (2,-2048) [0|0] "cm" Vector__XXX
 SG_ PARK_pscLeftCrossObj2Alpha m1 : 57|7@1+ (2,-128) [0|0] "deg" Vector__XXX
 SG_ PARK_pscRightParallelObj1X m2 : 3|11@1+ (2,-2048) [0|0] "cm" Vector__XXX
 SG_ PARK_pscRightParallelObj1Y m2 : 14|11@1+ (2,-2048) [0|0] "cm" Vector__XXX
 SG_ PARK_pscRightParallelObj1Alpha m2 : 25|7@1+ (2,-128) [0|0] "deg" Vector__XXX
 SG_ PARK_pscRightParallelObj2Y m2 : 35|11@1+ (2,-2048) [0|0] "cm" Vector__XXX
 SG_ PARK_pscRightParallelObj2X m2 : 46|11@1+ (2,-2048) [0|0] "cm" Vector__XXX
 SG_ PARK_pscRightParallelObj2Alpha m2 : 57|7@1+ (2,-128) [0|0] "deg" Vector__XXX
 SG_ PARK_pscRightCrossObj1X m3 : 3|11@1+ (2,-2048) [0|0] "cm" Vector__XXX
 SG_ PARK_pscRightCrossObj1Y m3 : 14|11@1+ (2,-2048) [0|0] "cm" Vector__XXX
 SG_ PARK_pscRightCrossObj1Alpha m3 : 25|7@1+ (2,-128) [0|0] "deg" Vector__XXX
 SG_ PARK_pscRightCrossObj2Y m3 : 35|11@1+ (2,-2048) [0|0] "cm" Vector__XXX
 SG_ PARK_pscRightCrossObj2X m3 : 46|11@1+ (2,-2048) [0|0] "cm" Vector__XXX
 SG_ PARK_pscRightCrossObj2Alpha m3 : 57|7@1+ (2,-128) [0|0] "deg" Vector__XXX

BO_ 609 ID261_12vBattStatus: 8 VehicleBus
 SG_ VCFRONT_12VBatteryStatusChecksum : 56|8@1+ (1,0) [0|0] ""  Receiver
 SG_ VCFRONT_12VBatteryStatusCounter : 52|4@1+ (1,0) [0|0] ""  Receiver
 SG_ VCFRONT_LVBatteryDisconnected m1 : 50|1@1+ (1,0) [0|0] ""  Receiver
 SG_ VCFRONT_LVBatterySupported m1 : 49|1@1+ (1,0) [0|0] ""  Receiver
 SG_ VCFRONT_voltageFloorReachedCount m0 : 48|4@1+ (1,0) [0|0] ""  Receiver
 SG_ VCFRONT_reverseBatteryFault m1 : 48|1@1+ (1,0) [0|0] ""  Receiver
 SG_ VCFRONT_LVLoadRequest : 47|1@1+ (1,0) [0|0] ""  Receiver
 SG_ VCFRONT_good12VforUpdate : 46|1@1+ (1,0) [0|0] ""  Receiver
 SG_ VCFRONT_firstChargePOR m0 : 45|1@1+ (1,0) [0|0] ""  Receiver
 SG_ VCFRONT_chargeNeeded m1 : 45|1@1+ (1,0) [0|0] ""  Receiver
 SG_ VCFRONT_firstChargeOTA m0 : 44|1@1+ (1,0) [0|0] ""  Receiver
 SG_ VCFRONT_PCSMia m1 : 44|1@1+ (1,0) [0|0] ""  Receiver
 SG_ VCFRONT_silentWakeIBSCurrent m0 : 32|12@1- (0.1,-204.7) [-409.5|2.8421709430404E-014] "mA"  Receiver
 SG_ v12vBattVoltage261 m1 : 32|12@1+ (0.00544368,0) [0|22.2918696] "V"  Receiver
 SG_ VCFRONT_12VBatteryTargetVoltage m2 : 32|10@1+ (0.01,9) [9|19.23] "V"  Receiver
 SG_ v12vBattCurrent261 m0 : 16|16@1- (0.005,0) [-163.84|163.835] "A"  Receiver
 SG_ VCFRONT_IBSCurrent m1 : 16|16@1- (0.005,0) [-163.84|163.835] "A"  Receiver
 SG_ v12vBattTemp261 m2 : 16|16@1- (0.01,0) [-327.68|327.67] "C"  Receiver
 SG_ VCFRONT_shortedCellFaultCounter m0 : 13|3@1+ (1,0) [0|0] ""  Receiver
 SG_ VCFRONT_isVehicleSupported m0 : 12|1@1+ (1,0) [0|0] ""  Receiver
 SG_ VCFRONT_targetCurrent m1 : 8|8@1+ (0.125,0) [0|31.875] "A"  Receiver
 SG_ VCFRONT_voltageDropCounter m0 : 8|4@1+ (1,0) [0|0] ""  Receiver
 SG_ VCFRONT_batterySMState m1 : 4|4@1+ (1,0) [0|0] ""  Receiver
 SG_ VCFRONT_12VOverchargeCounter m0 : 4|4@1+ (1,0) [0|0] ""  Receiver
 SG_ VCFRONT_batterySupportRequest m1 : 3|1@1+ (1,0) [0|0] ""  Receiver
 SG_ v12vBattAH261 m2 : 2|14@1- (0.005,0) [-40.96|40.955] "Ah"  Receiver
 SG_ VCFRONT_voltageProfile m0 : 2|2@1+ (1,0) [0|0] ""  Receiver
 SG_ VCFRONT_IBSFault m1 : 2|1@1+ (1,0) [0|0] ""  Receiver
 SG_ VCFRONT_12VBatteryStatusIndex M : 0|2@1+ (1,0) [0|0] ""  Receiver

BO_ 610 VCLEFT_steeringColumnStatus: 6 VEH
 SG_ VCLEFT_steeringColumnInOutAmps : 38|6@1- (0.63,0) [0|0] "A" Vector__XXX
 SG_ VCLEFT_steeringColumnInOutCalib : 45|1@1+ (1,0) [0|0] "" Vector__XXX
 SG_ VCLEFT_steeringColumnInOutDuty : 11|5@1- (7,0) [0|0] "%" Vector__XXX
 SG_ VCLEFT_steeringColumnInOutPos : 24|8@1- (12,1284) [0|0] "ticks" Vector__XXX
 SG_ VCLEFT_steeringColumnLastRequest : 3|3@1+ (1,0) [0|0] "" Vector__XXX
 SG_ VCLEFT_steeringColumnSMState : 0|2@1+ (1,0) [0|0] "" Vector__XXX
 SG_ VCLEFT_steeringColumnUpDownAmps : 32|6@1- (0.63,0) [0|0] "A" Vector__XXX
 SG_ VCLEFT_steeringColumnUpDownCalib : 44|1@1+ (1,0) [0|0] "" Vector__XXX
 SG_ VCLEFT_steeringColumnUpDownDuty : 6|5@1- (7,0) [0|0] "%" Vector__XXX
 SG_ VCLEFT_steeringColumnUpDownPos : 16|8@1- (12,1284) [0|0] "ticks" Vector__XXX

BO_ 611 VCRIGHT_logging10Hz: 8 VEH
 SG_ VCRIGHT_logging10HzIndex M : 0|3@1+ (1,0) [0|4] ""  Receiver
 SG_ VCRIGHT_evapPulldownBias m3 : 8|8@1+ (0.4,0) [0|100] "%"  Receiver
 SG_ VCRIGHT_evapPulldownBiasActive m3 : 16|1@1+ (1,0) [0|1] ""  Receiver
 SG_ VCRIGHT_hvacCabinHumidityLevel m2 : 55|8@1+ (1,0) [0|100] "%"  Receiver
 SG_ VCRIGHT_hvacEstimateWindshieldRH m2 : 39|8@1+ (1,0) [0|150] "%"  Receiver
 SG_ VCRIGHT_hvacFilterLifeDetectActi m2 : 3|1@1+ (1,0) [0|1] ""  Receiver
 SG_ VCRIGHT_hvacFlashFoggingDetected m2 : 63|1@1+ (1,0) [0|1] ""  Receiver
 SG_ VCRIGHT_hvacFoggingRiskLevel m2 : 47|8@1+ (1,0) [0|100] "%"  Receiver
 SG_ VCRIGHT_hvacIntakeActuatorState m2 : 24|2@1+ (1,0) [0|2] ""  Receiver
 SG_ VCRIGHT_hvacIntakeOperationMode m2 : 10|1@1+ (1,0) [0|1] ""  Receiver
 SG_ VCRIGHT_hvacIntakePosition m1 : 56|8@1+ (0.4,0) [0|100] "%"  Receiver
 SG_ VCRIGHT_hvacIntakeTarget m0 : 56|8@1+ (0.4,0) [0|100] "%"  Receiver
 SG_ VCRIGHT_hvacLHBleedActuatorState m2 : 11|2@1+ (1,0) [0|2] ""  Receiver
 SG_ VCRIGHT_hvacLHBleedOperationMode m2 : 4|1@1+ (1,0) [0|1] ""  Receiver
 SG_ VCRIGHT_hvacLHBleedPosition m1 : 8|8@1+ (0.4,0) [0|100] "%"  Receiver
 SG_ VCRIGHT_hvacLHBleedTarget m0 : 8|8@1+ (0.4,0) [0|100] "%"  Receiver
 SG_ VCRIGHT_hvacLHVaneActuatorState m2 : 16|2@1+ (1,0) [0|2] ""  Receiver
 SG_ VCRIGHT_hvacLHVaneOperationMode m2 : 6|1@1+ (1,0) [0|1] ""  Receiver
 SG_ VCRIGHT_hvacLHVanePosition m1 : 24|8@1+ (0.4,0) [0|100] "%"  Receiver
 SG_ VCRIGHT_hvacLHVaneTarget m0 : 24|8@1+ (0.4,0) [0|100] "%"  Receiver
 SG_ VCRIGHT_hvacLowerModeActState m2 : 22|2@1+ (1,0) [0|2] ""  Receiver
 SG_ VCRIGHT_hvacLowerModeOpMode m2 : 9|1@1+ (1,0) [0|1] ""  Receiver
 SG_ VCRIGHT_hvacLowerModePosition m1 : 48|8@1+ (0.4,0) [0|100] "%"  Receiver
 SG_ VCRIGHT_hvacLowerModeTarget m0 : 48|8@1+ (0.4,0) [0|100] "%"  Receiver
 SG_ VCRIGHT_hvacRHBleedActuatorState m2 : 13|2@1+ (1,0) [0|2] ""  Receiver
 SG_ VCRIGHT_hvacRHBleedOperationMode m2 : 5|1@1+ (1,0) [0|1] ""  Receiver
 SG_ VCRIGHT_hvacRHBleedPosition m1 : 16|8@1+ (0.4,0) [0|100] "%"  Receiver
 SG_ VCRIGHT_hvacRHBleedTarget m0 : 16|8@1+ (0.4,0) [0|100] "%"  Receiver
 SG_ VCRIGHT_hvacRHVaneActuatorState m2 : 18|2@1+ (1,0) [0|2] ""  Receiver
 SG_ VCRIGHT_hvacRHVaneOperationMode m2 : 7|1@1+ (1,0) [0|1] ""  Receiver
 SG_ VCRIGHT_hvacRHVanePosition m1 : 32|8@1+ (0.4,0) [0|100] "%"  Receiver
 SG_ VCRIGHT_hvacRHVaneTarget m0 : 32|8@1+ (0.4,0) [0|100] "%"  Receiver
 SG_ VCRIGHT_hvacUpperModeActState m2 : 20|2@1+ (1,0) [0|2] ""  Receiver
 SG_ VCRIGHT_hvacUpperModeOpMode m2 : 8|1@1+ (1,0) [0|1] ""  Receiver
 SG_ VCRIGHT_hvacUpperModePosition m1 : 40|8@1+ (0.4,0) [0|100] "%"  Receiver
 SG_ VCRIGHT_timeLeftToCabinModelInit m2 : 32|7@1+ (1,0) [0|127] ""  Receiver

BO_ 612 PCS_chgLineStatus: 6 VEH
 SG_ PCS_chgAcCurrentLimit : 32|10@1+ (0.1,0) [0|0] "A" Vector__XXX
 SG_ PCS_chgInputPower : 24|8@1+ (0.1,0) [0|0] "kW" Vector__XXX
 SG_ PCS_chgInputVoltage : 0|14@1+ (0.0333,0) [0|0] "V" Vector__XXX
 SG_ PCS_chgLineCurrent : 14|9@1+ (0.1,0) [0|0] "A" Vector__XXX

BO_ 614 DI_power: 8 VEH
 SG_ DI_elecPower : 0|11@1- (0.5,0) [0|0] "kW" Vector__XXX
 SG_ DI_dissipation : 16|8@1+ (125,0) [0|0] "W" Vector__XXX
 SG_ DI_heatPowerActual : 24|8@1+ (0.08,0) [0|0] "kW" Vector__XXX
 SG_ DI_heatPowerOptimal : 32|8@1+ (0.08,0) [0|0] "kW" Vector__XXX
 SG_ DI_RearExcessHeatCmd : 40|8@1+ (0.08,0) [0|20] "kW"   X
 SG_ DI_heatPowerMax : 48|8@1+ (0.08,0) [0|0] "kW" Vector__XXX

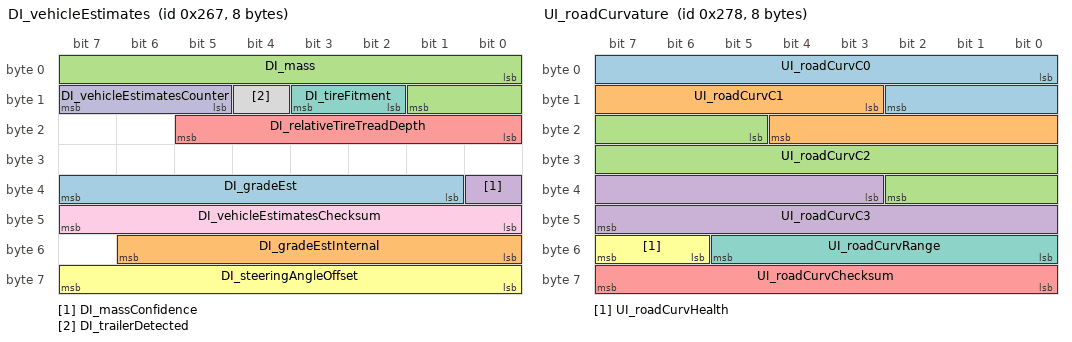
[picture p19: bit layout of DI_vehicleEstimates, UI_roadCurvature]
BO_ 615 DI_vehicleEstimates: 8 VEH
 SG_ DI_gradeEst : 33|7@1- (1,0) [-40|40] "%"  Receiver
 SG_ DI_gradeEstInternal : 48|7@1- (1,0) [-40|40] "%"  Receiver
 SG_ DI_mass : 0|10@1+ (5,1900) [1900|7010] "kg"  Receiver
 SG_ DI_massConfidence : 32|1@1+ (1,0) [0|1] ""  Receiver
 SG_ DI_relativeTireTreadDepth : 16|6@1- (0.2,0) [-6.2|6.2] "mm"  Receiver
 SG_ DI_steeringAngleOffset : 56|8@1- (0.2,0) [-25.6|25.4] "Deg"  Receiver
 SG_ DI_tireFitment : 10|2@1+ (1,0) [0|3] ""  Receiver
 SG_ DI_trailerDetected : 12|1@1+ (1,0) [0|1] ""  Receiver
 SG_ DI_vehicleEstimatesChecksum : 40|8@1+ (1,0) [0|255] ""  Receiver
 SG_ DI_vehicleEstimatesCounter : 13|3@1+ (1,0) [0|7] ""  Receiver

BO_ 616 DI_systemPower: 5 VEH
 SG_ DI_sysDrivePowerMax : 16|9@1+ (1,0) [0|0] "kW" Vector__XXX
 SG_ DI_sysHeatPowerActual : 8|8@1+ (0.08,0) [0|0] "kW" Vector__XXX
 SG_ DI_sysHeatPowerMax : 0|8@1+ (0.08,0) [0|0] "kW" Vector__XXX
 SG_ DI_sysRegenPowerMax : 32|8@1+ (1,-100) [0|0] "kW" Vector__XXX
 SG_ DI_primaryUnitSiliconType : 26|1@1+ (1,0) [0|1] ""  Receiver

BO_ 617 ID269LeftRearPower: 8 VehicleBus
 SG_ LeftRearHeatPowerOptimal : 16|8@1+ (0.08,0) [0|20.4] "kW"  Receiver
 SG_ LeftRearPower : 0|11@1- (0.5,0) [-512|511.5] "kW"  Receiver
 SG_ LeftRearPowerMax : 24|8@1+ (0.08,0) [0|20.4] "kW"  Receiver
 SG_ LeftRearPowerLimit : 48|9@1+ (1,0) [0|400] "kW"  Receiver
 SG_ LeftRearHeatPower : 32|8@1+ (0.08,0) [0|20.4] "kW"  Receiver
 SG_ LeftRearExcessHeatCmd : 40|8@1+ (0.08,0) [0|20] "kW"  Receiver

BO_ 626 VCLEFT_epbmDebug: 8 VEH
 SG_ VCLEFT_epbmDebugIndex M : 0|1@1+ (1,0) [0|0] "" Vector__XXX
 SG_ VCLEFT_epbmCaliperState m0 : 1|3@1+ (1,0) [0|0] "" Vector__XXX
 SG_ VCLEFT_epbmMotorEnabled m0 : 4|1@1+ (1,0) [0|0] "" Vector__XXX
 SG_ VCLEFT_epbMotorCurrent m0 : 5|11@1+ (0.01,0) [0|0] "A" Vector__XXX
 SG_ VCLEFT_epbmApplyVoltage m0 : 16|11@1+ (0.01,0) [0|0] "A" Vector__XXX
 SG_ VCLEFT_epbmReleaseVoltage m0 : 27|11@1+ (0.01,0) [0|0] "A" Vector__XXX
 SG_ VCLEFT_summonFaultReason m0 : 38|5@1+ (1,0) [0|0] "" Vector__XXX
 SG_ VCLEFT_epbSummonState m0 : 43|3@1+ (1,0) [0|0] "" Vector__XXX
 SG_ VCLEFT_epbmSummonState m0 : 46|3@1+ (1,0) [0|0] "" Vector__XXX
 SG_ VCLEFT_epbmUnitStatus m0 : 49|5@1+ (1,0) [0|0] "" Vector__XXX
 SG_ VCLEFT_epbUnitStatus m0 : 54|5@1+ (1,0) [0|0] "" Vector__XXX
 SG_ VCLEFT_epbmFaultStatus m0 : 59|2@1+ (1,0) [0|0] "" Vector__XXX
 SG_ VCLEFT_epbFaultStatus m0 : 61|2@1+ (1,0) [0|0] "" Vector__XXX
 SG_ VCLEFT_epbmOpenAllowed m1 : 1|1@1+ (1,0) [0|0] "" Vector__XXX
 SG_ VCLEFT_epbmDynamicAllowed m1 : 2|1@1+ (1,0) [0|0] "" Vector__XXX
 SG_ VCLEFT_epbmParkAllowed m1 : 3|1@1+ (1,0) [0|0] "" Vector__XXX
 SG_ VCLEFT_epbmStartAllowed m1 : 4|1@1+ (1,0) [0|0] "" Vector__XXX
 SG_ VCLEFT_epbmServiceAllowed m1 : 5|1@1+ (1,0) [0|0] "" Vector__XXX
 SG_ VCLEFT_epbmWinchAllowed m1 : 6|1@1+ (1,0) [0|0] "" Vector__XXX
 SG_ VCLEFT_epbmWinchReleaseAllowed m1 : 7|1@1+ (1,0) [0|0] "" Vector__XXX
 SG_ VCLEFT_epbmParkingAllowed m1 : 8|1@1+ (1,0) [0|0] "" Vector__XXX
 SG_ VCLEFT_epbmDynApplyingAllowed m1 : 9|1@1+ (1,0) [0|0] "" Vector__XXX
 SG_ VCLEFT_epbmReleasingAllowed m1 : 10|1@1+ (1,0) [0|0] "" Vector__XXX
 SG_ VCLEFT_epbmFaultAllowed m1 : 11|1@1+ (1,0) [0|0] "" Vector__XXX
 SG_ VCLEFT_epbmSummonAllowed m1 : 12|1@1+ (1,0) [0|0] "" Vector__XXX
 SG_ VCLEFT_epbmSummonParkAllowed m1 : 13|1@1+ (1,0) [0|0] "" Vector__XXX
 SG_ VCLEFT_epbmSummonReleaseAllowed m1 : 14|1@1+ (1,0) [0|0] "" Vector__XXX
 SG_ VCLEFT_summonInitAllowed m1 : 15|1@1+ (1,0) [0|0] "" Vector__XXX
 SG_ VCLEFT_epbmUnknownAllowed m1 : 16|1@1+ (1,0) [0|0] "" Vector__XXX
 SG_ VCLEFT_summonIdleAllowed m1 : 17|1@1+ (1,0) [0|0] "" Vector__XXX
 SG_ VCLEFT_summonArmedAllowed m1 : 18|1@1+ (1,0) [0|0] "" Vector__XXX
 SG_ VCLEFT_summonActiveAllowed m1 : 19|1@1+ (1,0) [0|0] "" Vector__XXX
 SG_ VCLEFT_summonCompleteAllowed m1 : 20|1@1+ (1,0) [0|0] "" Vector__XXX
 SG_ VCLEFT_summonFaultAllowed m1 : 21|1@1+ (1,0) [0|0] "" Vector__XXX
 SG_ VCLEFT_summonUnavailableAllowed m1 : 22|1@1+ (1,0) [0|0] "" Vector__XXX
 SG_ VCLEFT_cdpEnumDummy m1 : 24|2@1+ (1,0) [0|0] "" Vector__XXX

BO_ 627 UI_vehicleControl: 8 VEH
 SG_ UI_accessoryPowerRequest : 0|1@1+ (1,0) [0|0] "" Vector__XXX
 SG_ UI_alarmEnabled : 20|1@1+ (1,0) [0|0] "" Vector__XXX
 SG_ UI_ambientLightingEnabled : 40|1@1+ (1,0) [0|0] "" Vector__XXX
 SG_ UI_autoFoldMirrorsOn : 52|1@1+ (1,0) [0|0] "" Vector__XXX
 SG_ UI_autoHighBeamEnabled : 41|1@1+ (1,0) [0|0] "" Vector__XXX
 SG_ UI_childDoorLockOn : 16|1@1+ (1,0) [0|0] "" Vector__XXX
 SG_ UI_displayBrightnessLevel : 32|8@1+ (0.5,0) [0|0] "%" Vector__XXX
 SG_ UI_domeLightSwitch : 59|2@1+ (1,0) [0|0] "" Vector__XXX
 SG_ UI_driveStateRequest : 62|1@1+ (1,0) [0|0] "" Vector__XXX
 SG_ UI_frontFogSwitch : 3|1@1+ (1,0) [0|0] "" Vector__XXX
 SG_ UI_frontLeftSeatHeatReq : 42|2@1+ (1,0) [0|0] "" Vector__XXX
 SG_ UI_frontRightSeatHeatReq : 44|2@1+ (1,0) [0|0] "" Vector__XXX
 SG_ UI_frunkRequest : 5|1@1+ (1,0) [0|0] "" Vector__XXX
 SG_ UI_globalUnlockOn : 15|1@1+ (1,0) [0|0] "" Vector__XXX
 SG_ UI_honkHorn : 61|1@1+ (1,0) [0|0] "" Vector__XXX
 SG_ UI_intrusionSensorOn : 21|1@1+ (1,0) [0|0] "" Vector__XXX
 SG_ UI_lightSwitch : 1|2@1+ (1,0) [0|0] "" Vector__XXX
 SG_ UI_lockRequest : 17|3@1+ (1,0) [0|0] "" Vector__XXX
 SG_ UI_mirrorDipOnReverse : 53|1@1+ (1,0) [0|0] "" Vector__XXX
 SG_ UI_mirrorFoldRequest : 24|2@1+ (1,0) [0|0] "" Vector__XXX
 SG_ UI_mirrorHeatRequest : 26|1@1+ (1,0) [0|0] "" Vector__XXX
 SG_ UI_powerOff : 31|1@1+ (1,0) [0|0] "" Vector__XXX
 SG_ UI_rearCenterSeatHeatReq : 48|2@1+ (1,0) [0|0] "" Vector__XXX
 SG_ UI_rearFogSwitch : 23|1@1+ (1,0) [0|0] "" Vector__XXX
 SG_ UI_rearLeftSeatHeatReq : 46|2@1+ (1,0) [0|0] "" Vector__XXX
 SG_ UI_rearRightSeatHeatReq : 50|2@1+ (1,0) [0|0] "" Vector__XXX
 SG_ UI_rearWindowLockout : 63|1@1+ (1,0) [0|0] "" Vector__XXX
 SG_ UI_remoteClosureRequest : 54|2@1+ (1,0) [0|0] "" Vector__XXX
 SG_ UI_remoteStartRequest : 27|3@1+ (1,0) [0|0] "" Vector__XXX
 SG_ UI_seeYouHomeLightingOn : 30|1@1+ (1,0) [0|0] "" Vector__XXX
 SG_ UI_steeringBacklightEnabled : 8|1@1+ (1,0) [0|0] "" Vector__XXX
 SG_ UI_steeringButtonMode : 9|3@1+ (1,0) [0|0] "" Vector__XXX
 SG_ UI_stop12vSupport : 22|1@1+ (1,0) [0|0] "" Vector__XXX
 SG_ UI_summonActive : 4|1@1+ (1,0) [0|0] "" Vector__XXX
 SG_ UI_unlockOnPark : 14|1@1+ (1,0) [0|0] "" Vector__XXX
 SG_ UI_walkAwayLock : 13|1@1+ (1,0) [0|0] "" Vector__XXX
 SG_ UI_walkUpUnlock : 12|1@1+ (1,0) [0|0] "" Vector__XXX
 SG_ UI_wiperMode : 6|2@1+ (1,0) [0|0] "" Vector__XXX
 SG_ UI_wiperRequest : 56|3@1+ (1,0) [0|0] "" Vector__XXX

BO_ 632 UI_roadCurvature: 8 VEH
 SG_ UI_roadCurvC0 : 0|11@1- (0.02,0) [0|0] "m" Vector__XXX
 SG_ UI_roadCurvC1 : 11|10@1- (0.00075,0) [0|0] "1" Vector__XXX
 SG_ UI_roadCurvC2 : 21|14@1- (7.5e-06,0) [0|0] "1/m" Vector__XXX
 SG_ UI_roadCurvC3 : 35|13@1- (3e-08,0) [0|0] "1/m2" Vector__XXX
 SG_ UI_roadCurvChecksum : 56|8@1+ (1,0) [0|0] "" Vector__XXX
 SG_ UI_roadCurvHealth : 54|2@1+ (1,0) [0|0] "" Vector__XXX
 SG_ UI_roadCurvRange : 48|6@1+ (4,0) [0|0] "m" Vector__XXX

BO_ 636 ID27CRightRearPower: 8 VehicleBus
 SG_ RightRearHeatPowerOptimal : 16|8@1+ (0.08,0) [0|20.4] "kW"  Receiver
 SG_ RightRearPower : 0|11@1- (0.5,0) [-512|511.5] "kW"  Receiver
 SG_ RightRearHeatPowerMax : 24|8@1+ (0.08,0) [0|20.4] "kW"  Receiver
 SG_ RightRearPowerLimit : 48|9@1+ (1,0) [0|400] "kW"  Receiver
 SG_ RightRearHeatPower : 32|8@1+ (0.08,0) [0|20.4] "kW"  Receiver
 SG_ RightRearExcessHeatCmd : 40|8@1+ (0.08,0) [0|20] "kW"  Receiver

BO_ 637 APS_eacMonitor: 3 VEH
 SG_ APS_eacAllow : 0|2@1+ (1,0) [0|0] "" Vector__XXX
 SG_ APS_eacMonitorChecksum : 16|8@1+ (1,0) [0|0] "" Vector__XXX
 SG_ APS_eacMonitorCounter : 8|4@1+ (1,0) [0|0] "" Vector__XXX

BO_ 641 VCFRONT_compressorRequest: 8 VEH
 SG_ VCFRONT_compressorTargetDuty : 0|16@1+ (0.1,0) [0|100] "%"  Receiver
 SG_ VCFRONT_compressorPowerLimit : 16|16@1+ (1,0) [0|65534] "W"  Receiver
 SG_ VCFRONT_compressorReset : 32|8@1+ (1,0) [0|255] ""  Receiver
 SG_ VCFRONT_compressorEnable : 40|1@1+ (1,0) [0|1] ""  Receiver

BO_ 642 ID282VCLEFT_hvacBlowerFeedback: 8 VehicleBus
 SG_ VCLEFT_blowerIndex M : 0|2@1+ (1,0) [0|1] ""  Receiver
 SG_ VCLEFT_hvacBlowerCBCCtrlState m1 : 58|3@1+ (1,0) [0|4] ""  Receiver
 SG_ VCLEFT_hvacBlowerCBCEstState m1 : 54|4@1+ (1,0) [0|14] ""  Receiver
 SG_ VCLEFT_hvacBlowerEnabled m0 : 2|1@1+ (1,0) [0|1] ""  Receiver
 SG_ VCLEFT_hvacBlowerFETTemp m0 : 44|7@1+ (1.5,-40) [-40|149] "C"  Receiver
 SG_ VCLEFT_hvacBlowerFault m0 : 59|1@1+ (1,0) [0|1] ""  Receiver
 SG_ VCLEFT_hvacBlowerIPhase0 m1 : 10|8@1+ (0.2,0) [0|50] "A"  Receiver
 SG_ VCLEFT_hvacBlowerIPhase1 m1 : 18|8@1+ (0.2,0) [0|50] "A"  Receiver
 SG_ VCLEFT_hvacBlowerIPhase2 m1 : 26|8@1+ (0.2,0) [0|50] "A"  Receiver
 SG_ VCLEFT_hvacBlowerITerm m0 : 51|7@1+ (0.05,-1.5) [-1.5|4.5] "Nm"  Receiver
 SG_ VCLEFT_hvacBlowerInitd m0 : 58|1@1+ (1,0) [0|1] ""  Receiver
 SG_ VCLEFT_hvacBlowerLimitFETTemps m0 : 60|1@1+ (1,0) [0|1] ""  Receiver
 SG_ VCLEFT_hvacBlowerOutputDuty m0 : 3|7@1+ (1,0) [0|100] "%"  Receiver
 SG_ VCLEFT_hvacBlowerPowerOn m0 : 61|1@1+ (1,0) [0|1] ""  Receiver
 SG_ VCLEFT_hvacBlowerRPMActual m0 : 20|10@1+ (10,0) [0|10000] "rpm"  Receiver
 SG_ VCLEFT_hvacBlowerRPMTarget m0 : 10|10@1+ (10,0) [0|10000] "rpm"  Receiver
 SG_ VCLEFT_hvacBlowerRs m1 : 2|8@1+ (0.25,0) [0|60] "mOhm"  Receiver
 SG_ VCLEFT_hvacBlowerRsOnlineActive m1 : 61|1@1+ (1,0) [0|1] ""  Receiver
 SG_ VCLEFT_hvacBlowerSpiError m0 : 62|1@1+ (1,0) [0|1] ""  Receiver
 SG_ VCLEFT_hvacBlowerTorque m0 : 34|10@1+ (0.006,-1.5) [-1.5|4.5] "Nm"  Receiver
 SG_ VCLEFT_hvacBlower_IO_CBC_HEAD m1 : 34|4@1+ (1,0) [0|15] ""  Receiver
 SG_ VCLEFT_hvacBlower_IO_CBC_Status m1 : 43|1@1+ (1,0) [0|1] ""  Receiver
 SG_ VCLEFT_hvacBlower_IO_CBC_TAIL m1 : 38|4@1+ (1,0) [0|15] ""  Receiver
 SG_ VCLEFT_hvacBlower_IO_CBC_TAIL_va m1 : 42|1@1+ (1,0) [0|1] ""  Receiver
 SG_ VCLEFT_hvacBlower_IO_CBC_numUart m1 : 46|8@1+ (1,0) [0|255] ""  Receiver

BO_ 644 UI_vehicleModes: 4 VEH
 SG_ UI_factoryMode : 0|1@1+ (1,0) [0|0] "" Vector__XXX
 SG_ UI_homelinkV2Command0 : 8|8@1+ (1,0) [0|0] "" Vector__XXX
 SG_ UI_homelinkV2Command1 : 16|8@1+ (1,0) [0|0] "" Vector__XXX
 SG_ UI_homelinkV2Command2 : 24|8@1+ (1,0) [0|0] "" Vector__XXX
 SG_ UI_serviceMode : 3|1@1+ (1,0) [0|0] "" Vector__XXX
 SG_ UI_showroomMode : 2|1@1+ (1,0) [0|0] "" Vector__XXX
 SG_ UI_transportMode : 1|1@1+ (1,0) [0|0] "" Vector__XXX
 SG_ UI_gameMode : 34|1@1+ (1,0) [0|0] ""  Receiver
 SG_ UI_isDelivered : 4|1@1+ (1,0) [0|0] ""  Receiver
 SG_ UI_carWashModeRequest : 32|1@1+ (1,0) [0|0] ""  Receiver
 SG_ UI_valetMode : 33|1@1+ (1,0) [0|0] ""  Receiver
 SG_ UI_sentryMode : 5|1@1+ (1,0) [0|0] ""  Receiver

BO_ 645 UI_driverProfileRecall: 8 VEH
 SG_ UI_driverProfileRecallIndex M : 0|3@1+ (1,0) [0|0] "" Vector__XXX
 SG_ UI_driverProfileRecallStop : 3|1@1+ (1,0) [0|0] "" Vector__XXX
 SG_ UI_frontSeatRecallActive m1 : 4|1@1+ (1,0) [0|0] "" Vector__XXX
 SG_ UI_frontSeatTrackPos m1 : 5|10@1- (4,0) [0|0] "mm" Vector__XXX
 SG_ UI_frontSeatBackPos m1 : 16|12@1- (0.1,0) [0|0] "deg" Vector__XXX
 SG_ UI_frontSeatLiftPos m1 : 32|10@1- (4,0) [0|0] "mm" Vector__XXX
 SG_ UI_frontSeatTiltPos m1 : 48|12@1- (0.1,0) [0|0] "deg" Vector__XXX
 SG_ UI_columnAndLumbarRecallActive m2 : 4|1@1+ (1,0) [0|0] "" Vector__XXX
 SG_ UI_steeringColumnUpDownPos m2 : 8|8@1- (12,1284) [0|0] "ticks" Vector__XXX
 SG_ UI_lumbarAPressureHpa m2 : 16|16@1+ (1,0) [0|0] "" Vector__XXX
 SG_ UI_lumbarBPressureHpa m2 : 32|16@1+ (1,0) [0|0] "" Vector__XXX
 SG_ UI_steeringColumnInOutPos m2 : 48|8@1- (12,1284) [0|0] "ticks" Vector__XXX
 SG_ UI_mirrorRecallActive m3 : 4|1@1+ (1,0) [0|0] "" Vector__XXX
 SG_ UI_leftMirrorTiltXPosition m3 : 8|8@1+ (0.02,0) [0|0] "V" Vector__XXX
 SG_ UI_leftMirrorTiltYPosition m3 : 16|8@1+ (0.02,0) [0|0] "V" Vector__XXX
 SG_ UI_rightMirrorTiltXPosition m3 : 24|8@1+ (0.02,0) [0|0] "V" Vector__XXX
 SG_ UI_rightMirrorTiltYPosition m3 : 32|8@1+ (0.02,0) [0|0] "V" Vector__XXX
 SG_ UI_leftMirrorDipXPosition m4 : 8|8@1+ (0.02,0) [0|0] "V" Vector__XXX
 SG_ UI_leftMirrorDipYPosition m4 : 16|8@1+ (0.02,0) [0|0] "V" Vector__XXX
 SG_ UI_rightMirrorDipXPosition m4 : 24|8@1+ (0.02,0) [0|0] "V" Vector__XXX
 SG_ UI_rightMirrorDipYPosition m4 : 32|8@1+ (0.02,0) [0|0] "V" Vector__XXX
 SG_ UI_leftBackrestSwitchUp m5 : 4|2@1+ (1,0) [0|0] "" Vector__XXX
 SG_ UI_leftBackrestSwitchDown m5 : 6|2@1+ (1,0) [0|0] "" Vector__XXX
 SG_ UI_leftLiftSwitchUp m5 : 8|2@1+ (1,0) [0|0] "" Vector__XXX
 SG_ UI_leftLiftSwitchDown m5 : 10|2@1+ (1,0) [0|0] "" Vector__XXX
 SG_ UI_rightBackrestSwitchUp m5 : 12|2@1+ (1,0) [0|0] "" Vector__XXX
 SG_ UI_rightBackrestSwitchDown m5 : 14|2@1+ (1,0) [0|0] "" Vector__XXX
 SG_ UI_rightLiftSwitchUp m5 : 16|2@1+ (1,0) [0|0] "" Vector__XXX
 SG_ UI_rightLiftSwitchDown m5 : 18|2@1+ (1,0) [0|0] "" Vector__XXX

BA_DEF_ BO_  "GenMsgSendType" ENUM  "Cyclic";
BA_DEF_ BO_  "GenMsgCycleTime" INT 0 10000;

BA_ "GenMsgSendType" BO_ 322 0;
BA_ "GenMsgCycleTime" BO_ 322 1000;
BA_ "GenMsgSendType" BO_ 600 0;
BA_ "GenMsgCycleTime" BO_ 600 100;
BA_ "GenMsgSendType" BO_ 601 0;
BA_ "GenMsgCycleTime" BO_ 601 100;
BA_ "GenMsgSendType" BO_ 637 0;
BA_ "GenMsgCycleTime" BO_ 637 100;
BA_ "GenMsgSendType" BO_ 306 0;
BA_ "GenMsgCycleTime" BO_ 306 10;
BA_ "GenMsgSendType" BO_ 594 0;
BA_ "GenMsgCycleTime" BO_ 594 100;
BA_ "GenMsgSendType" BO_ 530 0;
BA_ "GenMsgCycleTime" BO_ 530 100;
BA_ "GenMsgSendType" BO_ 541 0;
BA_ "GenMsgCycleTime" BO_ 541 100;
BA_ "GenMsgSendType" BO_ 583 0;
BA_ "GenMsgCycleTime" BO_ 583 100;
BA_ "GenMsgSendType" BO_ 569 0;
BA_ "GenMsgCycleTime" BO_ 569 100;
BA_ "GenMsgSendType" BO_ 586 0;
BA_ "GenMsgCycleTime" BO_ 586 100;
BA_ "GenMsgSendType" BO_ 392 0;
BA_ "GenMsgCycleTime" BO_ 392 10;
BA_ "GenMsgSendType" BO_ 390 0;
BA_ "GenMsgCycleTime" BO_ 390 10;
BA_ "GenMsgSendType" BO_ 614 0;
BA_ "GenMsgCycleTime" BO_ 614 10;
BA_ "GenMsgSendType" BO_ 599 0;
BA_ "GenMsgCycleTime" BO_ 599 20;
BA_ "GenMsgSendType" BO_ 616 0;
BA_ "GenMsgCycleTime" BO_ 616 100;
BA_ "GenMsgSendType" BO_ 280 0;
BA_ "GenMsgCycleTime" BO_ 280 10;
BA_ "GenMsgSendType" BO_ 264 0;
BA_ "GenMsgCycleTime" BO_ 264 10;
BA_ "GenMsgSendType" BO_ 552 0;
BA_ "GenMsgCycleTime" BO_ 552 100;
BA_ "GenMsgSendType" BO_ 325 0;
BA_ "GenMsgCycleTime" BO_ 325 20;
BA_ "GenMsgSendType" BO_ 580 0;
BA_ "GenMsgCycleTime" BO_ 580 100;
BA_ "GenMsgSendType" BO_ 532 0;
BA_ "GenMsgCycleTime" BO_ 532 100;
BA_ "GenMsgSendType" BO_ 533 0;
BA_ "GenMsgCycleTime" BO_ 533 1000;
BA_ "GenMsgSendType" BO_ 535 0;
BA_ "GenMsgCycleTime" BO_ 535 1000;
BA_ "GenMsgSendType" BO_ 274 0;
BA_ "GenMsgCycleTime" BO_ 274 1000;
BA_ "GenMsgSendType" BO_ 275 0;
BA_ "GenMsgCycleTime" BO_ 275 1000;
BA_ "GenMsgSendType" BO_ 276 0;
BA_ "GenMsgCycleTime" BO_ 276 1000;
BA_ "GenMsgSendType" BO_ 62 0;
BA_ "GenMsgCycleTime" BO_ 62 1000;
BA_ "GenMsgSendType" BO_ 281 0;
BA_ "GenMsgCycleTime" BO_ 281 2000;
BA_ "GenMsgSendType" BO_ 60 0;
BA_ "GenMsgCycleTime" BO_ 60 2000;
BA_ "GenMsgSendType" BO_ 522 0;
BA_ "GenMsgCycleTime" BO_ 522 10;
BA_ "GenMsgSendType" BO_ 606 0;
BA_ "GenMsgCycleTime" BO_ 606 100;
BA_ "GenMsgSendType" BO_ 542 0;
BA_ "GenMsgCycleTime" BO_ 542 40;
BA_ "GenMsgSendType" BO_ 590 0;
BA_ "GenMsgCycleTime" BO_ 590 100;
BA_ "GenMsgSendType" BO_ 526 0;
BA_ "GenMsgCycleTime" BO_ 526 40;
BA_ "GenMsgSendType" BO_ 558 0;
BA_ "GenMsgCycleTime" BO_ 558 40;
BA_ "GenMsgSendType" BO_ 612 0;
BA_ "GenMsgCycleTime" BO_ 612 100;
BA_ "GenMsgSendType" BO_ 516 0;
BA_ "GenMsgCycleTime" BO_ 516 100;
BA_ "GenMsgSendType" BO_ 548 0;
BA_ "GenMsgCycleTime" BO_ 548 100;
BA_ "GenMsgSendType" BO_ 17 0;
BA_ "GenMsgCycleTime" BO_ 17 10;
BA_ "GenMsgSendType" BO_ 257 0;
BA_ "GenMsgCycleTime" BO_ 257 20;
BA_ "GenMsgSendType" BO_ 273 0;
BA_ "GenMsgCycleTime" BO_ 273 1000;
BA_ "GenMsgSendType" BO_ 289 0;
BA_ "GenMsgCycleTime" BO_ 289 10;
BA_ "GenMsgSendType" BO_ 529 0;
BA_ "GenMsgCycleTime" BO_ 529 100;
BA_ "GenMsgSendType" BO_ 585 0;
BA_ "GenMsgCycleTime" BO_ 585 100;
BA_ "GenMsgSendType" BO_ 297 0;
BA_ "GenMsgCycleTime" BO_ 297 10;
BA_ "GenMsgSendType" BO_ 523 0;
BA_ "GenMsgCycleTime" BO_ 523 10;
BA_ "GenMsgSendType" BO_ 525 0;
BA_ "GenMsgCycleTime" BO_ 525 10;
BA_ "GenMsgSendType" BO_ 291 0;
BA_ "GenMsgCycleTime" BO_ 291 1000;
BA_ "GenMsgSendType" BO_ 531 0;
BA_ "GenMsgCycleTime" BO_ 531 500;
BA_ "GenMsgSendType" BO_ 568 0;
BA_ "GenMsgCycleTime" BO_ 568 500;
BA_ "GenMsgSendType" BO_ 536 0;
BA_ "GenMsgCycleTime" BO_ 536 500;
BA_ "GenMsgSendType" BO_ 645 0;
BA_ "GenMsgCycleTime" BO_ 645 500;
BA_ "GenMsgSendType" BO_ 79 0;
BA_ "GenMsgCycleTime" BO_ 79 1000;
BA_ "GenMsgSendType" BO_ 499 0;
BA_ "GenMsgCycleTime" BO_ 499 1000;
BA_ "GenMsgSendType" BO_ 435 0;
BA_ "GenMsgCycleTime" BO_ 435 1000;
BA_ "GenMsgSendType" BO_ 371 0;
BA_ "GenMsgCycleTime" BO_ 371 1000;
BA_ "GenMsgSendType" BO_ 307 0;
BA_ "GenMsgCycleTime" BO_ 307 1000;
BA_ "GenMsgSendType" BO_ 632 0;
BA_ "GenMsgCycleTime" BO_ 632 500;
BA_ "GenMsgSendType" BO_ 627 0;
BA_ "GenMsgCycleTime" BO_ 627 500;
BA_ "GenMsgSendType" BO_ 644 0;
BA_ "GenMsgCycleTime" BO_ 644 500;
BA_ "GenMsgSendType" BO_ 595 0;
BA_ "GenMsgCycleTime" BO_ 595 500;
BA_ "GenMsgSendType" BO_ 609 0;
BA_ "GenMsgCycleTime" BO_ 609 100;
BA_ "GenMsgSendType" BO_ 545 0;
BA_ "GenMsgCycleTime" BO_ 545 50;
BA_ "GenMsgSendType" BO_ 577 0;
BA_ "GenMsgCycleTime" BO_ 577 100;
BA_ "GenMsgSendType" BO_ 258 0;
BA_ "GenMsgCycleTime" BO_ 258 100;
BA_ "GenMsgSendType" BO_ 626 0;
BA_ "GenMsgCycleTime" BO_ 626 50;
BA_ "GenMsgSendType" BO_ 642 0;
BA_ "GenMsgCycleTime" BO_ 642 50;
BA_ "GenMsgSendType" BO_ 610 0;
BA_ "GenMsgCycleTime" BO_ 610 100;
BA_ "GenMsgSendType" BO_ 259 0;
BA_ "GenMsgCycleTime" BO_ 259 100;
BA_ "GenMsgSendType" BO_ 579 0;
BA_ "GenMsgCycleTime" BO_ 579 100;
BA_ "GenMsgSendType" BO_ 524 0;
BA_ "GenMsgCycleTime" BO_ 524 100;
BA_ "GenMsgSendType" BO_ 611 0;
BA_ "GenMsgCycleTime" BO_ 611 20;
BA_ "GenMsgSendType" BO_ 505 0;
BA_ "GenMsgCycleTime" BO_ 505 100;

VAL_ 12 UI_autopilotTrial 3 "ACTIVE" 0 "NONE" 1 "START" 2 "STOP" ;
VAL_ 12 UI_autopilotTrial 3 "ACTIVE" 0 "NONE" 1 "START" 2 "STOP" ;
VAL_ 12 UI_cellNetworkTechnology 9 "CELL_NETWORK_CDMA" 2 "CELL_NETWORK_EDGE" 1 "CELL_NETWORK_GPRS" 8 "CELL_NETWORK_GSM" 4 "CELL_NETWORK_HSDPA" 6 "CELL_NETWORK_HSPA" 5 "CELL_NETWORK_HSUPA" 7 "CELL_NETWORK_LTE" 0 "CELL_NETWORK_NONE" 15 "CELL_NETWORK_SNA" 3 "CELL_NETWORK_UMTS" 10 "CELL_NETWORK_WCDMA" ;
VAL_ 12 UI_cellSignalBars 5 "FIVE" 4 "FOUR" 1 "ONE" 7 "SNA" 3 "THREE" 2 "TWO" 0 "ZERO" ;
VAL_ 12 UI_factoryReset 3 "CUSTOMER" 1 "DEVELOPER" 2 "DIAGNOSTIC" 0 "NONE_SNA" ;
VAL_ 17 RCM_collisionFront 0 "INACTIVE" 1 "ACTIVE" 3 "SNA" ;
VAL_ 17 RCM_collisionLeft 0 "INACTIVE" 1 "ACTIVE" 3 "SNA" ;
VAL_ 17 RCM_collisionRear 0 "INACTIVE" 1 "ACTIVE" 3 "SNA" ;
VAL_ 17 RCM_collisionRight 0 "INACTIVE" 1 "ACTIVE" 3 "SNA" ;
VAL_ 17 RCM_collisionRollover 0 "INACTIVE" 1 "ACTIVE" 3 "SNA" ;
VAL_ 17 RCM_collisionSeverity 0 "PRETENSIONER" 1 "FIRST_STAGE" 2 "SECOND_STAGE" 3 "PEDPRO_EVENT" ;
VAL_ 60 GTW_infoIndex 0 "DEPRECATED_0" 1 "DEPRECATED_1" 2 "DEPRECATED_2" 3 "DEPRECATED_3" 4 "DEPRECATED_4" 5 "DEPRECATED_5" 6 "DEPRECATED_6" 7 "DEPRECATED_7" 8 "DEPRECATED_8" 9 "DEPRECATED_9" 10 "BUILD_HWID_COMPONENTID" 11 "PCBAID_ASSYID_USAGEID" 13 "APP_CRC" 14 "BOOTLOADER_SVN" 15 "BOOTLOADER_CRC" 16 "SUBCOMPONENT" 17 "APP_GITHASH" 18 "BOOTLOADER_GITHASH" 19 "VERSION_DEPRECATED" 20 "UDS_PROTOCOL_BOOTCRC" 22 "VARIANTCRC" 25 "PACKAGE_PN_1_7" 26 "PACKAGE_PN_8_14" 27 "PACKAGE_PN_15_20" 29 "PACKAGE_SN_1_7" 30 "PACKAGE_SN_8_14" 31 "SUBCOMPONENT_GITHASH" 255 "END" ;
VAL_ 60 GTW_buildType 0 "UNKNOWN_BUILD" 1 "PLATFORM_BUILD" 2 "LOCAL_BUILD" 3 "TRACEABLE_CI_BUILD" 4 "MFG_BUILD" ;
VAL_ 60 GTW_platformType 0 "UNKNOWN" 3 "MODEL3" 255 "END" ;
VAL_ 62 GTW_matrixIndex 0 "AlertMatrix0" 1 "AlertMatrix1" ;
VAL_ 79 UI_gpsAccuracy 127 "SNA" ;
VAL_ 130 UI_energyAtDestination 32768 "SNA" 32767 "TRIP_TOO_LONG" ;
VAL_ 130 UI_energyAtDestination 32768 "SNA" 32767 "TRIP_TOO_LONG" ;
VAL_ 130 UI_hindsightEnergy 32768 "SNA" 32767 "TRIP_TOO_LONG" ;
VAL_ 130 UI_predictedEnergy 32768 "SNA" 32767 "TRIP_TOO_LONG" ;
VAL_ 257 RCM_pitchRate 16384 "SNA" ;
VAL_ 257 RCM_pitchRateQF 0 "INIT" 1 "VALID" 2 "TEMP_INVALID" 3 "FAULTED" ;
VAL_ 257 RCM_rollRate 16384 "SNA" ;
VAL_ 257 RCM_rollRateQF 0 "INIT" 1 "VALID" 2 "TEMP_INVALID" 3 "FAULTED" ;
VAL_ 257 RCM_yawRate 32768 "SNA" ;
VAL_ 257 RCM_yawRateQF 0 "FAULTED" 1 "NOT_FAULTED" ;
VAL_ 258 VCLEFT_frontLatchStatus 0 "SNA" 1 "OPENED" 2 "CLOSED" 3 "CLOSING" 4 "OPENING" 5 "AJAR" 6 "TIMEOUT" 7 "DEFAULT" 8 "FAULT" ;
VAL_ 258 VCLEFT_mirrorFoldState 0 "UNKNOWN" 1 "FOLDED" 2 "UNFOLDED" 3 "FOLDING" 4 "UNFOLDING" ;
VAL_ 258 VCLEFT_mirrorHeatState 0 "SNA" 1 "ON" 2 "OFF" 3 "OFF_UNAVAILABLE" 4 "FAULT" ;
VAL_ 258 VCLEFT_mirrorRecallState 0 "INIT" 1 "RECALLING_AXIS_1" 2 "RECALLING_AXIS_2" 3 "RECALLING_COMPLETE" 4 "RECALLING_FAILED" 5 "RECALLING_STOPPED" ;
VAL_ 258 VCLEFT_mirrorState 0 "IDLE" 1 "TILT_X" 2 "TILT_Y" 3 "FOLD_UNFOLD" 4 "RECALL" ;
VAL_ 258 VCLEFT_rearLatchStatus 0 "SNA" 1 "OPENED" 2 "CLOSED" 3 "CLOSING" 4 "OPENING" 5 "AJAR" 6 "TIMEOUT" 7 "DEFAULT" 8 "FAULT" ;
VAL_ 259 VCRIGHT_frontLatchStatus 0 "SNA" 1 "OPENED" 2 "CLOSED" 3 "CLOSING" 4 "OPENING" 5 "AJAR" 6 "TIMEOUT" 7 "DEFAULT" 8 "FAULT" ;
VAL_ 259 VCRIGHT_mirrorFoldState 0 "UNKNOWN" 1 "FOLDED" 2 "UNFOLDED" 3 "FOLDING" 4 "UNFOLDING" ;
VAL_ 259 VCRIGHT_mirrorRecallState 0 "INIT" 1 "RECALLING_AXIS_1" 2 "RECALLING_AXIS_2" 3 "RECALLING_COMPLETE" 4 "RECALLING_FAILED" 5 "RECALLING_STOPPED" ;
VAL_ 259 VCRIGHT_mirrorState 0 "IDLE" 1 "TILT_X" 2 "TILT_Y" 3 "FOLD_UNFOLD" 4 "RECALL" ;
VAL_ 259 VCRIGHT_rearLatchStatus 0 "SNA" 1 "OPENED" 2 "CLOSED" 3 "CLOSING" 4 "OPENING" 5 "AJAR" 6 "TIMEOUT" 7 "DEFAULT" 8 "FAULT" ;
VAL_ 259 VCRIGHT_trunkLatchStatus 0 "SNA" 1 "OPENED" 2 "CLOSED" 3 "CLOSING" 4 "OPENING" 5 "AJAR" 6 "TIMEOUT" 7 "DEFAULT" 8 "FAULT" ;
VAL_ 264 DI_axleSpeed 32768 "SNA" ;
VAL_ 264 DI_torqueActual 4096 "SNA" ;
VAL_ 264 DI_torqueCommand 4096 "SNA" ;
VAL_ 264 DI_slavePedalPos 255 "SNA" ;
VAL_ 273 RCM_lateralAccel 32768 "SNA" ;
VAL_ 273 RCM_lateralAccelQF 0 "FAULTED" 1 "NOT_FAULTED" ;
VAL_ 273 RCM_longitudinalAccel 32768 "SNA" ;
VAL_ 273 RCM_longitudinalAccelQF 0 "FAULTED" 1 "NOT_FAULTED" ;
VAL_ 273 RCM_verticalAccel 32768 "SNA" ;
VAL_ 273 RCM_verticalAccelQF 0 "FAULTED" 1 "NOT_FAULTED" ;
VAL_ 274 GTW_1V1_VEH 4095 "SNA" ;
VAL_ 274 GTW_1V5_VEH 4095 "SNA" ;
VAL_ 274 GTW_3V3_VEH 4095 "SNA" ;
VAL_ 274 GTW_3V3_SW 4095 "SNA" ;
VAL_ 274 GTW_5V0_SW 4095 "SNA" ;
VAL_ 275 GTW_bmpState 2 "BMP_STATE_ASLEEP" 3 "BMP_STATE_MIA" 0 "BMP_STATE_OFF" 1 "BMP_STATE_ON" 5 "BMP_STATE_POWER_CYCLE" 4 "BMP_STATE_RESET" 255 "DUMMY" ;
VAL_ 275 GTW_bmpState 2 "BMP_STATE_ASLEEP" 3 "BMP_STATE_MIA" 0 "BMP_STATE_OFF" 1 "BMP_STATE_ON" 5 "BMP_STATE_POWER_CYCLE" 4 "BMP_STATE_RESET" 255 "DUMMY" ;
VAL_ 275 GTW_12V0_DISP 16383 "SNA" ;
VAL_ 275 GTW_1V1_FPD 4095 "SNA" ;
VAL_ 275 GTW_1V8_GSM 4095 "SNA" ;
VAL_ 275 GTW_GSM_MDM_VNDR 4095 "SNA" ;
VAL_ 276 GTW_1V2_CSI 4095 "SNA" ;
VAL_ 276 GTW_1V8_VID 4095 "SNA" ;
VAL_ 276 GTW_1V8_VIO 4095 "SNA" ;
VAL_ 276 GTW_3V3_BMP 4095 "SNA" ;
VAL_ 276 GTW_GSM_BRD_REV 4095 "SNA" ;
VAL_ 280 DI_accelPedalPos 255 "SNA" ;
VAL_ 280 DI_brakePedalState 0 "OFF" 1 "ON" 2 "INVALID" ;
VAL_ 280 DI_epbRequest 0 "NO_REQUEST" 1 "PARK" 2 "UNPARK" ;
VAL_ 280 DI_gear 0 "INVALID" 1 "P" 2 "R" 3 "N" 4 "D" 7 "SNA" ;
VAL_ 280 DI_immobilizerState 0 "INIT_SNA" 1 "REQUEST" 2 "AUTHENTICATING" 3 "DISARMED" 4 "IDLE" 5 "RESET" 6 "FAULT" ;
VAL_ 280 DI_keepAliveRequest 0 "NO_REQUEST" 1 "KEEP_ALIVE" ;
VAL_ 280 DI_systemState 0 "UNAVAILABLE" 1 "IDLE" 2 "STANDBY" 3 "FAULT" 4 "ABORT" 5 "ENABLE" ;
VAL_ 280 DI_trackModeState 0 "UNAVAILABLE" 1 "AVAILABLE" 2 "ON" ;
VAL_ 280 DI_tractionControlMode 0 "NORMAL" 1 "SLIP_START" 2 "DEV_MODE_1" 3 "DEV_MODE_2" 4 "ROLLS_MODE" 5 "DYNO_MODE" ;
VAL_ 281 VCSEC_windowRequestPercent 127 "SNA" ;
VAL_ 281 VCSEC_windowRequestPercent 127 "SNA" ;
VAL_ 281 VCSEC_windowRequestType 3 "WINDOW_REQUEST_GOTO_CLOSED" 2 "WINDOW_REQUEST_GOTO_CRACKED" 1 "WINDOW_REQUEST_GOTO_PERCENT" 0 "WINDOW_REQUEST_IDLE" ;
VAL_ 289 RCM_crashAlgoWakeup 0 "INACTIVE" 1 "ACTIVE" 3 "SNA" ;
VAL_ 289 RCM_nearDeployFront 0 "INACTIVE" 1 "ACTIVE" 3 "SNA" ;
VAL_ 289 RCM_nearDeployLeft 0 "INACTIVE" 1 "ACTIVE" 3 "SNA" ;
VAL_ 289 RCM_nearDeployRear 0 "INACTIVE" 1 "ACTIVE" 3 "SNA" ;
VAL_ 289 RCM_nearDeployRight 0 "INACTIVE" 1 "ACTIVE" 3 "SNA" ;
VAL_ 289 RCM_nearDeployRollover 0 "INACTIVE" 1 "ACTIVE" 3 "SNA" ;
VAL_ 290 VCLEFT_frontDoorState 1 "DOOR_STATE_CLOSED" 4 "DOOR_STATE_OPEN_OR_AJAR" 3 "DOOR_STATE_RELEASING_LATCH" 0 "DOOR_STATE_UNKNOWN" 2 "DOOR_STATE_WAIT_FOR_SHORT_DROP" ;
VAL_ 290 VCLEFT_frontHandleDebounceStatus 3 "EXTERIOR_HANDLE_STATUS_ACTIVE" 4 "EXTERIOR_HANDLE_STATUS_DISCONNECTED" 5 "EXTERIOR_HANDLE_STATUS_FAULT" 1 "EXTERIOR_HANDLE_STATUS_INDETERMINATE" 2 "EXTERIOR_HANDLE_STATUS_NOT_ACTIVE" 0 "EXTERIOR_HANDLE_STATUS_SNA" ;
VAL_ 290 VCLEFT_frontHandleRawStatus 3 "EXTERIOR_HANDLE_STATUS_ACTIVE" 4 "EXTERIOR_HANDLE_STATUS_DISCONNECTED" 5 "EXTERIOR_HANDLE_STATUS_FAULT" 1 "EXTERIOR_HANDLE_STATUS_INDETERMINATE" 2 "EXTERIOR_HANDLE_STATUS_NOT_ACTIVE" 0 "EXTERIOR_HANDLE_STATUS_SNA" ;
VAL_ 290 VCLEFT_rearDoorState 1 "DOOR_STATE_CLOSED" 4 "DOOR_STATE_OPEN_OR_AJAR" 3 "DOOR_STATE_RELEASING_LATCH" 0 "DOOR_STATE_UNKNOWN" 2 "DOOR_STATE_WAIT_FOR_SHORT_DROP" ;
VAL_ 290 VCLEFT_rearHandleDebounceStatus 3 "EXTERIOR_HANDLE_STATUS_ACTIVE" 4 "EXTERIOR_HANDLE_STATUS_DISCONNECTED" 5 "EXTERIOR_HANDLE_STATUS_FAULT" 1 "EXTERIOR_HANDLE_STATUS_INDETERMINATE" 2 "EXTERIOR_HANDLE_STATUS_NOT_ACTIVE" 0 "EXTERIOR_HANDLE_STATUS_SNA" ;
VAL_ 290 VCLEFT_rearHandleRawStatus 3 "EXTERIOR_HANDLE_STATUS_ACTIVE" 4 "EXTERIOR_HANDLE_STATUS_DISCONNECTED" 5 "EXTERIOR_HANDLE_STATUS_FAULT" 1 "EXTERIOR_HANDLE_STATUS_INDETERMINATE" 2 "EXTERIOR_HANDLE_STATUS_NOT_ACTIVE" 0 "EXTERIOR_HANDLE_STATUS_SNA" ;
VAL_ 294 DIR_vBatQF 0 "NOT_QUALIFIED" 1 "QUALIFIED" ;
VAL_ 297 SCCM_steeringAngleSensorStatus 0 "OK" 1 "INIT" 2 "ERROR" 3 "ERROR_INIT" ;
VAL_ 297 SCCM_steeringAngleValidity 0 "INVALID" 1 "VALID" 2 "INIT" 3 "SNA" ;
VAL_ 306 BMS_chgTimeToFull 4095 "BMS_chgTimeToFull_SNA" ;
VAL_ 306 BMS_currentUnfiltered 32768 "SNA" ;
VAL_ 306 BMS_packCurrent 32768 "SNA" ;
VAL_ 317 CP_chargeShutdownRequest 2 "EMERGENCY_SHUTDOWN_REQUESTED" 1 "GRACEFUL_SHUTDOWN_REQUESTED" 0 "NO_SHUTDOWN_REQUESTED" ;
VAL_ 317 CP_evseChargeType 2 "AC_CHARGER_PRESENT" 1 "DC_CHARGER_PRESENT" 0 "NO_CHARGER_PRESENT" ;
VAL_ 317 CP_hvChargeStatus 1 "CP_CHARGE_CONNECTED" 5 "CP_CHARGE_ENABLED" 6 "CP_CHARGE_FAULTED" 0 "CP_CHARGE_INACTIVE" 2 "CP_CHARGE_STANDBY" 4 "CP_EVSE_TEST_PASSED" 3 "CP_EXT_EVSE_TEST_ACTIVE" ;
VAL_ 322 VCLEFT_liftgateStatusIndex 0 "LIFTGATE_STATUS_INDEX_0" 1 "LIFTGATE_STATUS_INDEX_1" 2 "LIFTGATE_STATUS_INDEX_INVALID" ;
VAL_ 322 VCLEFT_liftgateLatchRequest 1 "LATCH_REQUEST_CINCH" 3 "LATCH_REQUEST_FORCE_RELEASE" 0 "LATCH_REQUEST_NONE" 2 "LATCH_REQUEST_RELEASE" 4 "LATCH_REQUEST_RESET" ;
VAL_ 322 VCLEFT_liftgateMvmntNotAllowedCo 4 "PLG_MVMT_NOT_ALLOWED_EXTERIOR_PRESS_AT_MAX_OPEN" 5 "PLG_MVMT_NOT_ALLOWED_LOCKED" 1 "PLG_MVMT_NOT_ALLOWED_LOW_12V" 0 "PLG_MVMT_NOT_ALLOWED_NONE" 3 "PLG_MVMT_NOT_ALLOWED_UNCALIBRATED" 2 "PLG_MVMT_NOT_ALLOWED_VEHICLE_AT_SPEED" ;
VAL_ 322 VCLEFT_liftgatePhysicalChimeRequ 0 "LIFTGATE_CHIME_REQUEST_NONE" 4 "LIFTGATE_CHIME_REQUEST_ONE_LONG" 1 "LIFTGATE_CHIME_REQUEST_ONE_SHORT" 3 "LIFTGATE_CHIME_REQUEST_THREE_SHORT" 2 "LIFTGATE_CHIME_REQUEST_TWO_SHORT" ;
VAL_ 322 VCLEFT_liftgateRequestSource 5 "PLG_REQUEST_SOURCE_CLOSE_ALL" 2 "PLG_REQUEST_SOURCE_EXTERIOR" 4 "PLG_REQUEST_SOURCE_KEY_TRUNK_BUTTON" 6 "PLG_REQUEST_SOURCE_MCU_CLOSE" 1 "PLG_REQUEST_SOURCE_MCU_SWITCH" 0 "PLG_REQUEST_SOURCE_NONE" 3 "PLG_REQUEST_SOURCE_SHUTFACE" 7 "PLG_REQUEST_SOURCE_UDS" ;
VAL_ 322 VCLEFT_liftgateState 2 "PLG_STATE_BACKOFF" 5 "PLG_STATE_CLOSED" 4 "PLG_STATE_CLOSING" 11 "PLG_STATE_END_OF_TRAVEL" 0 "PLG_STATE_INIT" 7 "PLG_STATE_LATCH_CLOSING" 12 "PLG_STATE_LATCH_ENTRY" 10 "PLG_STATE_LATCH_EXIT" 6 "PLG_STATE_LATCH_OPENING" 8 "PLG_STATE_NOT_INSTALLED" 1 "PLG_STATE_OFF" 3 "PLG_STATE_OPENING" 9 "PLG_STATE_UNKNOWN" ;
VAL_ 322 VCLEFT_liftgateStoppingCondition 11 "PLG_STOPPING_CONDITION_COUNT" 10 "PLG_STOPPING_CONDITION_LATCH_FAULT" 3 "PLG_STOPPING_CONDITION_LOW_12V" 0 "PLG_STOPPING_CONDITION_NONE" 6 "PLG_STOPPING_CONDITION_OBSTACLE_CURRENT" 2 "PLG_STOPPING_CONDITION_OBSTACLE_STALL" 7 "PLG_STOPPING_CONDITION_OBSTACLE_TRAJ_POS" 8 "PLG_STOPPING_CONDITION_OBSTACLE_TRAJ_VEL" 1 "PLG_STOPPING_CONDITION_PINCH" 4 "PLG_STOPPING_CONDITION_STATE_TIMEOUT" 9 "PLG_STOPPING_CONDITION_UNCALIBRATED" 5 "PLG_STOPPING_CONDITION_VEHICLE_AT_SPEED" ;
VAL_ 322 VCLEFT_liftgateUIChimeRequest 0 "LIFTGATE_CHIME_REQUEST_NONE" 4 "LIFTGATE_CHIME_REQUEST_ONE_LONG" 1 "LIFTGATE_CHIME_REQUEST_ONE_SHORT" 3 "LIFTGATE_CHIME_REQUEST_THREE_SHORT" 2 "LIFTGATE_CHIME_REQUEST_TWO_SHORT" ;
VAL_ 325 ESP_absBrakeEvent2 0 "NOT_ACTIVE" 1 "ACTIVE_FRONT_REAR" 2 "ACTIVE_FRONT" 3 "ACTIVE_REAR" ;
VAL_ 325 ESP_absFaultLamp 0 "OFF" 1 "ON" ;
VAL_ 325 ESP_brakeApply 0 "INACTIVE" 1 "ACTIVE" ;
VAL_ 325 ESP_brakeDiscWipingActive 0 "INACTIVE" 1 "ACTIVE" ;
VAL_ 325 ESP_brakeLamp 0 "OFF" 1 "ON" ;
VAL_ 325 ESP_brakeTorqueTarget 8191 "SNA" ;
VAL_ 325 ESP_btcTargetState 0 "OFF" 1 "BACKUP" 2 "ON" 3 "SNA" ;
VAL_ 325 ESP_cdpStatus 0 "CDP_IS_NOT_AVAILABLE" 1 "CDP_IS_AVAILABLE" 2 "ACTUATING_EPB_CDP" 3 "CDP_COMMAND_INVALID" ;
VAL_ 325 ESP_driverBrakeApply 0 "NotInit_orOff" 1 "Not_Applied" 2 "Driver_applying_brakes" 3 "Faulty_SNA" ;
VAL_ 325 ESP_ebdFaultLamp 0 "OFF" 1 "ON" ;
VAL_ 325 ESP_ebrStandstillSkid 0 "NO_STANDSTILL_SKID" 1 "STANDSTILL_SKID_DETECTED" ;
VAL_ 325 ESP_ebrStatus 0 "EBR_IS_NOT_AVAILABLE" 1 "EBR_IS_AVAILABLE" 2 "ACTUATING_DI_EBR" 3 "EBR_COMMAND_INVALID" ;
VAL_ 325 ESP_espFaultLamp 0 "OFF" 1 "ON" ;
VAL_ 325 ESP_espLampFlash 0 "OFF" 1 "FLASH" ;
VAL_ 325 ESP_espModeActive 0 "00_NORMAL" 1 "01" 2 "02" 3 "03" ;
VAL_ 325 ESP_lateralAccelQF 0 "UNDEFINABLE_ACCURACY" 1 "IN_SPEC" ;
VAL_ 325 ESP_longitudinalAccelQF 0 "UNDEFINABLE_ACCURACY" 1 "IN_SPEC" ;
VAL_ 325 ESP_ptcTargetState 0 "FAULT" 1 "BACKUP" 2 "ON" 3 "SNA" ;
VAL_ 325 ESP_stabilityControlSts2 0 "INIT" 1 "ON" 2 "ENGAGED" 3 "FAULTED" ;
VAL_ 325 ESP_steeringAngleQF 0 "UNDEFINABLE_ACCURACY" 1 "IN_SPEC" ;
VAL_ 325 ESP_yawRateQF 0 "UNDEFINABLE_ACCURACY" 1 "IN_SPEC" ;
VAL_ 341 ESP_wheelRotationRR 3 "UNKNOWN" 2 "STANDSTILL" 1 "BACKWARD" 0 "FORWARD" ;
VAL_ 341 ESP_wheelRotationRL 3 "UNKNOWN" 2 "STANDSTILL" 1 "BACKWARD" 0 "FORWARD" ;
VAL_ 341 ESP_wheelRotationFR 3 "UNKNOWN" 2 "STANDSTILL" 1 "BACKWARD" 0 "FORWARD" ;
VAL_ 341 ESP_wheelRotationFL 3 "UNKNOWN" 2 "STANDSTILL" 1 "BACKWARD" 0 "FORWARD" ;
VAL_ 341 ESP_wheelRotationQF 1 "VALID" 0 "INVALID" ;
VAL_ 341 ESP_standstillStatus 1 "STANDSTILL" 0 "ROLLING" ;
VAL_ 341 ESP_vehicleSpeed 1023 "SNA" ;
VAL_ 373 ESP_wheelSpeedRR 8191 "SNA" ;
VAL_ 373 ESP_wheelSpeedRL 8191 "SNA" ;
VAL_ 373 ESP_wheelSpeedFR 8191 "SNA" ;
VAL_ 373 ESP_wheelSpeedFL 8191 "SNA" ;
VAL_ 389 ESP_brakeTorqueFL 4095 "SNA" ;
VAL_ 389 ESP_brakeTorqueFR 4095 "SNA" ;
VAL_ 389 ESP_brakeTorqueRL 4095 "SNA" ;
VAL_ 389 ESP_brakeTorqueRR 4095 "SNA" ;
VAL_ 389 ESP_brakeTorqueQF 1 "IN_SPEC" 0 "UNDEFINABLE_ACCURACY" ;
VAL_ 390 DIS_frontTorqueCommand 4096 "SNA" ;
VAL_ 390 DIS_frontTorqueActual 4096 "SNA" ;
VAL_ 390 DIS_frontAxleSpeed 32768 "SNA" ;
VAL_ 390 DIF_axleSpeed 32768 "SNA" ;
VAL_ 390 DIF_slavePedalPos 255 "SNA" ;
VAL_ 390 DIF_torqueActual 4096 "SNA" ;
VAL_ 390 DIF_torqueCommand 4096 "SNA" ;
VAL_ 421 DIF_vBatQF 0 "NOT_QUALIFIED" 1 "QUALIFIED" ;
VAL_ 472 DIS_torqueCommand 4096 "SNA" ;
VAL_ 472 DIS_torqueActual 4096 "SNA" ;
VAL_ 472 DIS_axleSpeed 32768 "SNA" ;
VAL_ 505 VCSEC_chargePortRequest 0 "NONE" 1 "OPEN" 2 "CLOSE" 3 "SNA" ;
VAL_ 513 VCFRONT_compressorState 0 "STANDBY" 1 "READY" 2 "RUNNING" 3 "FAULT" ;
VAL_ 513 VCFRONT_exvState 0 "UNINIT" 1 "INIT_OPEN" 2 "INIT_CLOSE" 3 "READY" 4 "FAULTED" 5 "WAIT" ;
VAL_ 513 VCFRONT_pumpBatteryRPMActual 1023 "SNA" ;
VAL_ 513 VCFRONT_pumpPowertrainRPMActual 1023 "SNA" ;
VAL_ 513 VCFRONT_radiatorFanRPMActual 1023 "SNA" ;
VAL_ 513 VCFRONT_solenoidEvapState 0 "UNDEFINED" 1 "OPENED" 2 "CLOSED" 3 "FAULTED" ;
VAL_ 513 VCFRONT_tempRefrigDischarge 2047 "SNA" ;
VAL_ 513 VCFRONT_tempSuperheatActual 1023 "SNA" ;
VAL_ 513 VCFRONT_loggingAndVitals10HzInde 7 "END" 3 "EXV_FLOW" 5 "EXV_FLOW_TARGET" 6 "EXV_STATE" 4 "HP_STATE" 2 "STATES_AND_SENSORS" 0 "TARGETS_AND_ACTUALS_0" 1 "TARGETS_SENSORS_AND_ACTUALS_1" ;
VAL_ 513 VCFRONT_ccrExvState 8 "CALIB_CLOSE" 9 "CALIB_CLOSE_OVERDRIVE" 4 "FAULTED" 2 "INIT_CLOSE" 1 "INIT_OPEN" 6 "OVERDRIVING_SHUT" 3 "READY" 7 "READY_SHUT" 0 "UNINIT" 5 "WAIT" ;
VAL_ 513 VCFRONT_chillerExvState 8 "CALIB_CLOSE" 9 "CALIB_CLOSE_OVERDRIVE" 4 "FAULTED" 2 "INIT_CLOSE" 1 "INIT_OPEN" 6 "OVERDRIVING_SHUT" 3 "READY" 7 "READY_SHUT" 0 "UNINIT" 5 "WAIT" ;
VAL_ 513 VCFRONT_coolantValveMode 3 "AMBIENT_SOURCE" 2 "BLEND" 1 "PARALLEL" 0 "SERIES" ;
VAL_ 513 VCFRONT_evapExvState 8 "CALIB_CLOSE" 9 "CALIB_CLOSE_OVERDRIVE" 4 "FAULTED" 2 "INIT_CLOSE" 1 "INIT_OPEN" 6 "OVERDRIVING_SHUT" 3 "READY" 7 "READY_SHUT" 0 "UNINIT" 5 "WAIT" ;
VAL_ 513 VCFRONT_exvState 8 "CALIB_CLOSE" 9 "CALIB_CLOSE_OVERDRIVE" 4 "FAULTED" 2 "INIT_CLOSE" 1 "INIT_OPEN" 6 "OVERDRIVING_SHUT" 3 "READY" 7 "READY_SHUT" 0 "UNINIT" 5 "WAIT" ;
VAL_ 513 VCFRONT_hpBatteryLoadType 2 "BATT_COOL" 1 "BATT_HEAT" 0 "NONE" ;
VAL_ 513 VCFRONT_hpBlendType 2 "HP_FULL" 0 "HP_NONE" 1 "HP_PARTIAL" ;
VAL_ 513 VCFRONT_hpCabinLoadType 1 "CC" 3 "EVAP" 0 "NONE" 2 "REHEAT" ;
VAL_ 513 VCFRONT_hpDominantLoad 5 "CC" 2 "CHILLER" 1 "EVAP" 6 "HIGH_BOTH" 4 "LCC" 3 "LOW_BOTH" 0 "NONE" ;
VAL_ 513 VCFRONT_hpHighSideHX 3 "BOTH" 2 "CC" 1 "LCC" 0 "NONE" ;
VAL_ 513 VCFRONT_hpLowSideHX 3 "BOTH" 1 "CHILLER" 2 "EVAP" 0 "NONE" ;
VAL_ 513 VCFRONT_hpReqCoolantMode 4 "AMBIENT_SOURCE" 0 "ANY" 3 "PARALLEL" 2 "SERIES_BYPASS" 1 "SERIES_NO_BYPASS" ;
VAL_ 513 VCFRONT_lccExvState 8 "CALIB_CLOSE" 9 "CALIB_CLOSE_OVERDRIVE" 4 "FAULTED" 2 "INIT_CLOSE" 1 "INIT_OPEN" 6 "OVERDRIVING_SHUT" 3 "READY" 7 "READY_SHUT" 0 "UNINIT" 5 "WAIT" ;
VAL_ 513 VCFRONT_pressureRefrigDischargeV 255 "SNA" ;
VAL_ 513 VCFRONT_pressureRefrigLiquid 255 "SNA" ;
VAL_ 513 VCFRONT_pressureRefrigSuctionVit 127 "SNA" ;
VAL_ 513 VCFRONT_pumpBatteryRPMActual 1023 "SNA" ;
VAL_ 513 VCFRONT_pumpPowertrainRPMActual 1023 "SNA" ;
VAL_ 513 VCFRONT_radiatorFanRPMActual 1023 "SNA" ;
VAL_ 513 VCFRONT_recircExvState 8 "CALIB_CLOSE" 9 "CALIB_CLOSE_OVERDRIVE" 4 "FAULTED" 2 "INIT_CLOSE" 1 "INIT_OPEN" 6 "OVERDRIVING_SHUT" 3 "READY" 7 "READY_SHUT" 0 "UNINIT" 5 "WAIT" ;
VAL_ 513 VCFRONT_solenoidEvapState 2 "CLOSED" 3 "FAULTED" 1 "OPENED" 0 "UNDEFINED" ;
VAL_ 513 VCFRONT_tempRefrigDischarge 2047 "SNA" ;
VAL_ 513 VCFRONT_tempRefrigLiquid 2047 "SNA" ;
VAL_ 513 VCFRONT_tempSuperheatActual 1023 "SNA" ;
VAL_ 516 PCS_chargeStatus 0 "IDLE" 1 "ENABLED" 2 "FAULTED" ;
VAL_ 516 PCS_chgMainState 0 "INIT" 1 "IDLE" 2 "STARTUP" 3 "WAIT_FOR_LINE_VOLTAGE" 4 "QUALIFY_LINE_CONFIG" 5 "SYSTEM_CONFIG" 6 "ENABLE" 7 "SHUTDOWN" 8 "FAULTED" 9 "CLEAR_FAULTS" ;
VAL_ 516 PCS_gridConfig 0 "SNA" 1 "SINGLE_PHASE" 2 "THREE_PHASE" 3 "THREE_PHASE_DELTA" ;
VAL_ 516 PCS_chargeShutdownRequest 2 "EMERGENCY_SHUTDOWN_REQUESTED" 1 "GRACEFUL_SHUTDOWN_REQUESTED" 0 "NO_SHUTDOWN_REQUESTED" ;
VAL_ 516 PCS_chgMainState 9 "PCS_CHG_STATE_CLEAR_FAULTS" 6 "PCS_CHG_STATE_ENABLE" 8 "PCS_CHG_STATE_FAULTED" 1 "PCS_CHG_STATE_IDLE" 0 "PCS_CHG_STATE_INIT" 4 "PCS_CHG_STATE_QUALIFY_LINE_CONFIG" 7 "PCS_CHG_STATE_SHUTDOWN" 2 "PCS_CHG_STATE_STARTUP" 5 "PCS_CHG_STATE_SYSTEM_CONFIG" 3 "PCS_CHG_STATE_WAIT_FOR_LINE_VOLTAGE" ;
VAL_ 516 PCS_gridConfig 1 "GRID_CONFIG_SINGLE_PHASE" 0 "GRID_CONFIG_SNA" 2 "GRID_CONFIG_THREE_PHASE" 3 "GRID_CONFIG_THREE_PHASE_DELTA" ;
VAL_ 516 PCS_hvChargeStatus 1 "PCS_CHARGE_BLOCKED" 2 "PCS_CHARGE_ENABLED" 3 "PCS_CHARGE_FAULTED" 0 "PCS_CHARGE_STANDBY" ;
VAL_ 516 PCS_hwVariantType 1 "PCS_32A_SINGLE_PHASE_VARIANT" 0 "PCS_48A_SINGLE_PHASE_VARIANT" 3 "PCS_HW_VARIANT_TYPE_SNA" 2 "PCS_THREE_PHASES_VARIANT" ;
VAL_ 522 HVP_fcContNegativeState 0 "SNA" 1 "OPEN" 2 "PRECHARGE" 3 "BLOCKED" 4 "PULLED_IN" 5 "OPENING" 6 "ECONOMIZED" 7 "WELDED" ;
VAL_ 522 HVP_fcContPositiveState 0 "SNA" 1 "OPEN" 2 "PRECHARGE" 3 "BLOCKED" 4 "PULLED_IN" 5 "OPENING" 6 "ECONOMIZED" 7 "WELDED" ;
VAL_ 522 HVP_fcContactorSetState 0 "SNA" 1 "OPEN" 2 "CLOSING" 3 "BLOCKED" 4 "OPENING" 5 "CLOSED" 6 "PARTIAL_WELD" 7 "WELDED" 8 "POSITIVE_CLOSED" 9 "NEGATIVE_CLOSED" ;
VAL_ 522 HVP_fcCtrsRequestStatus 0 "NOT_ACTIVE" 1 "ACTIVE" 2 "COMPLETED" ;
VAL_ 522 HVP_hvilStatus 0 "UNKNOWN" 1 "STATUS_OK" 2 "CURRENT_SOURCE_FAULT" 3 "INTERNAL_OPEN_FAULT" 4 "VEHICLE_OPEN_FAULT" 5 "PENTHOUSE_LID_OPEN_FAULT" 6 "UNKNOWN_LOCATION_OPEN_FAULT" 7 "VEHICLE_NODE_FAULT" 8 "NO_12V_SUPPLY" ;
VAL_ 522 HVP_packContNegativeState 0 "SNA" 1 "OPEN" 2 "PRECHARGE" 3 "BLOCKED" 4 "PULLED_IN" 5 "OPENING" 6 "ECONOMIZED" 7 "WELDED" ;
VAL_ 522 HVP_packContPositiveState 0 "SNA" 1 "OPEN" 2 "PRECHARGE" 3 "BLOCKED" 4 "PULLED_IN" 5 "OPENING" 6 "ECONOMIZED" 7 "WELDED" ;
VAL_ 522 HVP_packContactorSetState 0 "SNA" 1 "OPEN" 2 "CLOSING" 3 "BLOCKED" 4 "OPENING" 5 "CLOSED" 6 "PARTIAL_WELD" 7 "WELDED" 8 "POSITIVE_CLOSED" 9 "NEGATIVE_CLOSED" ;
VAL_ 522 HVP_packCtrsRequestStatus 0 "NOT_ACTIVE" 1 "ACTIVE" 2 "COMPLETED" ;
VAL_ 524 VCRIGHT_tempEvaporator 2047 "SNA" ;
VAL_ 524 VCRIGHT_tempEvaporatorTarget 255 "SNA" ;
VAL_ 524 VCRIGHT_hvacPerfTestState 2 "BLOWING" 0 "STOPPED" 1 "WAITING" ;
VAL_ 524 VCRIGHT_hvacPerfTestState 2 "BLOWING" 0 "STOPPED" 1 "WAITING" ;
VAL_ 524 VCRIGHT_tempAmbientRaw 0 "SNA" ;
VAL_ 525 TAS_currentLevel 0 "VERY_HIGH" 1 "HIGH" 2 "STANDARD" 3 "LOW" 4 "VERY_LOW" ;
VAL_ 525 TAS_filterMode 0 "NONE" 1 "INIT" 2 "CALIBRATE" 3 "TEST" 4 "READY" 5 "LOADING" 6 "DRIVE" 7 "STOPPING" ;
VAL_ 525 TAS_levelingState 0 "IDLE" 1 "READ_P_RESERVOIR" 2 "MANUAL_SPRING_CONTROL" 3 "EXHAUST_GALLERY" 4 "COMPRESSOR_RAMPUP" 5 "COMPRESSOR_PREFILL_GALLERY" 6 "FILL_RESERVOIR_FROM_COMPRESSOR" 7 "FILL_SPRING_FROM_COMPRESSOR" 8 "FILL_SPRING_FROM_BOOST" 9 "FILL_SPRING_FROM_RESERVOIR" 10 "FILL_SPRING_RESERVOIR_FROM_COMPRESSOR" 11 "LOWER_SPRING" 12 "EMPTY_RESERVOIR" ;
VAL_ 525 TAS_limpHomeMode 0 "0" 1 "10" 2 "20" 3 "30" 4 "40" ;
VAL_ 525 TAS_runMode 0 "INIT" 1 "SYSTEM_CHECK" 2 "SERVICE" 3 "ASSEMBLY" 4 "DAN" 5 "NORMAL" 6 "LOW_POWER" ;
VAL_ 525 TAS_targetLevel 0 "VERY_HIGH" 1 "HIGH" 2 "STANDARD" 3 "LOW" 4 "VERY_LOW" ;
VAL_ 526 PARK_sdiSensor1RawDistData 0 "BLOCKED" 1 "NEAR_DETECTION" 500 "NO_OBJECT_DETECTED" 511 "SNA" ;
VAL_ 526 PARK_sdiSensor2RawDistData 0 "BLOCKED" 1 "NEAR_DETECTION" 500 "NO_OBJECT_DETECTED" 511 "SNA" ;
VAL_ 526 PARK_sdiSensor3RawDistData 0 "BLOCKED" 1 "NEAR_DETECTION" 500 "NO_OBJECT_DETECTED" 511 "SNA" ;
VAL_ 526 PARK_sdiSensor4RawDistData 0 "BLOCKED" 1 "NEAR_DETECTION" 500 "NO_OBJECT_DETECTED" 511 "SNA" ;
VAL_ 526 PARK_sdiSensor5RawDistData 0 "BLOCKED" 1 "NEAR_DETECTION" 500 "NO_OBJECT_DETECTED" 511 "SNA" ;
VAL_ 526 PARK_sdiSensor6RawDistData 0 "BLOCKED" 1 "NEAR_DETECTION" 500 "NO_OBJECT_DETECTED" 511 "SNA" ;
VAL_ 529 RCM_airbagCutoffStatus 0 "RCM_PASSENGER_AIRBAG_ENABLED" 1 "RCM_PASSENGER_AIRBAG_DISABLED" 3 "SNA" ;
VAL_ 529 RCM_alrSwitchStatus 0 "RCM_ALR_NOT_ENGAGED" 1 "RCM_ALR_ENGAGED" 2 "RCM_ALR_FAULTED" 3 "SNA" ;
VAL_ 529 RCM_armStatus 0 "RCM_UNARMED" 1 "RCM_ARMED" 2 "ARMED_WITH_NOFIRE_CAL" 3 "SNA" ;
VAL_ 529 RCM_driverOrientationInitStatus 0 "RCM_DRIVER_ORIENTATION_INIT_NOT_COMPLETE" 1 "RCM_DRIVER_ORIENTATION_MATCHED_LHD" 2 "RCM_DRIVER_ORIENTATION_MATCHED_RHD" 3 "RCM_DRIVER_ORIENTATION_MISMATCH_DEFAULT_LHD" 4 "RCM_DRIVER_ORIENTATION_MISMATCH_DEFAULT_RHD" 7 "SNA" ;
VAL_ 529 RCM_edr1State 0 "EMPTY" 1 "STORED" 2 "LOCKED" 3 "UNAVAILABLE" ;
VAL_ 529 RCM_edr2State 0 "EMPTY" 1 "STORED" 2 "LOCKED" 3 "UNAVAILABLE" ;
VAL_ 529 RCM_imuOffsetLearnState 0 "OFFSET_LEARNING_OFF" 1 "SLOW_LEARNING_DISTANCE" 2 "FAST_LEARNING_TIME" 3 "OFFSETS_UNABLE_TO_LEARN" ;
VAL_ 529 RCM_keepPowerReason 0 "NO_KEEP_POWER_REQUEST" 1 "IN_IDLE_MODE" 2 "CRASH_ALGO_ACTIVE" 3 "EDR_STORING_TO_EEPROM" 4 "EDR_UPLOADING" 5 "CANNOT_POWER_DOWN" 6 "INITIALIZATION_PHASE" 7 "INVALID_POWER_OFF_REQUEST" ;
VAL_ 529 RCM_passAirbagIndicatorRequest 0 "RCM_PASSENGER_AIRBAG_INDICATOR_ON" 1 "RCM_PASSENGER_AIRBAG_INDICATOR_OFF" 3 "SNA" ;
VAL_ 529 RCM_seatTrackPositionDrvr 0 "RCM_SEAT_POSITION_NEAR" 1 "RCM_SEAT_POSITION_FAR" 2 "RCM_SEAT_POSITION_FAULTED" 3 "SNA" ;
VAL_ 529 RCM_seatTrackPositionPass 0 "RCM_SEAT_POSITION_NEAR" 1 "RCM_SEAT_POSITION_FAR" 2 "RCM_SEAT_POSITION_FAULTED" 3 "SNA" ;
VAL_ 529 RCM_vinLearnFlag 0 "RCM_VIN_NOT_STORED" 1 "RCM_VIN_STORED" 2 "RCM_VIN_STORED_MISMATCH" 3 "SNA" ;
VAL_ 529 RCM_warningIndicatorState 0 "RCM_WARNING_INDICATOR_OFF" 1 "RCM_WARNING_INDICATOR_ON" 3 "SNA" ;
VAL_ 530 BMS_chgPowerAvailable 2047 "BMS_chgPowerAvailable_SNA" ;
VAL_ 530 BMS_contactorState 0 "SNA" 1 "OPEN" 2 "OPENING" 3 "CLOSING" 4 "CLOSED" 5 "WELDED" 6 "BLOCKED" ;
VAL_ 530 BMS_diLimpRequest 0 "NONE" 1 "WELDED" ;
VAL_ 530 BMS_ecuLogUploadRequest 0 "NONE" 1 "1" 2 "2" 3 "3" ;
VAL_ 530 BMS_hvState 0 "DOWN" 1 "COMING_UP" 2 "GOING_DOWN" 3 "UP_FOR_DRIVE" 4 "UP_FOR_CHARGE" 5 "UP_FOR_DC_CHARGE" 6 "UP" ;
VAL_ 530 BMS_isolationResistance 1023 "BMS_isolationResistance_SNA" ;
VAL_ 530 BMS_state 0 "STANDBY" 1 "DRIVE" 2 "SUPPORT" 3 "CHARGE" 4 "FEIM" 5 "CLEAR_FAULT" 6 "FAULT" 7 "WELD" 8 "TEST" 9 "SNA" ;
VAL_ 530 BMS_uiChargeStatus 0 "DISCONNECTED" 1 "NO_POWER" 2 "ABOUT_TO_CHARGE" 3 "CHARGING" 4 "CHARGE_COMPLETE" 5 "CHARGE_STOPPED" ;
VAL_ 531 UI_cruiseSpeedCommand 0 "IDLE" 1 "INC_SHORT" 2 "INC_LONG" 3 "DEC_SHORT" 4 "DEC_LONG" 5 "SNAP" ;
VAL_ 531 UI_speedLimitTick 255 "SNA" ;
VAL_ 532 FC_postID 0 "MASTER" 1 "SLAVE" 2 "ID_2" 3 "ID_SNA" ;
VAL_ 532 FC_statusCode 0 "NOTREADY_SNA" 1 "READY" 2 "UPDATE_IN_PROGRESS" 3 "UNUSED_3" 4 "WAIT_POST_READY_TO_CHARGE" 5 "INT_ISOACTIVE" 6 "EXT_ISOACTIVE" 7 "POST_OUT_OF_SERVICE" 13 "NOTCOMPATIBLE" 14 "MALFUNCTION" 15 "NODATA" ;
VAL_ 532 FC_type 0 "SUPERCHARGER" 1 "CHADEMO" 2 "GB" 3 "CC_EVSE" 4 "COMBO" 5 "MC_EVSE" 6 "OTHER" 7 "SNA" ;
VAL_ 533 FC_externalIsolationResistance 255 "SNA" ;
VAL_ 535 FC_status3DataSelect 0 "Mux0" ;
VAL_ 535 FC_class 0 "SNA" 1 "SUPERCHARGER" 2 "URBANCHARGER" ;
VAL_ 535 FC_brand 0 "SNA" 1 "TESLA" ;
VAL_ 535 FC_coolingType 0 "SNA" 1 "CONVECTION" 2 "LIQUID" ;
VAL_ 535 FC_uiStopType 0 "SNA" 1 "TOGGLE" 2 "MOMENTARY" ;
VAL_ 536 UI_roadSign 0 "NONE" 1 "STOP_SIGN" 2 "TRAFFIC_LIGHT" 3 "SPEED_LIMIT" 4 "SPEED_SPLINE" 5 "SPLINE_ID_FULL" 255 "SNA" ;
VAL_ 536 UI_splineLocConfidence 0 "SNA" ;
VAL_ 536 UI_stopSignStopLineDist 1023 "SNA" ;
VAL_ 536 UI_stopSignStopLineConf 0 "SNA" ;
VAL_ 536 UI_trafficLightStopLineDist 1023 "SNA" ;
VAL_ 536 UI_trafficLightStopLineConf 0 "SNA" ;
VAL_ 536 UI_baseMapSpeedLimitMPS 255 "SNA" ;
VAL_ 536 UI_bottomQrtlFleetSpeedMPS 255 "SNA" ;
VAL_ 536 UI_topQrtlFleetSpeedMPS 255 "SNA" ;
VAL_ 536 UI_meanFleetSplineSpeedMPS 255 "SNA" ;
VAL_ 536 UI_medianFleetSpeedMPS 255 "SNA" ;
VAL_ 536 UI_meanFleetSplineAccelMPS2 255 "SNA" ;
VAL_ 536 UI_rampType 0 "NONE_SNA" 1 "ENTRANCE" 2 "EXIT" 3 "INTERCHANGE_ENTRANCE" 4 "INTERCHANGE_EXIT" ;
VAL_ 536 UI_currSplineIdFull 0 "SNA" ;
VAL_ 537 VCSEC_TPMSDataIndex 0 "TPMS_DATA_SENSOR_0" 1 "TPMS_DATA_SENSOR_1" 2 "TPMS_DATA_SENSOR_2" 3 "TPMS_DATA_SENSOR_3" ;
VAL_ 537 VCSEC_TPMSDataIndex 0 "TPMS_DATA_SENSOR_0" 1 "TPMS_DATA_SENSOR_1" 2 "TPMS_DATA_SENSOR_2" 3 "TPMS_DATA_SENSOR_3" ;
VAL_ 537 VCSEC_TPMSBatVoltage0 255 "SNA" ;
VAL_ 537 VCSEC_TPMSBatVoltage1 255 "SNA" ;
VAL_ 537 VCSEC_TPMSBatVoltage2 255 "SNA" ;
VAL_ 537 VCSEC_TPMSBatVoltage3 255 "SNA" ;
VAL_ 537 VCSEC_TPMSLocation0 0 "LOCATION_FL" 1 "LOCATION_FR" 2 "LOCATION_RL" 3 "LOCATION_RR" 4 "LOCATION_UNKNOWN" ;
VAL_ 537 VCSEC_TPMSLocation1 0 "LOCATION_FL" 1 "LOCATION_FR" 2 "LOCATION_RL" 3 "LOCATION_RR" 4 "LOCATION_UNKNOWN" ;
VAL_ 537 VCSEC_TPMSLocation2 0 "LOCATION_FL" 1 "LOCATION_FR" 2 "LOCATION_RL" 3 "LOCATION_RR" 4 "LOCATION_UNKNOWN" ;
VAL_ 537 VCSEC_TPMSLocation3 0 "LOCATION_FL" 1 "LOCATION_FR" 2 "LOCATION_RL" 3 "LOCATION_RR" 4 "LOCATION_UNKNOWN" ;
VAL_ 537 VCSEC_TPMSPressure0 255 "SNA" ;
VAL_ 537 VCSEC_TPMSPressure1 255 "SNA" ;
VAL_ 537 VCSEC_TPMSPressure2 255 "SNA" ;
VAL_ 537 VCSEC_TPMSPressure3 255 "SNA" ;
VAL_ 537 VCSEC_TPMSTemperature0 255 "SNA" ;
VAL_ 537 VCSEC_TPMSTemperature1 255 "SNA" ;
VAL_ 537 VCSEC_TPMSTemperature2 255 "SNA" ;
VAL_ 537 VCSEC_TPMSTemperature3 255 "SNA" ;
VAL_ 541 CP_acChargeState 0 "INACTIVE" 1 "ACTIVE" 2 "SHUTDOWN" ;
VAL_ 541 CP_cableType 0 "IEC" 1 "SAE" 2 "GB_AC" 3 "GB_DC" 4 "SNA" ;
VAL_ 541 CP_evseChargeType 0 "NO_CHARGER_PRESENT" 1 "DC_CHARGER_PRESENT" 2 "AC_CHARGER_PRESENT" ;
VAL_ 541 CP_gbState 0 "IDLE" 1 "WAIT_FOR_HANDSHAKE" 2 "HANDSHAKING" 3 "RECOGNITION" 4 "CHARGE_CONFIG" 5 "VEH_PACK_PRECHARGE" 6 "READY_TO_CHARGE" 7 "CHARGING_START" 8 "CHARGING" 9 "STOP_CHARGE" 10 "NORMAL_SHUTDOWN" 11 "END_OF_CHARGE" 12 "EVSE_READY_TO_RESTART" 13 "EVSE_ERROR" 14 "WAIT_FOR_ERROR_SHUTDOWN" 15 "RESTART_CHARGE" 16 "FAILURE" ;
VAL_ 541 CP_gbdcFailureReason 0 "FAILURE_NONE" 1 "ATTEMPTS_EXPIRED" 2 "SHUTDOWN_FAILURE" 3 "CRITICAL_FAILURE" ;
VAL_ 541 CP_gbdcStopChargeReason 0 "STOP_REASON_NONE" 1 "VEH_REQUESTED" 2 "EVSE_REQUESTED" 3 "COMMS_TIMEOUT" 4 "EVSE_FAULT" 5 "EVSE_CRITICAL_FAULT" 6 "LIVE_DISCONNECT" ;
VAL_ 541 CP_pilot 0 "NONE" 1 "FAULTED" 2 "LINE_CHARGE" 3 "FAST_CHARGE" 4 "IDLE" 5 "INVALID" 6 "UNUSED_6" 7 "SNA" ;
VAL_ 541 CP_proximity 0 "SNA" 1 "DISCONNECTED" 2 "UNLATCHED" 3 "LATCHED" ;
VAL_ 541 CP_teslaSwcanState 0 "INACTIVE" 1 "ACCEPT" 2 "RECEIVE" 3 "ESTABLISHED" 4 "FAULT" 5 "GO_TO_SLEEP" 6 "OFFBOARD_UPDATE_IN_PROGRESS" ;
VAL_ 542 PARK_pscAngleActive 0 "INACTIVE" 1 "REQUEST_CONTROL" ;
VAL_ 542 PARK_pscCrossLeftParkable 0 "NONE" 1 "PARKING_SLOT_OK" 2 "PARKING_SLOT_OK_POSITION_OK" 3 "SNA" ;
VAL_ 542 PARK_pscCrossRightParkable 0 "NONE" 1 "PARKING_SLOT_OK" 2 "PARKING_SLOT_OK_POSITION_OK" 3 "SNA" ;
VAL_ 542 PARK_pscCrossSpace 0 "NONE_AVAILABLE" 1 "RIGHT_AVAILABLE" 2 "LEFT_AVAILABLE" 3 "BOTH_AVAILABLE" ;
VAL_ 542 PARK_pscManeuverDistance 2047 "SNA" ;
VAL_ 542 PARK_pscMaxVelocity 63 "SNA" ;
VAL_ 542 PARK_pscParallelLeftParkable 0 "NONE" 1 "PARKING_SLOT_OK" 2 "PARKING_SLOT_OK_POSITION_OK" 3 "SNA" ;
VAL_ 542 PARK_pscParallelRightParkable 0 "NONE" 1 "PARKING_SLOT_OK" 2 "PARKING_SLOT_OK_POSITION_OK" 3 "SNA" ;
VAL_ 542 PARK_pscParallelSpace 0 "NONE_AVAILABLE" 1 "RIGHT_AVAILABLE" 2 "LEFT_AVAILABLE" 3 "BOTH_AVAILABLE" ;
VAL_ 542 PARK_pscParkAbortReason 0 "NONE" 1 "VELOCITY_TOO_HIGH" 2 "MAX_NUM_OF_MOVES" 3 "NO_VALID_PATH" 4 "UNCONTROLLED_TRAVEL_DIST_REACHED" 5 "OFF_TRACK" 6 "MAX_SWA_DEV_EXCEEDED" 7 "MAX_YAW_ANGLE_REACHED" 8 "OBSTACLE_ON_PATH" 9 "PARK_SPACE_TOO_SMALL" 10 "FULL_WARNING_ON_BOTH_SIDES" 11 "HANDS_ON_DETECTED" 12 "VEHICLE_DYNAMICS_INTERVENTION" 13 "EPAS_FAULT" 14 "DAS_ABORT" 15 "ECU_INTERNAL_FAULT" 16 "SYSTEM_FAULT" 17 "SYSTEM_SERVICE" 18 "ERROR" 31 "SNA" ;
VAL_ 542 PARK_pscParkInstruction 0 "NO_MESSAGE" 1 "STOP" 2 "DRIVE_FORWARD" 3 "DRIVE_BACKWARD" 4 "ABORTED" 5 "EXPLORATION" 7 "SNA" ;
VAL_ 542 PARK_pscParkStatus 0 "NOT_AVAILABLE" 1 "SEARCHING" 2 "GUIDANCE_LEFT" 3 "GUIDANCE_RIGHT" 4 "PRE_GUIDANCE" 5 "GUIDANCE_FINISHED" 6 "FAULT" 7 "SNA" ;
VAL_ 545 VCFRONT_LVPowerStateIndex 0 "Mux0" 1 "Mux1" ;
VAL_ 545 VCFRONT_vehiclePowerState 0 "OFF" 1 "CONDITIONING" 2 "ACCESSORY" 3 "DRIVE" ;
VAL_ 545 VCFRONT_parkLVState 0 "OFF" 1 "ON" 2 "GOING_DOWN" 3 "FAULT" ;
VAL_ 545 VCFRONT_espLVState 0 "OFF" 1 "ON" 2 "GOING_DOWN" 3 "FAULT" ;
VAL_ 545 VCFRONT_radcLVState 0 "OFF" 1 "ON" 2 "GOING_DOWN" 3 "FAULT" ;
VAL_ 545 VCFRONT_hvacCompLVState 0 "OFF" 1 "ON" 2 "GOING_DOWN" 3 "FAULT" ;
VAL_ 545 VCFRONT_ptcLVRequest 0 "OFF" 1 "ON" 2 "GOING_DOWN" 3 "FAULT" ;
VAL_ 545 VCFRONT_sccmLVRequest 0 "OFF" 1 "ON" 2 "GOING_DOWN" 3 "FAULT" ;
VAL_ 545 VCFRONT_tpmsLVRequest 0 "OFF" 1 "ON" 2 "GOING_DOWN" 3 "FAULT" ;
VAL_ 545 VCFRONT_rcmLVRequest 0 "OFF" 1 "ON" 2 "GOING_DOWN" 3 "FAULT" ;
VAL_ 545 VCFRONT_iBoosterLVState 0 "OFF" 1 "ON" 2 "GOING_DOWN" 3 "FAULT" ;
VAL_ 545 VCFRONT_tunerLVRequest 0 "OFF" 1 "ON" 2 "GOING_DOWN" 3 "FAULT" ;
VAL_ 545 VCFRONT_amplifierLVRequest 0 "OFF" 1 "ON" 2 "GOING_DOWN" 3 "FAULT" ;
VAL_ 545 VCFRONT_das1HighCurrentLVState 0 "OFF" 1 "ON" 2 "GOING_DOWN" 3 "FAULT" ;
VAL_ 545 VCFRONT_das2HighCurrentLVState 0 "OFF" 1 "ON" 2 "GOING_DOWN" 3 "FAULT" ;
VAL_ 545 VCFRONT_diLVRequest 0 "OFF" 1 "ON" 2 "GOING_DOWN" 3 "FAULT" ;
VAL_ 545 VCFRONT_disLVState 0 "OFF" 1 "ON" 2 "GOING_DOWN" 3 "FAULT" ;
VAL_ 545 VCFRONT_oilPumpFrontLVState 0 "OFF" 1 "ON" 2 "GOING_DOWN" 3 "FAULT" ;
VAL_ 545 VCFRONT_oilPumpRearLVRequest 0 "OFF" 1 "ON" 2 "GOING_DOWN" 3 "FAULT" ;
VAL_ 545 VCFRONT_ocsLVRequest 0 "OFF" 1 "ON" 2 "GOING_DOWN" 3 "FAULT" ;
VAL_ 545 VCFRONT_vcleftHiCurrentLVState 0 "OFF" 1 "ON" 2 "GOING_DOWN" 3 "FAULT" ;
VAL_ 545 VCFRONT_vcrightHiCurrentLVState 0 "OFF" 1 "ON" 2 "GOING_DOWN" 3 "FAULT" ;
VAL_ 545 VCFRONT_uiHiCurrentLVState 0 "OFF" 1 "ON" 2 "GOING_DOWN" 3 "FAULT" ;
VAL_ 545 VCFRONT_uiAudioLVState 0 "OFF" 1 "ON" 2 "GOING_DOWN" 3 "FAULT" ;
VAL_ 545 VCFRONT_cpLVRequest 0 "OFF" 1 "ON" 2 "GOING_DOWN" 3 "FAULT" ;
VAL_ 545 VCFRONT_epasLVState 0 "OFF" 1 "ON" 2 "GOING_DOWN" 3 "FAULT" ;
VAL_ 545 VCFRONT_hvcLVRequest 0 "OFF" 1 "ON" 2 "GOING_DOWN" 3 "FAULT" ;
VAL_ 545 VCFRONT_tasLVState 0 "OFF" 1 "ON" 2 "GOING_DOWN" 3 "FAULT" ;
VAL_ 545 VCFRONT_pcsLVState 0 "OFF" 1 "ON" 2 "GOING_DOWN" 3 "FAULT" ;
VAL_ 548 PCS_dcdc12VSupportStatus 0 "IDLE" 1 "ACTIVE" 2 "FAULTED" ;
VAL_ 548 PCS_dcdcHvBusDischargeStatus 0 "IDLE" 1 "ACTIVE" 2 "FAULTED" ;
VAL_ 548 PCS_dcdcInitialPrechargeSubState 0 "PWR_UP_INIT" 1 "STANDBY" 2 "12V_SUPPORT_ACTIVE" 3 "DIS_HVBUS" 4 "PCHG_FAST_DIS_HVBUS" 5 "PCHG_SLOW_DIS_HVBUS" 6 "PCHG_DWELL_CHARGE" 7 "PCHG_DWELL_WAIT" 8 "PCHG_DI_RECOVERY_WAIT" 9 "PCHG_ACTIVE" 10 "PCHG_FLT_FAST_DIS_HVBUS" 11 "SHUTDOWN" 12 "12V_SUPPORT_FAULTED" 13 "DIS_HVBUS_FAULTED" 14 "PCHG_FAULTED" 15 "CLEAR_FAULTS" 16 "FAULTED" 17 "NUM" ;
VAL_ 548 PCS_dcdcMainState 0 "STANDBY" 1 "12V_SUPPORT_ACTIVE" 2 "PRECHARGE_STARTUP" 3 "PRECHARGE_ACTIVE" 4 "DIS_HVBUS_ACTIVE" 5 "SHUTDOWN" 6 "FAULTED" ;
VAL_ 548 PCS_dcdcPrechargeStatus 0 "IDLE" 1 "ACTIVE" 2 "FAULTED" ;
VAL_ 548 PCS_dcdcSubState 0 "PWR_UP_INIT" 1 "STANDBY" 2 "12V_SUPPORT_ACTIVE" 3 "DIS_HVBUS" 4 "PCHG_FAST_DIS_HVBUS" 5 "PCHG_SLOW_DIS_HVBUS" 6 "PCHG_DWELL_CHARGE" 7 "PCHG_DWELL_WAIT" 8 "PCHG_DI_RECOVERY_WAIT" 9 "PCHG_ACTIVE" 10 "PCHG_FLT_FAST_DIS_HVBUS" 11 "SHUTDOWN" 12 "12V_SUPPORT_FAULTED" 13 "DIS_HVBUS_FAULTED" 14 "PCHG_FAULTED" 15 "CLEAR_FAULTS" 16 "FAULTED" 17 "NUM" ;
VAL_ 548 PCS_ecuLogUploadRequest 0 "NONE" 1 "1" 2 "2" 3 "3" ;
VAL_ 549 VCRIGHT_amplifierLVState 3 "LV_FAULT" 2 "LV_GOING_DOWN" 0 "LV_OFF" 1 "LV_ON" ;
VAL_ 549 VCRIGHT_eFuseLockoutStatus 2 "EFUSE_LOCKOUT_STATUS_ACTIVE" 0 "EFUSE_LOCKOUT_STATUS_IDLE" 1 "EFUSE_LOCKOUT_STATUS_PENDING" ;
VAL_ 549 VCRIGHT_hvcLVState 3 "LV_FAULT" 2 "LV_GOING_DOWN" 0 "LV_OFF" 1 "LV_ON" ;
VAL_ 549 VCRIGHT_lumbarLVState 3 "LV_FAULT" 2 "LV_GOING_DOWN" 0 "LV_OFF" 1 "LV_ON" ;
VAL_ 549 VCRIGHT_ocsLVState 3 "LV_FAULT" 2 "LV_GOING_DOWN" 0 "LV_OFF" 1 "LV_ON" ;
VAL_ 549 VCRIGHT_ptcLVState 3 "LV_FAULT" 2 "LV_GOING_DOWN" 0 "LV_OFF" 1 "LV_ON" ;
VAL_ 549 VCRIGHT_rcmLVState 3 "LV_FAULT" 2 "LV_GOING_DOWN" 0 "LV_OFF" 1 "LV_ON" ;
VAL_ 549 VCRIGHT_rearOilPumpLVState 3 "LV_FAULT" 2 "LV_GOING_DOWN" 0 "LV_OFF" 1 "LV_ON" ;
VAL_ 549 VCRIGHT_tunerLVState 3 "LV_FAULT" 2 "LV_GOING_DOWN" 0 "LV_OFF" 1 "LV_ON" ;
VAL_ 549 VCRIGHT_vehiclePowerStateDBG 2 "VEHICLE_POWER_STATE_ACCESSORY" 1 "VEHICLE_POWER_STATE_CONDITIONING" 3 "VEHICLE_POWER_STATE_DRIVE" 0 "VEHICLE_POWER_STATE_OFF" ;
VAL_ 551 CMP_state 3 "CMP_STATE_FAULT" 0 "CMP_STATE_NONE" 1 "CMP_STATE_NORMAL" 15 "CMP_STATE_SNA" 5 "CMP_STATE_SOFT_SHUTDOWN" 4 "CMP_STATE_SOFT_START" 2 "CMP_STATE_WAIT" ;
VAL_ 552 EPBR_csmFaultReason 0 "NONE" 1 "EPBM_DISABLED" 2 "EPBM_FAULTED" 3 "STATE_MISMATCH" 4 "TIMEOUT_CALIBRATE" 5 "APPLY_BLOCKED" 6 "RELEASE_BLOCKED" 7 "TIMEOUT_APPLY_COMPLETE" 8 "TIMEOUT_APPLY_INRUSH" 9 "TIMEOUT_WAIT_FOR_CLAMP" 10 "TIMEOUT_RELEASE_INRUSH" 11 "TIMEOUT_RELEASE_WAIT_FOR_ENDSTOP" 12 "TIMEOUT_RELEASE_COMPLETE" 13 "TIMEOUT_EPBM_CUTOFF" 14 "TIMEOUT_NO_RAMP" 15 "TIMEOUT_EPBM_START" 16 "MOTOR_IDLE_FAULT" 17 "MOTOR_ACTIVE_FAULT" 18 "MOTOR_NOT_READY" 19 "EPBM_MIA" 20 "NVM_MISMATCH" 21 "REMOTE_MIA" ;
VAL_ 552 EPBR_epbmCDPQualified 0 "IDLE" 1 "VALID" 2 "INVALID" ;
VAL_ 552 EPBR_esmCaliperRequest 0 "INVALID" 1 "NONE" 2 "APPLY" 3 "RELEASE" 4 "ENDSTOP" ;
VAL_ 552 EPBR_esmOperationTrigger 0 "PBUTTON_PRESSED_STOPPED" 1 "PBUTTON_PRESSED_OKTOPARK" 2 "PBUTTON_PRESSED_FAST" 3 "PBUTTON_PRESSED_UNKNOWN" 4 "PBUTTON_RELEASED" 5 "ACTIVE_PARK_REQUEST" 6 "DI_UNPARK" 7 "TOUCHSCREEN" 8 "WINCHMODE_EXIT" 9 "WINCHMODE_ENTER" 10 "WINCHMODE_UNAVAILABLE" 11 "SERVICE" 12 "DIAG_CLOSE" 13 "DIAG_OPEN" 14 "DIAG_EXIT" 15 "USER_CONFIRMED" 16 "USER_CANCEL" 17 "SPEED_STOPPED" 18 "SPEED_OKAYTOPARK" 19 "SPEED_FAST" 20 "TIMEOUT" 21 "SAVESTATE_ON_BOOT" 22 "REAPPLY" 23 "SUMMON_COMPLETE" 24 "FAULT" 25 "SUMMON_FAULT" 26 "DISQUALIFIED" 27 "EPBM_DISQUALIFIED" 28 "ACCELERATION" 29 "SYSTEM_APPLY" 30 "DRIVER_IS_LEAVING" ;
VAL_ 552 EPBR_internalCDPRequest 0 "NOT_REQUESTED" 1 "REQUESTED" ;
VAL_ 552 EPBR_summonFaultReason 0 "NONE" 1 "DI_MIA" 2 "DAS_MIA" 3 "ESP_MIA" 4 "EPBM_MIA" 5 "DI_FAULT" 6 "DI_APC_FAULT" 7 "DAS_FAULT" 8 "ESP_FAULT" 9 "VEH_CAN_FAULT" 10 "EAC_NOT_ALLOWED" 11 "EPBM_REQUEST" 12 "SPEED" 13 "EXTERNAL" 14 "PARK_MIA" 15 "PM_MIA" 16 "PM_REQUEST" 17 "OOC" 18 "MISMATCH" 19 "EPB_FAULT" 20 "DI_STATE_INVALID" 21 "PASSIVE_REQUEST" 22 "EPBREMOTE_MIA" 23 "REMOTE_SUMMON_FAULTED" 24 "LOCAL_UNIT_FAULTED" 25 "REMOTE_UNIT_FAULTED" 26 "START_IN_UNAVAILABLE" 27 "INVALID_REMOTE_STATE" 28 "REMOTE_DID_NOT_START" ;
VAL_ 552 EPBR_summonState 0 "INIT" 1 "IDLE" 2 "ARMED" 3 "ACTIVE" 4 "COMPLETE" 5 "FAULT" 6 "UNAVAILABLE" ;
VAL_ 552 EPBR_unitFaultStatus 0 "NOMINAL" 1 "RETRY" 2 "FAULT" 3 "FAULT_IDLE" ;
VAL_ 552 EPBR_unitStatus 0 "UNKNOWN" 1 "OPEN" 2 "DYNAMIC" 3 "PARK" 4 "START" 5 "SERVICE" 6 "WINCHMODE" 7 "WINCHMODE_RELEASING" 8 "PARKING" 9 "DYNAMIC_APPLYING" 10 "RELEASING" 11 "SERVICE_RELEASING" 12 "PARK_PENDING" 13 "WINCHMODE_PENDING" 14 "SUMMON" 15 "SUMMON_RELEASING" 16 "SUMMON_PARKING" 17 "EXTERNAL_DYNAMIC" 18 "RELEASING_FOR_EXTERNAL_PARK" 19 "EXTERNAL_PARKING" 20 "DYNAMIC_PARKING" 21 "COUNT" ;
VAL_ 553 SCCM_gearStalkStatus 0 "IDLE" 1 "UP_1" 2 "UP_2" 3 "DOWN_1" 4 "DOWN_2" 5 "SNA" ;
VAL_ 553 SCCM_parkButtonStatus 0 "NOT_PRESSED" 1 "1ST_DETENT" 2 "2ND_DETENT" 3 "SNA" ;
VAL_ 554 HVP_dcLinkVoltageFiltered 550 "SNA" ;
VAL_ 554 HVP_dcLinkVoltageFiltered 550 "SNA" ;
VAL_ 554 HVP_pcsControlRequest 3 "DISCHARGE" 2 "PRECHARGE" 0 "SHUTDOWN" 1 "SUPPORT" ;
VAL_ 558 PARK_sdiSensor10RawDistData 0 "BLOCKED" 1 "NEAR_DETECTION" 500 "NO_OBJECT_DETECTED" 511 "SNA" ;
VAL_ 558 PARK_sdiSensor11RawDistData 0 "BLOCKED" 1 "NEAR_DETECTION" 500 "NO_OBJECT_DETECTED" 511 "SNA" ;
VAL_ 558 PARK_sdiSensor12RawDistData 0 "BLOCKED" 1 "NEAR_DETECTION" 500 "NO_OBJECT_DETECTED" 511 "SNA" ;
VAL_ 558 PARK_sdiSensor7RawDistData 0 "BLOCKED" 1 "NEAR_DETECTION" 500 "NO_OBJECT_DETECTED" 511 "SNA" ;
VAL_ 558 PARK_sdiSensor8RawDistData 0 "BLOCKED" 1 "NEAR_DETECTION" 500 "NO_OBJECT_DETECTED" 511 "SNA" ;
VAL_ 558 PARK_sdiSensor9RawDistData 0 "BLOCKED" 1 "NEAR_DETECTION" 500 "NO_OBJECT_DETECTED" 511 "SNA" ;
VAL_ 562 BMS_fcContactorRequest 1 "SET_REQUEST_CLOSE" 4 "SET_REQUEST_CLOSE_NEGATIVE_ONLY" 5 "SET_REQUEST_CLOSE_POSITIVE_ONLY" 2 "SET_REQUEST_OPEN" 3 "SET_REQUEST_OPEN_IMMEDIATELY" 0 "SET_REQUEST_SNA" ;
VAL_ 562 BMS_fcContactorRequest 1 "SET_REQUEST_CLOSE" 4 "SET_REQUEST_CLOSE_NEGATIVE_ONLY" 5 "SET_REQUEST_CLOSE_POSITIVE_ONLY" 2 "SET_REQUEST_OPEN" 3 "SET_REQUEST_OPEN_IMMEDIATELY" 0 "SET_REQUEST_SNA" ;
VAL_ 562 BMS_fcLinkOkToEnergizeRequest 1 "FC_LINK_ENERGY_AC" 2 "FC_LINK_ENERGY_DC" 0 "FC_LINK_ENERGY_NONE" ;
VAL_ 562 BMS_internalHvilSenseV 65535 "SNA" ;
VAL_ 562 BMS_packContactorRequest 1 "SET_REQUEST_CLOSE" 4 "SET_REQUEST_CLOSE_NEGATIVE_ONLY" 5 "SET_REQUEST_CLOSE_POSITIVE_ONLY" 2 "SET_REQUEST_OPEN" 3 "SET_REQUEST_OPEN_IMMEDIATELY" 0 "SET_REQUEST_SNA" ;
VAL_ 568 UI_countryCode 0 "UNKNOWN" 1023 "SNA" ;
VAL_ 568 UI_mapSpeedLimit 0 "UNKNOWN" 1 "LESS_OR_EQ_5" 2 "LESS_OR_EQ_7" 3 "LESS_OR_EQ_10" 4 "LESS_OR_EQ_15" 5 "LESS_OR_EQ_20" 6 "LESS_OR_EQ_25" 7 "LESS_OR_EQ_30" 8 "LESS_OR_EQ_35" 9 "LESS_OR_EQ_40" 10 "LESS_OR_EQ_45" 11 "LESS_OR_EQ_50" 12 "LESS_OR_EQ_55" 13 "LESS_OR_EQ_60" 14 "LESS_OR_EQ_65" 15 "LESS_OR_EQ_70" 16 "LESS_OR_EQ_75" 17 "LESS_OR_EQ_80" 18 "LESS_OR_EQ_85" 19 "LESS_OR_EQ_90" 20 "LESS_OR_EQ_95" 21 "LESS_OR_EQ_100" 22 "LESS_OR_EQ_105" 23 "LESS_OR_EQ_110" 24 "LESS_OR_EQ_115" 25 "LESS_OR_EQ_120" 26 "LESS_OR_EQ_130" 27 "LESS_OR_EQ_140" 28 "LESS_OR_EQ_150" 29 "LESS_OR_EQ_160" 30 "UNLIMITED" 31 "SNA" ;
VAL_ 568 UI_mapSpeedLimitDependency 0 "NONE" 1 "SCHOOL" 2 "RAIN" 3 "SNOW" 4 "TIME" 5 "SEASON" 6 "LANE" 7 "SNA" ;
VAL_ 568 UI_mapSpeedLimitType 1 "REGULAR" 2 "ADVISORY" 3 "DEPENDENT" 4 "BUMPS" 7 "UNKNOWN_SNA" ;
VAL_ 568 UI_mapSpeedUnits 0 "MPH" 1 "KPH" ;
VAL_ 568 UI_nextBranchDist 31 "SNA" ;
VAL_ 568 UI_roadClass 0 "UNKNOWN_INVALID_SNA" 1 "CLASS_1_MAJOR" 2 "CLASS_2" 3 "CLASS_3" 4 "CLASS_4" 5 "CLASS_5" 6 "CLASS_6_MINOR" ;
VAL_ 569 DAS_leftLineUsage 0 "REJECTED_UNAVAILABLE" 1 "AVAILABLE" 2 "FUSED" 3 "BLACKLISTED" ;
VAL_ 569 DAS_rightLineUsage 0 "REJECTED_UNAVAILABLE" 1 "AVAILABLE" 2 "FUSED" 3 "BLACKLISTED" ;
VAL_ 569 DAS_leftFork 0 "NONE" 1 "AVAILABLE" 2 "SELECTED" 3 "UNAVAILABLE" ;
VAL_ 569 DAS_rightFork 0 "NONE" 1 "AVAILABLE" 2 "SELECTED" 3 "UNAVAILABLE" ;
VAL_ 573 CP_chargeShutdownRequest 2 "EMERGENCY_SHUTDOWN_REQUESTED" 1 "GRACEFUL_SHUTDOWN_REQUESTED" 0 "NO_SHUTDOWN_REQUESTED" ;
VAL_ 573 CP_hvChargeStatus 1 "CP_CHARGE_CONNECTED" 5 "CP_CHARGE_ENABLED" 6 "CP_CHARGE_FAULTED" 0 "CP_CHARGE_INACTIVE" 2 "CP_CHARGE_STANDBY" 4 "CP_EVSE_TEST_PASSED" 3 "CP_EXT_EVSE_TEST_ACTIVE" ;
VAL_ 577 VCFRONT_coolantAirPurgeBatState 0 "INACTIVE" 1 "ACTIVE" 2 "COMPLETE" 3 "INTERRUPTED" 4 "PENDING" ;
VAL_ 577 VCFRONT_coolantFlowBatReason 0 "NONE" 1 "COOLANT_AIR_PURGE" 2 "NO_FLOW_REQ" 3 "OVERRIDE_BATT" 4 "ACTIVE_MANAGER_BATT" 5 "PASSIVE_MANAGER_BATT" 6 "BMS_FLOW_REQ" 7 "DAS_FLOW_REQ" 8 "OVERRIDE_PT" 9 "ACTIVE_MANAGER_PT" 10 "PASSIVE_MANAGER_PT" 11 "PCS_FLOW_REQ" 12 "DI_FLOW_REQ" 13 "DIS_FLOW_REQ" ;
VAL_ 577 VCFRONT_coolantFlowPTReason 0 "NONE" 1 "COOLANT_AIR_PURGE" 2 "NO_FLOW_REQ" 3 "OVERRIDE_BATT" 4 "ACTIVE_MANAGER_BATT" 5 "PASSIVE_MANAGER_BATT" 6 "BMS_FLOW_REQ" 7 "DAS_FLOW_REQ" 8 "OVERRIDE_PT" 9 "ACTIVE_MANAGER_PT" 10 "PASSIVE_MANAGER_PT" 11 "PCS_FLOW_REQ" 12 "DI_FLOW_REQ" 13 "DIS_FLOW_REQ" ;
VAL_ 577 VCFRONT_wasteHeatRequestType 0 "NONE" 1 "PARTIAL" 2 "FULL" ;
VAL_ 578 VCLEFT_cpLVState 3 "LV_FAULT" 2 "LV_GOING_DOWN" 0 "LV_OFF" 1 "LV_ON" ;
VAL_ 578 VCLEFT_diLVState 3 "LV_FAULT" 2 "LV_GOING_DOWN" 0 "LV_OFF" 1 "LV_ON" ;
VAL_ 578 VCLEFT_lumbarLVState 3 "LV_FAULT" 2 "LV_GOING_DOWN" 0 "LV_OFF" 1 "LV_ON" ;
VAL_ 578 VCLEFT_rcmLVState 3 "LV_FAULT" 2 "LV_GOING_DOWN" 0 "LV_OFF" 1 "LV_ON" ;
VAL_ 578 VCLEFT_sccmLVState 3 "LV_FAULT" 2 "LV_GOING_DOWN" 0 "LV_OFF" 1 "LV_ON" ;
VAL_ 578 VCLEFT_swcLVState 3 "LV_FAULT" 2 "LV_GOING_DOWN" 0 "LV_OFF" 1 "LV_ON" ;
VAL_ 578 VCLEFT_tpmsLVState 3 "LV_FAULT" 2 "LV_GOING_DOWN" 0 "LV_OFF" 1 "LV_ON" ;
VAL_ 578 VCLEFT_vehiclePowerStateDBG 2 "VEHICLE_POWER_STATE_ACCESSORY" 1 "VEHICLE_POWER_STATE_CONDITIONING" 3 "VEHICLE_POWER_STATE_DRIVE" 0 "VEHICLE_POWER_STATE_OFF" ;
VAL_ 579 VCRIGHT_hvacACRunning 0 "OFF" 1 "ON" ;
VAL_ 579 VCRIGHT_hvacAirDistributionMode 0 "NONE" 1 "FLOOR" 2 "PANEL" 3 "PANEL_FLOOR" 4 "DEFROST" 5 "DEFROST_FLOOR" 6 "DEFROST_PANEL" 7 "DEFROST_PANEL_FLOOR" ;
VAL_ 579 VCRIGHT_hvacBlowerSegment 0 "OFF" 1 "1" 2 "2" 3 "3" 4 "4" 5 "5" 6 "6" 7 "7" 8 "8" 9 "9" 10 "10" 11 "11" ;
VAL_ 579 VCRIGHT_hvacDuctTargetLeft 255 "SNA" ;
VAL_ 579 VCRIGHT_hvacDuctTargetRight 255 "SNA" ;
VAL_ 579 VCRIGHT_hvacModelInitStatus 4 "INIT_FORWARD_CALC" 2 "INIT_FROM_SENSORS" 3 "INIT_FROM_SENSORS_PREDICTION_ERROR" 5 "INIT_WAITING_FOR_SENSORS" 1 "NOT_INIT_WAIT_FOR_GTW" 0 "NOT_INIT_WAIT_FOR_SENSORS" ;
VAL_ 579 VCRIGHT_hvacPowerState 0 "OFF" 1 "ON" 4 "OVERHEAT_PROTECT" 3 "OVERHEAT_PROTECT_FANONLY" 2 "PRECONDITION" ;
VAL_ 579 VCRIGHT_hvacRecirc 0 "AUTO" 2 "FRESH" 1 "RECIRC" ;
VAL_ 579 VCRIGHT_hvacSecondRowState 0 "AUTO" 4 "HIGH" 2 "LOW" 3 "MED" 1 "OFF" ;
VAL_ 579 VCRIGHT_hvacVentStatus 0 "BOTH" 1 "LEFT" 2 "RIGHT" ;
VAL_ 579 VCRIGHT_tempDuctLeft 255 "SNA" ;
VAL_ 579 VCRIGHT_tempDuctLeftLower 255 "SNA" ;
VAL_ 579 VCRIGHT_tempDuctLeftUpper 255 "SNA" ;
VAL_ 579 VCRIGHT_tempDuctRight 255 "SNA" ;
VAL_ 579 VCRIGHT_tempDuctRightLower 255 "SNA" ;
VAL_ 579 VCRIGHT_tempDuctRightUpper 255 "SNA" ;
VAL_ 583 DAS_autopilotAbortReason 0 "NONE" 1 "WATCHDOG_HEALTH" 2 "DI_MIA" 3 "ESP_MIA" 4 "EPAS_MIA" 5 "GTW_MIA" 6 "SCCM_MIA" 7 "RADAR_MIA" 8 "VCFRONT_MIA" 9 "VCRIGHT_MIA" 10 "CRUISE_FAULT" 11 "CRUISE_NOT_ACTIVE" 12 "USER_DISABLED" 13 "TRAILER_MODE_ACTIVE" 14 "VEHICLE_SPEED_ABOVE_MAX" 15 "EPAS_EAC_NOT_ACTIVE" 16 "EPAS_EAC_ERROR" 17 "CAMERA_FAILSAFES" 18 "CAMERA_CALIBRATION" 19 "RADAR_BLIND" 20 "RADAR_FAULT" 21 "ACC_CANCEL_GENERIC" 22 "ACC_CANCEL_SILENT" 23 "ACC_FAULT" 24 "ROAD_ESTIMATOR_HEALTH" 25 "CONTROLLER_REFERENCE" 26 "CONTROLLER_SOLVER" 27 "CONTROLLER_NOT_ALLOWED" 28 "THERMAL_ISSUE" 29 "MAP_HEALTH" 30 "CONTROLLER_STALE_REFERENCE" 31 "CONTROLLER_STALE_LOCALIZATION" 32 "CONTROLLER_BAD_REF_UPDATE" 33 "AEB" 34 "CONTROLLER_REF_TOO_SHORT" 35 "MISSION_PLANNER_NO_VISION_LANES_FOUND" 36 "GORE_INCURSION" 37 "REACHED_END_OF_NAV_STOP" 63 "REASON_MAX" ;
VAL_ 583 DAS_behaviorReport 0 "MISSION_PLANNER" 1 "VIEW_RANGE" 2 "CURVE_SPEED_ADAPTATION" 3 "RADAR_ONLY_BRAKING" 4 "KEEP_CALM" 5 "FLEET_SPEEDS" 6 "TRAFFIC_CONTROL_STOPPED_STATE" 7 "UNDERTAKE_ASSIST_KEEP_CALM" 8 "IN_LANE_VEHICLE" 9 "TARGET_LANE_VEHICLE" 10 "UNDERTAKE_VEHICLE" 11 "TRAFFIC_CONTROL" 12 "VISION_LANE_GEOMETRY" 13 "MAP_LANE_GEOMETRY" 14 "DRIVABLE_SPACE_VIOLATION" 15 "SLOWING_FOR_TARGET_LANE" 16 "VISION_SPEEDS" 17 "NAV_FLEET_SPEEDS" 18 "NAV_PATH_CSA" 19 "MERGE_VEHICLE_LEFT" 20 "MERGE_VEHICLE_RIGHT" 21 "CUTIN_VEHICLE_LEFT" 22 "CUTIN_VEHICLE_RIGHT" ;
VAL_ 583 DAS_cameraContext 0 "SURROUND" 1 "LEFT_LANE_CHANGE" 2 "RIGHT_LANE_CHANGE" 3 "FORWARD_FACING" ;
VAL_ 583 DAS_controllerHealth 0 "HEALTHY" 1 "DEGRADED" 2 "CRITICAL" 3 "SOLVER_FAILURE" ;
VAL_ 583 DAS_controllerRef 0 "HEALTHY" 1 "UNHEALTHY" 2 "STALE_REFERENCE" 3 "STALE_LOCALIZATION" 4 "BAD_REF_UPDATE" 5 "REF_TOO_SHORT" 6 "INDETERMINATE" ;
VAL_ 583 DAS_forkState 0 "INVALID" 1 "UNAVAILABLE_DISABLED" 2 "UNAVAILABLE_AP_INACTIVE" 3 "UNAVAILABLE_CONSTRUCTION" 4 "UNAVAILABLE_CONTROLLED_ACCESS_TOO_FAR" 5 "UNAVAILABLE_DON_INACTIVE" 6 "UNAVAILABLE_TOLL_BOOTH" 7 "UNAVAILABLE_OTHER" 8 "IDLE_BOTH_FORKS_AVAILABLE" 9 "IDLE_LEFT_FORK_AVAILABLE" 10 "IDLE_RIGHT_FORK_AVAILABLE" 11 "IDLE_NO_FORKS_AVAILABLE" 12 "ACTIVE_LEFT_NAV" 13 "ACTIVE_LEFT_USER" 14 "ACTIVE_RIGHT_NAV" 15 "ACTIVE_RIGHT_USER" 16 "FORK_COMPLETE" 17 "ABORT_CONTROL_INACTIVE" 18 "ABORT_BLINKER_CHANGE" 19 "ABORT_NOT_LEFT_LANE" 20 "ABORT_NOT_RIGHT_LANE" 21 "ABORT_DISALLOW" 22 "ABORT_OTHER" 23 "UNAVAILABLE_TIGHT_TURN_RADIUS" 24 "UNAVAILABLE_WEATHER" ;
VAL_ 583 DAS_laneChangeState 19 "LANE_CHANGE_ABORTING_ACC_AUTOSTEER_ACTIVATED" 26 "LANE_CHANGE_ABORTING_ALC_REQUEST_BEFORE_ULC_CONFIRM" 23 "LANE_CHANGE_ABORTING_BEHAVIOR_CHANGED" 22 "LANE_CHANGE_ABORTING_BELOW_MIN_SPEED" 14 "LANE_CHANGE_ABORTING_BLIND_SPOT_OCCUPIED" 12 "LANE_CHANGE_ABORTING_BLINKER" 32 "LANE_CHANGE_ABORTING_CONSTRUCTION_DETECTED" 43 "LANE_CHANGE_ABORTING_DESTINATION_LANE_UNSTABLE" 17 "LANE_CHANGE_ABORTING_FORK_AVAILABLE" 31 "LANE_CHANGE_ABORTING_GORE_POINT" 24 "LANE_CHANGE_ABORTING_HIGH_ALC_PROGRESS_ERROR" 11 "LANE_CHANGE_ABORTING_INACTIVE" 21 "LANE_CHANGE_ABORTING_INVALID_BEHAVIOR" 15 "LANE_CHANGE_ABORTING_INVALID_MODE" 16 "LANE_CHANGE_ABORTING_LINE_TYPE" 18 "LANE_CHANGE_ABORTING_LOST_VISION_POSE" 37 "LANE_CHANGE_ABORTING_NO_HANDS_ON" 40 "LANE_CHANGE_ABORTING_SNOOZED" 39 "LANE_CHANGE_ABORTING_SOURCE_AND_TARGET_LANES_MERGED" 34 "LANE_CHANGE_ABORTING_TIGHT_TURN_RADIUS" 13 "LANE_CHANGE_ABORTING_TIMEOUT" 33 "LANE_CHANGE_ABORTING_TOLL_BOOTH_DETECTED" 20 "LANE_CHANGE_ABORTING_ULC_BLINKER_TIMEOUT" 25 "LANE_CHANGE_ABORTING_ULC_CONFIRMATION_TIMEOUT" 35 "LANE_CHANGE_ABORTING_WEATHER" 10 "LANE_CHANGE_AVAILABLE_BOTH" 8 "LANE_CHANGE_AVAILABLE_LEFT_ONLY" 9 "LANE_CHANGE_AVAILABLE_RIGHT_ONLY" 29 "LANE_CHANGE_BLOCKED_LEFT" 30 "LANE_CHANGE_BLOCKED_RIGHT" 27 "LANE_CHANGE_IN_PROGRESS_LEFT" 28 "LANE_CHANGE_IN_PROGRESS_RIGHT" 42 "LANE_CHANGE_UNAVAILABLE_AUTOPILOT_ABORTING" 36 "LANE_CHANGE_UNAVAILABLE_BLINDSPOT_RESTRICTED" 41 "LANE_CHANGE_UNAVAILABLE_BLINKER_LATCHED" 0 "LANE_CHANGE_UNAVAILABLE_DISABLED" 5 "LANE_CHANGE_UNAVAILABLE_FORK_MODE" 4 "LANE_CHANGE_UNAVAILABLE_INACTIVE" 7 "LANE_CHANGE_UNAVAILABLE_INVALID_MODE" 3 "LANE_CHANGE_UNAVAILABLE_NO_LANES" 38 "LANE_CHANGE_UNAVAILABLE_NO_REAR_OBJECT" 1 "LANE_CHANGE_UNAVAILABLE_ROAD_NOT_APPROPRIATE" 2 "LANE_CHANGE_UNAVAILABLE_SPEED" 6 "LANE_CHANGE_UNAVAILABLE_ULTRASONICS_NOT_READY" 63 "LANE_CHANGE_UNKNOWN" ;
VAL_ 583 DAS_lastWatchdogCode 68 "ACTIVE_SAFETY_FAILED" 51 "AP_STATE_MACHINE_FAILED" 50 "ARBITER_FAILED" 57 "ATLAS_FAILED" 79 "BEV_GRAPH_FAILED" 77 "BRIDGE_FAILED" 67 "CAMERA_FAILED" 45 "CAN_RX_FAILED" 46 "CAN_TX_FAILED" 78 "CITY_STREETS_BEHAVIOR_FAILED" 74 "CLIP_LOGGER_FAILED" 52 "CONTROLLER_FAILED" 75 "DRIVABLE_SPACE_TRACKER_FAILED" 65 "DRIVER_MONITOR_FAILED" 70 "DYNAMICS_FAILED" 71 "FIELD_CALIBRATION_FAILED" 49 "GPS_FAILED" 73 "HW_MONITOR_FAILED" 61 "IMU_FAILED" 48 "INERTIATOR_FAILED" 63 "LANE_CHANGE_BEHAVIOR_FAILED" 43 "LEGACY_FAILED" 53 "LOCALIZER_FAILED" 66 "MAP_MANAGER_FAILED" 54 "MISSION_PLANNER_FAILED" 0 "NO_TASK_FAILED" 72 "PARKING_BEHAVIOR_FAILED" 55 "PERCEPTION_FAILED" 60 "RAIN_LIGHT_SENSING_FAILED" 56 "ROAD_ESTIMATOR_FAILED" 76 "SCHEDULER_FAILED" 41 "SNAPSHOT_FAILED" 59 "SNAPSHOT_TRIGGER_CLIENT_FAILED" 58 "STAY_IN_LANE_BEHAVIOR_FAILED" 40 "TELEMETRY_FAILED" 39 "TELEMETRY_PACKAGER_FAILED" 47 "TEMPERATURE_MONITOR_FAILED" 62 "UBX_LOG_FAILED" 69 "UI_SERVER_FAILED" 80 "ULTRASONICS_FAILED" 30 "UNKNOWN_TASK_FAILED" 42 "VISION_FAILED" 44 "WATCHDOG_FAILED" ;
VAL_ 583 DAS_mapAvailability 0 "NOT_AVAILABLE" 1 "AVAILABLE" ;
VAL_ 583 DAS_roadEstimator 0 "HEALTHY" 1 "UNSTABLE_MEASUREMENTS" 2 "DEGRADED" 3 "CRITICAL" ;
VAL_ 583 DAS_rqstedBehaviorStatus 0 "VALID" 1 "NO_SRC_POLYLANE" 2 "NO_DEST_POLYLANE" 3 "MAP_NOT_INITIALIZED" 4 "NO_SOURCE_LANE_ON_MAP" 5 "NO_TARGET_LANE_ON_MAP" 6 "BUILD_ARGUMENT_FAIL" 7 "BLOCKED_BY_ULTRASOUND_L" 8 "BLOCKED_BY_BLINDSPOT_CAMERA_L" 9 "BLOCKED_BY_BLINDSPOT_CAMERA_INVALID_L" 10 "BLOCKED_BY_ULTRASOUND_AND_CAMERA_L" 11 "BLOCKED_BY_LANE_TYPE_L" 12 "BLOCKED_BY_ULTRASOUND_R" 13 "BLOCKED_BY_BLINDSPOT_CAMERA_R" 14 "BLOCKED_BY_BLINDSPOT_CAMERA_INVALID_R" 15 "BLOCKED_BY_ULTRASOUND_AND_CAMERA_R" 16 "BLOCKED_BY_LANE_TYPE_R" 17 "ROAD_NOT_APPROPRIATE" 18 "OUT_OF_DATE" 19 "BAD_ORIGIN_UPDATE" 20 "BLOCKED_BY_SLOW_TARGET_L" 21 "BLOCKED_BY_SLOW_TARGET_R" 22 "INVALID_PLAN" ;
VAL_ 585 SCCM_highBeamStalkStatus 0 "IDLE" 1 "PULL" 2 "PUSH" 3 "SNA" ;
VAL_ 585 SCCM_washWipeButtonStatus 0 "NOT_PRESSED" 1 "1ST_DETENT" 2 "2ND_DETENT" 3 "SNA" ;
VAL_ 585 SCCM_turnIndicatorStalkStatus 0 "IDLE" 2 "UP_1" 4 "UP_2" 7 "DOWN_1" 8 "DOWN_2" 5 "SNA" ;
VAL_ 586 DAS_accSmartSpeedState 0 "NOT_ACTIVE" 1 "ACTIVE_OFFRAMP" 2 "ACTIVE_INTEGRATING" 3 "ACTIVE_ONRAMP" 4 "SET_SPEED_SET_REQUESTED" 5 "OFFRAMP_DELAY" 7 "SNA" ;
VAL_ 586 DAS_autosteerBottsDotsUsage 0 "REJECTED_UNAVAILABLE" 1 "AVAILABLE" 2 "FUSED" 3 "BLACKLISTED" ;
VAL_ 586 DAS_autosteerHPPUsage 0 "REJECTED_UNAVAILABLE" 1 "AVAILABLE" 2 "FUSED" 3 "BLACKLISTED" ;
VAL_ 586 DAS_autosteerHealthState 0 "UNAVAILABLE" 1 "NOMINAL" 2 "DEGRADED" 3 "SEVERELY_DEGRADED" 4 "ABORTING" 5 "FAULT" ;
VAL_ 586 DAS_autosteerModelUsage 0 "REJECTED_UNAVAILABLE" 1 "AVAILABLE" 2 "FUSED" 3 "BLACKLISTED" ;
VAL_ 586 DAS_autosteerNavigationUsage 0 "REJECTED_UNAVAILABLE" 1 "AVAILABLE" 2 "FUSED" 3 "BLACKLISTED" ;
VAL_ 586 DAS_autosteerVehiclesUsage 0 "REJECTED_UNAVAILABLE" 1 "AVAILABLE" 2 "FUSED" 3 "BLACKLISTED" ;
VAL_ 586 DAS_behaviorType 0 "INVALID" 1 "IN_LANE" 2 "LANE_CHANGE_LEFT" 3 "LANE_CHANGE_RIGHT" ;
VAL_ 586 DAS_lastAutosteerAbortReason 0 "HM_LANE_VIEW_RANGE" 1 "HM_VIRTUAL_LANE_NO_INPUTS" 2 "HM_STEERING_ERROR" 14 "APP_ME_STATE_NOT_VISION" 15 "ME_MAIN_STATE_NOT_VISION" 16 "CAM_MSG_MIA" 17 "CAM_WATCHDOG" 18 "TRAILER_MODE" 19 "SIDE_COLLISION_IMMINENT" 20 "EPAS_EAC_DENIED" 21 "COMPONENT_MIA" 22 "CRUISE_FAULT" 23 "CID_SWITCH_DISABLED" 24 "DRIVING_OFF_NAV" 25 "VEHICLE_SPEED_ABOVE_MAX" 26 "FOLLOWER_OUTPUT_INVALID" 27 "PLANNER_OUTPUT_INVALID" 28 "EPAS_ERROR_CODE" 29 "ACC_CANCEL" 30 "CAMERA_FAILSAFES" 31 "NO_ABORT" 32 "AEB" ;
VAL_ 586 DAS_lastLinePreferenceReason 0 "OTHER_LANE_DISAGREES_WITH_MODEL" 1 "AGREEMENT_WITH_NEIGHBOR_LANES" 2 "NEIGHBOR_LANE_PROBABILIY" 3 "NAVIGATION_BRANCH" 4 "AVOID_ONCOMING_LANES" 5 "COUNTRY_DRIVING_SIDE" 15 "NONE" ;
VAL_ 586 DAS_navAvailable 0 "UNAVAILABLE" 1 "AVAILABLE" ;
VAL_ 586 DAS_offsetSide 0 "NO_OFFSET" 1 "OFFSET_RIGHT_OBJECT" 2 "OFFSET_LEFT_OBJECT" 3 "OFFSET_BOTH_OBJECTS" ;
VAL_ 586 DAS_plannerState 0 "DISABLED" 1 "VL" 2 "FOLLOW" 3 "LANECHANGE_REQUESTED" 4 "LANECHANGE_IN_PROGRESS" 5 "LANECHANGE_WAIT_FOR_SIDE_OBSTACLE" 6 "LANECHANGE_WAIT_FOR_FWD_OBSTACLE" 7 "LANECHANGE_ABORT" ;
VAL_ 586 DAS_roadSurfaceType 0 "SNA" 1 "NORMAL" 2 "ENHANCED" ;
VAL_ 586 DAS_ulcInProgress 0 "INACTIVE" 1 "ACTIVE" ;
VAL_ 586 DAS_ulcType 0 "NAV" 1 "SPEED" ;
VAL_ 586 DAS_rearLeftVehDetectedCurrent 1 "VEHICLE_DETECTED" 0 "VEHICLE_NOT_DETECTED" ;
VAL_ 586 DAS_rearLeftVehDetectedTrip 1 "VEHICLE_DETECTED" 0 "VEHICLE_NOT_DETECTED" ;
VAL_ 586 DAS_rearRightVehDetectedTrip 1 "VEHICLE_DETECTED" 0 "VEHICLE_NOT_DETECTED" ;
VAL_ 586 DAS_rearVehDetectedThisCycle 1 "VEHICLE_DETECTED" 0 "VEHICLE_NOT_DETECTED" ;
VAL_ 590 PARK_pscVehSlotType 0 "LEFT_PARALLEL" 1 "LEFT_CROSS" 2 "RIGHT_PARALLEL" 3 "RIGHT_CROSS" ;
VAL_ 590 PARK_pscLeftParallelVehX 2046 "NO_SPACE" 2047 "SNA" ;
VAL_ 590 PARK_pscLeftParallelVehY 2046 "NO_SPACE" 2047 "SNA" ;
VAL_ 590 PARK_pscLeftParallelPsi 8190 "NO_SPACE" 8191 "SNA" ;
VAL_ 590 PARK_pscLeftParallelSizeX 254 "NO_SPACE" 255 "SNA" ;
VAL_ 590 PARK_pscLeftParallelSizeY 254 "NO_SPACE" 255 "SNA" ;
VAL_ 590 PARK_pscLeftCrossVehX 2046 "NO_SPACE" 2047 "SNA" ;
VAL_ 590 PARK_pscLeftCrossVehY 2046 "NO_SPACE" 2047 "SNA" ;
VAL_ 590 PARK_pscLeftCrossPsi 8190 "NO_SPACE" 8191 "SNA" ;
VAL_ 590 PARK_pscLeftCrossSizeX 254 "NO_SPACE" 255 "SNA" ;
VAL_ 590 PARK_pscLeftCrossSizeY 254 "NO_SPACE" 255 "SNA" ;
VAL_ 590 PARK_pscRightParallelVehX 2046 "NO_SPACE" 2047 "SNA" ;
VAL_ 590 PARK_pscRightParallelVehY 2046 "NO_SPACE" 2047 "SNA" ;
VAL_ 590 PARK_pscRightParallelPsi 8190 "NO_SPACE" 8191 "SNA" ;
VAL_ 590 PARK_pscRightParallelSizeX 254 "NO_SPACE" 255 "SNA" ;
VAL_ 590 PARK_pscRightParallelSizeY 254 "NO_SPACE" 255 "SNA" ;
VAL_ 590 PARK_pscRightCrossVehX 2046 "NO_SPACE" 2047 "SNA" ;
VAL_ 590 PARK_pscRightCrossVehY 2046 "NO_SPACE" 2047 "SNA" ;
VAL_ 590 PARK_pscRightCrossPsi 8190 "NO_SPACE" 8191 "SNA" ;
VAL_ 590 PARK_pscRightCrossSizeX 254 "NO_SPACE" 255 "SNA" ;
VAL_ 590 PARK_pscRightCrossSizeY 254 "NO_SPACE" 255 "SNA" ;
VAL_ 594 BMS_powerLimitsState 0 "NOT_CALCULATED_FOR_DRIVE" 1 "CALCULATED_FOR_DRIVE" ;
VAL_ 595 UI_ventPanelLeftLateralMode 0 "SINGLE" 1 "SPLIT" ;
VAL_ 595 UI_ventPanelRightLateralMode 0 "SINGLE" 1 "SPLIT" ;
VAL_ 599 DI_uiSpeed 255 "SNA" ;
VAL_ 599 DI_uiSpeedUnits 0 "MPH" 1 "KPH" ;
VAL_ 599 DI_vehicleSpeed 4095 "SNA" ;
VAL_ 599 DI_uiSpeedHighSpeed 511 "DI_UI_HIGH_SPEED_SNA" ;
VAL_ 600 APB_watchdogState 0 "UNKNOWN" 1 "DEGRADED" 2 "CRITICAL" 3 "HEALTHY" 7 "SNA" ;
VAL_ 601 APP_watchdogState 0 "UNKNOWN" 1 "DEGRADED" 2 "CRITICAL" 3 "HEALTHY" 7 "SNA" ;
VAL_ 605 CP_UHF_controlState 0 "INIT" 1 "CONFIG" 2 "IDLE" 3 "CALIBRATE" 4 "PREPARE_RX" 5 "RX" 6 "CHECK_RX" 7 "READ_RXFIFO" 8 "HANDLE_FOUND" 9 "SLEEP" 10 "FAULT" ;
VAL_ 605 CP_chargeCablePresent 0 "NOT_PRESENT" 1 "PRESENT" ;
VAL_ 605 CP_chargeCableState 2 "CHARGE_CABLE_CONNECTED" 1 "CHARGE_CABLE_NOT_CONNECTED" 0 "CHARGE_CABLE_UNKNOWN_SNA" ;
VAL_ 605 CP_coldWeatherMode 1 "LATCH_MITIGATION" 0 "NONE" ;
VAL_ 605 CP_doorControlState 0 "doorInit" 1 "doorIdle" 2 "doorOpenRequested" 3 "doorOpening" 4 "doorSenseOpen" 5 "doorClosing" 6 "doorSenseClosed" ;
VAL_ 605 CP_faultLineSensed 0 "CLEARED" 1 "SET" ;
VAL_ 605 CP_inductiveDoorState 0 "INIT" 1 "INIT_FROM_CHARGE" 2 "INIT_FROM_DRIVE" 3 "PRESENT" 4 "NOT_PRESENT" 5 "OFF_DRIVE" 6 "OFF_CHARGE" ;
VAL_ 605 CP_inductiveSensorState 0 "INIT" 1 "POLL" 2 "SHUTDOWN" 3 "PAUSE" 4 "WAIT_FOR_INIT" 5 "FAULT" ;
VAL_ 605 CP_latch2ControlState 0 "latchInit" 1 "latchIdle" 2 "latchDisengageRequested" 3 "latchDisengaging" 4 "latchDisengaged" 5 "latchEngaging" ;
VAL_ 605 CP_latch2State 0 "SNA" 1 "DISENGAGED" 2 "ENGAGED" 3 "BLOCKING" ;
VAL_ 605 CP_latchControlState 0 "latchInit" 1 "latchIdle" 2 "latchDisengageRequested" 3 "latchDisengaging" 4 "latchDisengaged" 5 "latchEngaging" ;
VAL_ 605 CP_latchState 0 "SNA" 1 "DISENGAGED" 2 "ENGAGED" 3 "BLOCKING" ;
VAL_ 605 CP_ledColor 0 "OFF" 1 "RED" 2 "GREEN" 3 "BLUE" 4 "WHITE" 5 "FLASHING_GREEN" 6 "FLASHING_AMBER" 7 "AMBER" 8 "RAVE" 9 "DEBUG" 10 "FLASHING_BLUE" ;
VAL_ 605 CP_type 0 "US_TESLA" 1 "EURO_IEC" 2 "GB" 3 "IEC_CCS" ;
VAL_ 606 PARK_pscEnvSlotType 0 "LEFT_PARALLEL" 1 "LEFT_CROSS" 2 "RIGHT_PARALLEL" 3 "RIGHT_CROSS" ;
VAL_ 606 PARK_pscLeftParallelObj1X 2046 "NO_SPACE" 2047 "SNA" ;
VAL_ 606 PARK_pscLeftParallelObj1Y 2046 "NO_SPACE" 2047 "SNA" ;
VAL_ 606 PARK_pscLeftParallelObj1Alpha 126 "NO_SPACE" 127 "SNA" ;
VAL_ 606 PARK_pscLeftParallelObj2Y 2046 "NO_SPACE" 2047 "SNA" ;
VAL_ 606 PARK_pscLeftParallelObj2X 2046 "NO_SPACE" 2047 "SNA" ;
VAL_ 606 PARK_pscLeftParallelObj2Alpha 126 "NO_SPACE" 127 "SNA" ;
VAL_ 606 PARK_pscLeftCrossObj1X 2046 "NO_SPACE" 2047 "SNA" ;
VAL_ 606 PARK_pscLeftCrossObj1Y 2046 "NO_SPACE" 2047 "SNA" ;
VAL_ 606 PARK_pscLeftCrossObj1Alpha 126 "NO_SPACE" 127 "SNA" ;
VAL_ 606 PARK_pscLeftCrossObj2Y 2046 "NO_SPACE" 2047 "SNA" ;
VAL_ 606 PARK_pscLeftCrossObj2X 2046 "NO_SPACE" 2047 "SNA" ;
VAL_ 606 PARK_pscLeftCrossObj2Alpha 126 "NO_SPACE" 127 "SNA" ;
VAL_ 606 PARK_pscRightParallelObj1X 2046 "NO_SPACE" 2047 "SNA" ;
VAL_ 606 PARK_pscRightParallelObj1Y 2046 "NO_SPACE" 2047 "SNA" ;
VAL_ 606 PARK_pscRightParallelObj1Alpha 126 "NO_SPACE" 127 "SNA" ;
VAL_ 606 PARK_pscRightParallelObj2Y 2046 "NO_SPACE" 2047 "SNA" ;
VAL_ 606 PARK_pscRightParallelObj2X 2046 "NO_SPACE" 2047 "SNA" ;
VAL_ 606 PARK_pscRightParallelObj2Alpha 126 "NO_SPACE" 127 "SNA" ;
VAL_ 606 PARK_pscRightCrossObj1X 2046 "NO_SPACE" 2047 "SNA" ;
VAL_ 606 PARK_pscRightCrossObj1Y 2046 "NO_SPACE" 2047 "SNA" ;
VAL_ 606 PARK_pscRightCrossObj1Alpha 126 "NO_SPACE" 127 "SNA" ;
VAL_ 606 PARK_pscRightCrossObj2Y 2046 "NO_SPACE" 2047 "SNA" ;
VAL_ 606 PARK_pscRightCrossObj2X 2046 "NO_SPACE" 2047 "SNA" ;
VAL_ 606 PARK_pscRightCrossObj2Alpha 126 "NO_SPACE" 127 "SNA" ;
VAL_ 609 VCFRONT_IBSTemperature 32767 "VCFRONT_IBS_TEMPERATURE_SNA" ;
VAL_ 609 VCFRONT_batterySMState 0 "INIT" 1 "CHARGE" 2 "DISCHARGE" 3 "STANDBY" 4 "RESISTANCE_ESTIMATION" 5 "OTA_STANDBY" 6 "DISCONNECTED_BATTERY_TEST" 7 "SHORTED_CELL_TEST" 8 "FAULT" 9 "RECOVERY" ;
VAL_ 609 VCFRONT_voltageProfile 0 "CHARGE" 1 "FLOAT" 2 "REDUCED_FLOAT" 3 "ALWAYS_CLOSED_CONTACTORS" ;
VAL_ 610 VCLEFT_steeringColumnLastRequest 0 "SNA" 1 "NONE" 2 "UP" 3 "DOWN" 4 "IN" 5 "OUT" ;
VAL_ 610 VCLEFT_steeringColumnSMState 0 "SNA" 1 "RECALL" 2 "CALIBRATE" 3 "MANUAL_CONTROL" ;
VAL_ 611 VCRIGHT_logging10HzIndex 0 "HVAC_ACTUATOR_TARGETS" 1 "HVAC_ACTUATOR_POSITIONS" 2 "HVAC_ACTUATOR_STATE" 3 "END" ;
VAL_ 611 VCRIGHT_evapPulldownBias 255 "SNA" ;
VAL_ 611 VCRIGHT_hvacIntakeActuatorState 0 "BRAKING" 1 "RUNNING" 2 "COASTING" ;
VAL_ 611 VCRIGHT_hvacIntakeOperationMode 0 "NORMAL" 1 "CALIBRATION" ;
VAL_ 611 VCRIGHT_hvacLHBleedActuatorState 0 "BRAKING" 1 "RUNNING" 2 "COASTING" ;
VAL_ 611 VCRIGHT_hvacLHBleedOperationMode 0 "NORMAL" 1 "CALIBRATION" ;
VAL_ 611 VCRIGHT_hvacLHVaneActuatorState 0 "BRAKING" 1 "RUNNING" 2 "COASTING" ;
VAL_ 611 VCRIGHT_hvacLHVaneOperationMode 0 "NORMAL" 1 "CALIBRATION" ;
VAL_ 611 VCRIGHT_hvacLowerModeActState 0 "BRAKING" 1 "RUNNING" 2 "COASTING" ;
VAL_ 611 VCRIGHT_hvacLowerModeOpMode 0 "NORMAL" 1 "CALIBRATION" ;
VAL_ 611 VCRIGHT_hvacRHBleedActuatorState 0 "BRAKING" 1 "RUNNING" 2 "COASTING" ;
VAL_ 611 VCRIGHT_hvacRHBleedOperationMode 0 "NORMAL" 1 "CALIBRATION" ;
VAL_ 611 VCRIGHT_hvacRHVaneActuatorState 0 "BRAKING" 1 "RUNNING" 2 "COASTING" ;
VAL_ 611 VCRIGHT_hvacRHVaneOperationMode 0 "NORMAL" 1 "CALIBRATION" ;
VAL_ 611 VCRIGHT_hvacUpperModeActState 0 "BRAKING" 1 "RUNNING" 2 "COASTING" ;
VAL_ 611 VCRIGHT_hvacUpperModeOpMode 0 "NORMAL" 1 "CALIBRATION" ;
VAL_ 614 DI_elecPower 1024 "SNA" ;
VAL_ 615 DI_massConfidence 1 "MASS_CONFIDED" 0 "MASS_NOT_CONFIDED" ;
VAL_ 615 DI_relativeTireTreadDepth 32 "SNA" ;
VAL_ 615 DI_tireFitment 3 "FITMENT_SNA" 0 "FITMENT_SQUARE" 1 "FITMENT_STAGGERED" ;
VAL_ 615 DI_trailerDetected 1 "TRAILER_DETECTED" 0 "TRAILER_NOT_DETECTED" ;
VAL_ 616 DI_sysDrivePowerMax 511 "SNA" ;
VAL_ 616 DI_sysRegenPowerMax 155 "SNA" ;
VAL_ 616 DI_primaryUnitSiliconType 1 "IGBT" 0 "MOSFET" ;
VAL_ 616 DI_primaryUnitSiliconType 1 "IGBT" 0 "MOSFET" ;
VAL_ 626 VCLEFT_epbmDebugIndex 0 "STATES" 1 "TRANSITIONS" ;
VAL_ 626 VCLEFT_epbmCaliperState 0 "UNSAVED" 1 "UNKNOWN" 2 "REAPPLY" 3 "PARK" 4 "OPEN" 5 "SERVICE" ;
VAL_ 626 VCLEFT_summonFaultReason 0 "NONE" 1 "DI_MIA" 2 "DAS_MIA" 3 "ESP_MIA" 4 "EPBM_MIA" 5 "DI_FAULT" 6 "DI_APC_FAULT" 7 "DAS_FAULT" 8 "ESP_FAULT" 9 "VEH_CAN_FAULT" 10 "EAC_NOT_ALLOWED" 11 "EPBM_REQUEST" 12 "SPEED" 13 "EXTERNAL" 14 "PARK_MIA" 15 "PM_MIA" 16 "PM_REQUEST" 17 "OOC" 18 "MISMATCH" 19 "EPB_FAULT" 20 "DI_STATE_INVALID" 21 "PASSIVE_REQUEST" 22 "EPBREMOTE_MIA" 23 "REMOTE_SUMMON_FAULTED" 24 "LOCAL_UNIT_FAULTED" 25 "REMOTE_UNIT_FAULTED" 26 "START_IN_UNAVAILABLE" 27 "INVALID_REMOTE_STATE" 28 "REMOTE_DID_NOT_START" ;
VAL_ 626 VCLEFT_epbSummonState 0 "INIT" 1 "IDLE" 2 "ARMED" 3 "ACTIVE" 4 "COMPLETE" 5 "FAULT" 6 "UNAVAILABLE" ;
VAL_ 626 VCLEFT_epbmSummonState 0 "INIT" 1 "IDLE" 2 "ARMED" 3 "ACTIVE" 4 "COMPLETE" 5 "FAULT" 6 "UNAVAILABLE" ;
VAL_ 626 VCLEFT_epbmUnitStatus 0 "UNKNOWN" 1 "OPEN" 2 "DYNAMIC" 3 "PARK" 4 "START" 5 "SERVICE" 6 "WINCHMODE" 7 "WINCHMODE_RELEASING" 8 "PARKING" 9 "DYNAMIC_APPLYING" 10 "RELEASING" 11 "SERVICE_RELEASING" 12 "PARK_PENDING" 13 "WINCHMODE_PENDING" 14 "SUMMON" 15 "SUMMON_RELEASING" 16 "SUMMON_PARKING" 17 "EXTERNAL_DYNAMIC" 18 "RELEASING_FOR_EXTERNAL_PARK" 19 "EXTERNAL_PARKING" 20 "DYNAMIC_PARKING" 21 "COUNT" ;
VAL_ 626 VCLEFT_epbUnitStatus 0 "UNKNOWN" 1 "OPEN" 2 "DYNAMIC" 3 "PARK" 4 "START" 5 "SERVICE" 6 "WINCHMODE" 7 "WINCHMODE_RELEASING" 8 "PARKING" 9 "DYNAMIC_APPLYING" 10 "RELEASING" 11 "SERVICE_RELEASING" 12 "PARK_PENDING" 13 "WINCHMODE_PENDING" 14 "SUMMON" 15 "SUMMON_RELEASING" 16 "SUMMON_PARKING" 17 "EXTERNAL_DYNAMIC" 18 "RELEASING_FOR_EXTERNAL_PARK" 19 "EXTERNAL_PARKING" 20 "DYNAMIC_PARKING" 21 "COUNT" ;
VAL_ 626 VCLEFT_epbmFaultStatus 0 "NOMINAL" 1 "RETRY" 2 "FAULT" 3 "FAULT_IDLE" ;
VAL_ 626 VCLEFT_epbFaultStatus 0 "NOMINAL" 1 "RETRY" 2 "FAULT" 3 "FAULT_IDLE" ;
VAL_ 626 VCLEFT_cdpEnumDummy 0 "IDLE" 1 "VALID" 2 "INVALID" ;
VAL_ 627 UI_displayBrightnessLevel 255 "SNA" ;
VAL_ 627 UI_domeLightSwitch 0 "OFF" 1 "ON" 2 "AUTO" ;
VAL_ 627 UI_driveStateRequest 0 "IDLE" 1 "START" ;
VAL_ 627 UI_frontLeftSeatHeatReq 0 "OFF" 1 "LEVEL1" 2 "LEVEL2" 3 "LEVEL3" ;
VAL_ 627 UI_frontRightSeatHeatReq 0 "OFF" 1 "LEVEL1" 2 "LEVEL2" 3 "LEVEL3" ;
VAL_ 627 UI_lightSwitch 0 "AUTO_SNA" 1 "ON" 2 "PARKING" 3 "OFF" ;
VAL_ 627 UI_lockRequest 0 "IDLE" 1 "LOCK" 2 "UNLOCK" 3 "REMOTE_UNLOCK" 4 "REMOTE_LOCK" 7 "SNA" ;
VAL_ 627 UI_mirrorFoldRequest 0 "IDLE" 1 "RETRACT" 2 "PRESENT" 3 "SNA" ;
VAL_ 627 UI_rearCenterSeatHeatReq 0 "OFF" 1 "LEVEL1" 2 "LEVEL2" 3 "LEVEL3" ;
VAL_ 627 UI_rearLeftSeatHeatReq 0 "OFF" 1 "LEVEL1" 2 "LEVEL2" 3 "LEVEL3" ;
VAL_ 627 UI_rearRightSeatHeatReq 0 "OFF" 1 "LEVEL1" 2 "LEVEL2" 3 "LEVEL3" ;
VAL_ 627 UI_remoteClosureRequest 0 "IDLE" 1 "REAR_TRUNK_MOVE" 2 "FRONT_TRUNK_MOVE" 3 "SNA" ;
VAL_ 627 UI_remoteStartRequest 0 "IDLE" 1 "START" 4 "SNA" ;
VAL_ 627 UI_steeringBacklightEnabled 0 "DISABLED" 1 "ENABLED" ;
VAL_ 627 UI_steeringButtonMode 0 "OFF" 1 "STEERING_COLUMN_ADJ" 2 "MIRROR_LEFT" 3 "MIRROR_RIGHT" 4 "HEADLIGHT_LEFT" 5 "HEADLIGHT_RIGHT" ;
VAL_ 627 UI_wiperMode 0 "SNA" 1 "SERVICE" 2 "NORMAL" 3 "PARK" ;
VAL_ 627 UI_wiperRequest 0 "SNA" 1 "OFF" 2 "AUTO" 3 "SLOW_INTERMITTENT" 4 "FAST_INTERMITTENT" 5 "SLOW_CONTINUOUS" 6 "FAST_CONTINUOUS" ;
VAL_ 632 UI_roadCurvHealth 0 "UNAVAILABLE" 1 "DEGRADED" 2 "AVAILABLE" 3 "DATABASE" ;
VAL_ 637 APS_eacAllow 0 "INHIBIT" 1 "ALLOW" 2 "RESERVED" 3 "SNA" ;
VAL_ 642 VCLEFT_blowerIndex 0 "FEEDBACK_SIGNALS" 1 "VARS" ;
VAL_ 642 VCLEFT_hvacBlowerOutputDuty 127 "SNA" ;
VAL_ 642 VCLEFT_hvacBlowerRPMTarget 1023 "SNA" ;
VAL_ 642 VCLEFT_hvacBlowerTorque 128 "SNA" ;
VAL_ 642 VCLEFT_hvacBlowerFETTemp 255 "SNA" ;
VAL_ 642 VCLEFT_hvacBlowerITerm 255 "SNA" ;
VAL_ 642 VCLEFT_hvacBlowerRs 255 "SNA" ;
VAL_ 642 VCLEFT_hvacBlowerIPhase0 255 "SNA" ;
VAL_ 642 VCLEFT_hvacBlowerIPhase1 255 "SNA" ;
VAL_ 642 VCLEFT_hvacBlowerIPhase2 255 "SNA" ;
VAL_ 642 VCLEFT_hvacBlowerCBCCtrlState 4 "COUNT" 0 "ERROR" 1 "IDLE" 2 "OFFLINE" 3 "ONLINE" ;
VAL_ 642 VCLEFT_hvacBlowerCBCEstState 14 "COUNT" 0 "ERROR" 1 "IDLE" 5 "IDRATED" 10 "INDUCTANCE_EST" 9 "LOCKROTOR" 12 "MOTOR_IDENTIFIED" 13 "ONLINE" 8 "RAMPDOWN" 4 "RAMPUP" 7 "RATEDFLUX" 6 "RATEDFLUX_OL" 11 "ROTOR_RESISTANCE" 2 "ROVERL" 3 "RS" ;
VAL_ 642 VCLEFT_hvacBlower_IO_CBC_Status 0 "IDLE" 1 "RX" ;
VAL_ 644 UI_factoryMode 0 "DISABLED" 1 "ENABLED" ;
VAL_ 644 UI_serviceMode 0 "DISABLED" 1 "ENABLED" ;
VAL_ 644 UI_showroomMode 0 "DISABLED" 1 "ENABLED" ;
VAL_ 644 UI_transportMode 0 "DISABLED" 1 "ENABLED" ;
VAL_ 645 UI_driverProfileRecallIndex 0 "SNA" 1 "1" 2 "2" 3 "3" 4 "4" 5 "5" ;
VAL_ 645 UI_leftBackrestSwitchUp 0 "SNA" 1 "OFF" 2 "ON" 3 "FAULT" ;
VAL_ 645 UI_leftBackrestSwitchDown 0 "SNA" 1 "OFF" 2 "ON" 3 "FAULT" ;
VAL_ 645 UI_leftLiftSwitchUp 0 "SNA" 1 "OFF" 2 "ON" 3 "FAULT" ;
VAL_ 645 UI_leftLiftSwitchDown 0 "SNA" 1 "OFF" 2 "ON" 3 "FAULT" ;
VAL_ 645 UI_rightBackrestSwitchUp 0 "SNA" 1 "OFF" 2 "ON" 3 "FAULT" ;
VAL_ 645 UI_rightBackrestSwitchDown 0 "SNA" 1 "OFF" 2 "ON" 3 "FAULT" ;
VAL_ 645 UI_rightLiftSwitchUp 0 "SNA" 1 "OFF" 2 "ON" 3 "FAULT" ;
VAL_ 645 UI_rightLiftSwitchDown 0 "SNA" 1 "OFF" 2 "ON" 3 "FAULT" ;
